VERSION ""

NS_ :

BS_:

BU_: BMS CVC_P EVCC FMCU RMCU POD_GW PCU ADCU_P DUMMY_ECU

BO_ 1555 BMS_DiagResp: 64 BMS
 SG_ BMS_DiagRespData0 : 7|8@0+ (1,0) [0|255] ""  CVC_P
 SG_ BMS_DiagRespData1 : 15|8@0+ (1,0) [0|255] ""  CVC_P
 SG_ BMS_DiagRespData2 : 23|8@0+ (1,0) [0|255] ""  CVC_P
 SG_ BMS_DiagRespData3 : 31|8@0+ (1,0) [0|255] ""  CVC_P
 SG_ BMS_DiagRespData4 : 39|8@0+ (1,0) [0|255] ""  CVC_P
 SG_ BMS_DiagRespData5 : 47|8@0+ (1,0) [0|255] ""  CVC_P
 SG_ BMS_DiagRespData6 : 55|8@0+ (1,0) [0|255] ""  CVC_P
 SG_ BMS_DiagRespData7 : 63|8@0+ (1,0) [0|255] ""  CVC_P
 SG_ BMS_DiagRespData8 : 71|8@0+ (1,0) [0|255] ""  CVC_P
 SG_ BMS_DiagRespData9 : 79|8@0+ (1,0) [0|255] ""  CVC_P
 SG_ BMS_DiagRespData10 : 87|8@0+ (1,0) [0|255] ""  CVC_P
 SG_ BMS_DiagRespData11 : 95|8@0+ (1,0) [0|255] ""  CVC_P
 SG_ BMS_DiagRespData12 : 103|8@0+ (1,0) [0|255] ""  CVC_P
 SG_ BMS_DiagRespData13 : 111|8@0+ (1,0) [0|255] ""  CVC_P
 SG_ BMS_DiagRespData14 : 119|8@0+ (1,0) [0|255] ""  CVC_P
 SG_ BMS_DiagRespData15 : 127|8@0+ (1,0) [0|255] ""  CVC_P
 SG_ BMS_DiagRespData16 : 135|8@0+ (1,0) [0|255] ""  CVC_P
 SG_ BMS_DiagRespData17 : 143|8@0+ (1,0) [0|255] ""  CVC_P
 SG_ BMS_DiagRespData18 : 151|8@0+ (1,0) [0|255] ""  CVC_P
 SG_ BMS_DiagRespData19 : 159|8@0+ (1,0) [0|255] ""  CVC_P
 SG_ BMS_DiagRespData20 : 167|8@0+ (1,0) [0|255] ""  CVC_P
 SG_ BMS_DiagRespData21 : 175|8@0+ (1,0) [0|255] ""  CVC_P
 SG_ BMS_DiagRespData22 : 183|8@0+ (1,0) [0|255] ""  CVC_P
 SG_ BMS_DiagRespData23 : 191|8@0+ (1,0) [0|255] ""  CVC_P
 SG_ BMS_DiagRespData24 : 199|8@0+ (1,0) [0|255] ""  CVC_P
 SG_ BMS_DiagRespData25 : 207|8@0+ (1,0) [0|255] ""  CVC_P
 SG_ BMS_DiagRespData26 : 215|8@0+ (1,0) [0|255] ""  CVC_P
 SG_ BMS_DiagRespData27 : 223|8@0+ (1,0) [0|255] ""  CVC_P
 SG_ BMS_DiagRespData28 : 231|8@0+ (1,0) [0|255] ""  CVC_P
 SG_ BMS_DiagRespData29 : 239|8@0+ (1,0) [0|255] ""  CVC_P
 SG_ BMS_DiagRespData30 : 247|8@0+ (1,0) [0|255] ""  CVC_P
 SG_ BMS_DiagRespData31 : 255|8@0+ (1,0) [0|255] ""  CVC_P
 SG_ BMS_DiagRespData32 : 263|8@0+ (1,0) [0|255] ""  CVC_P
 SG_ BMS_DiagRespData33 : 271|8@0+ (1,0) [0|255] ""  CVC_P
 SG_ BMS_DiagRespData34 : 279|8@0+ (1,0) [0|255] ""  CVC_P
 SG_ BMS_DiagRespData35 : 287|8@0+ (1,0) [0|255] ""  CVC_P
 SG_ BMS_DiagRespData36 : 295|8@0+ (1,0) [0|255] ""  CVC_P
 SG_ BMS_DiagRespData37 : 303|8@0+ (1,0) [0|255] ""  CVC_P
 SG_ BMS_DiagRespData38 : 311|8@0+ (1,0) [0|255] ""  CVC_P
 SG_ BMS_DiagRespData39 : 319|8@0+ (1,0) [0|255] ""  CVC_P
 SG_ BMS_DiagRespData40 : 327|8@0+ (1,0) [0|255] ""  CVC_P
 SG_ BMS_DiagRespData41 : 335|8@0+ (1,0) [0|255] ""  CVC_P
 SG_ BMS_DiagRespData42 : 343|8@0+ (1,0) [0|255] ""  CVC_P
 SG_ BMS_DiagRespData43 : 351|8@0+ (1,0) [0|255] ""  CVC_P
 SG_ BMS_DiagRespData44 : 359|8@0+ (1,0) [0|255] ""  CVC_P
 SG_ BMS_DiagRespData45 : 367|8@0+ (1,0) [0|255] ""  CVC_P
 SG_ BMS_DiagRespData46 : 375|8@0+ (1,0) [0|255] ""  CVC_P
 SG_ BMS_DiagRespData47 : 383|8@0+ (1,0) [0|255] ""  CVC_P
 SG_ BMS_DiagRespData48 : 391|8@0+ (1,0) [0|255] ""  CVC_P
 SG_ BMS_DiagRespData49 : 399|8@0+ (1,0) [0|255] ""  CVC_P
 SG_ BMS_DiagRespData50 : 407|8@0+ (1,0) [0|255] ""  CVC_P
 SG_ BMS_DiagRespData51 : 415|8@0+ (1,0) [0|255] ""  CVC_P
 SG_ BMS_DiagRespData52 : 423|8@0+ (1,0) [0|255] ""  CVC_P
 SG_ BMS_DiagRespData53 : 431|8@0+ (1,0) [0|255] ""  CVC_P
 SG_ BMS_DiagRespData54 : 439|8@0+ (1,0) [0|255] ""  CVC_P
 SG_ BMS_DiagRespData55 : 447|8@0+ (1,0) [0|255] ""  CVC_P
 SG_ BMS_DiagRespData56 : 455|8@0+ (1,0) [0|255] ""  CVC_P
 SG_ BMS_DiagRespData57 : 463|8@0+ (1,0) [0|255] ""  CVC_P
 SG_ BMS_DiagRespData58 : 471|8@0+ (1,0) [0|255] ""  CVC_P
 SG_ BMS_DiagRespData59 : 479|8@0+ (1,0) [0|255] ""  CVC_P
 SG_ BMS_DiagRespData60 : 487|8@0+ (1,0) [0|255] ""  CVC_P
 SG_ BMS_DiagRespData61 : 495|8@0+ (1,0) [0|255] ""  CVC_P
 SG_ BMS_DiagRespData62 : 503|8@0+ (1,0) [0|255] ""  CVC_P
 SG_ BMS_DiagRespData63 : 511|8@0+ (1,0) [0|255] ""  CVC_P

BO_ 1690 RMCU_DiagReq: 64 CVC_P
 SG_ RMCU_DiagReqData0 : 7|8@0+ (1,0) [0|255] ""  RMCU
 SG_ RMCU_DiagReqData1 : 15|8@0+ (1,0) [0|255] ""  RMCU
 SG_ RMCU_DiagReqData2 : 23|8@0+ (1,0) [0|255] ""  RMCU
 SG_ RMCU_DiagReqData3 : 31|8@0+ (1,0) [0|255] ""  RMCU
 SG_ RMCU_DiagReqData4 : 39|8@0+ (1,0) [0|255] ""  RMCU
 SG_ RMCU_DiagReqData5 : 47|8@0+ (1,0) [0|255] ""  RMCU
 SG_ RMCU_DiagReqData6 : 55|8@0+ (1,0) [0|255] ""  RMCU
 SG_ RMCU_DiagReqData7 : 63|8@0+ (1,0) [0|255] ""  RMCU
 SG_ RMCU_DiagReqData8 : 71|8@0+ (1,0) [0|255] ""  RMCU
 SG_ RMCU_DiagReqData9 : 79|8@0+ (1,0) [0|255] ""  RMCU
 SG_ RMCU_DiagReqData10 : 87|8@0+ (1,0) [0|255] ""  RMCU
 SG_ RMCU_DiagReqData11 : 95|8@0+ (1,0) [0|255] ""  RMCU
 SG_ RMCU_DiagReqData12 : 103|8@0+ (1,0) [0|255] ""  RMCU
 SG_ RMCU_DiagReqData13 : 111|8@0+ (1,0) [0|255] ""  RMCU
 SG_ RMCU_DiagReqData14 : 119|8@0+ (1,0) [0|255] ""  RMCU
 SG_ RMCU_DiagReqData15 : 127|8@0+ (1,0) [0|255] ""  RMCU
 SG_ RMCU_DiagReqData16 : 135|8@0+ (1,0) [0|255] ""  RMCU
 SG_ RMCU_DiagReqData17 : 143|8@0+ (1,0) [0|255] ""  RMCU
 SG_ RMCU_DiagReqData18 : 151|8@0+ (1,0) [0|255] ""  RMCU
 SG_ RMCU_DiagReqData19 : 159|8@0+ (1,0) [0|255] ""  RMCU
 SG_ RMCU_DiagReqData20 : 167|8@0+ (1,0) [0|255] ""  RMCU
 SG_ RMCU_DiagReqData21 : 175|8@0+ (1,0) [0|255] ""  RMCU
 SG_ RMCU_DiagReqData22 : 183|8@0+ (1,0) [0|255] ""  RMCU
 SG_ RMCU_DiagReqData23 : 191|8@0+ (1,0) [0|255] ""  RMCU
 SG_ RMCU_DiagReqData24 : 199|8@0+ (1,0) [0|255] ""  RMCU
 SG_ RMCU_DiagReqData25 : 207|8@0+ (1,0) [0|255] ""  RMCU
 SG_ RMCU_DiagReqData26 : 215|8@0+ (1,0) [0|255] ""  RMCU
 SG_ RMCU_DiagReqData27 : 223|8@0+ (1,0) [0|255] ""  RMCU
 SG_ RMCU_DiagReqData28 : 231|8@0+ (1,0) [0|255] ""  RMCU
 SG_ RMCU_DiagReqData29 : 239|8@0+ (1,0) [0|255] ""  RMCU
 SG_ RMCU_DiagReqData30 : 247|8@0+ (1,0) [0|255] ""  RMCU
 SG_ RMCU_DiagReqData31 : 255|8@0+ (1,0) [0|255] ""  RMCU
 SG_ RMCU_DiagReqData32 : 263|8@0+ (1,0) [0|255] ""  RMCU
 SG_ RMCU_DiagReqData33 : 271|8@0+ (1,0) [0|255] ""  RMCU
 SG_ RMCU_DiagReqData34 : 279|8@0+ (1,0) [0|255] ""  RMCU
 SG_ RMCU_DiagReqData35 : 287|8@0+ (1,0) [0|255] ""  RMCU
 SG_ RMCU_DiagReqData36 : 295|8@0+ (1,0) [0|255] ""  RMCU
 SG_ RMCU_DiagReqData37 : 303|8@0+ (1,0) [0|255] ""  RMCU
 SG_ RMCU_DiagReqData38 : 311|8@0+ (1,0) [0|255] ""  RMCU
 SG_ RMCU_DiagReqData39 : 319|8@0+ (1,0) [0|255] ""  RMCU
 SG_ RMCU_DiagReqData40 : 327|8@0+ (1,0) [0|255] ""  RMCU
 SG_ RMCU_DiagReqData41 : 335|8@0+ (1,0) [0|255] ""  RMCU
 SG_ RMCU_DiagReqData42 : 343|8@0+ (1,0) [0|255] ""  RMCU
 SG_ RMCU_DiagReqData43 : 351|8@0+ (1,0) [0|255] ""  RMCU
 SG_ RMCU_DiagReqData44 : 359|8@0+ (1,0) [0|255] ""  RMCU
 SG_ RMCU_DiagReqData45 : 367|8@0+ (1,0) [0|255] ""  RMCU
 SG_ RMCU_DiagReqData46 : 375|8@0+ (1,0) [0|255] ""  RMCU
 SG_ RMCU_DiagReqData47 : 383|8@0+ (1,0) [0|255] ""  RMCU
 SG_ RMCU_DiagReqData48 : 391|8@0+ (1,0) [0|255] ""  RMCU
 SG_ RMCU_DiagReqData49 : 399|8@0+ (1,0) [0|255] ""  RMCU
 SG_ RMCU_DiagReqData50 : 407|8@0+ (1,0) [0|255] ""  RMCU
 SG_ RMCU_DiagReqData51 : 415|8@0+ (1,0) [0|255] ""  RMCU
 SG_ RMCU_DiagReqData52 : 423|8@0+ (1,0) [0|255] ""  RMCU
 SG_ RMCU_DiagReqData53 : 431|8@0+ (1,0) [0|255] ""  RMCU
 SG_ RMCU_DiagReqData54 : 439|8@0+ (1,0) [0|255] ""  RMCU
 SG_ RMCU_DiagReqData55 : 447|8@0+ (1,0) [0|255] ""  RMCU
 SG_ RMCU_DiagReqData56 : 455|8@0+ (1,0) [0|255] ""  RMCU
 SG_ RMCU_DiagReqData57 : 463|8@0+ (1,0) [0|255] ""  RMCU
 SG_ RMCU_DiagReqData58 : 471|8@0+ (1,0) [0|255] ""  RMCU
 SG_ RMCU_DiagReqData59 : 479|8@0+ (1,0) [0|255] ""  RMCU
 SG_ RMCU_DiagReqData60 : 487|8@0+ (1,0) [0|255] ""  RMCU
 SG_ RMCU_DiagReqData61 : 495|8@0+ (1,0) [0|255] ""  RMCU
 SG_ RMCU_DiagReqData62 : 503|8@0+ (1,0) [0|255] ""  RMCU
 SG_ RMCU_DiagReqData63 : 511|8@0+ (1,0) [0|255] ""  RMCU

BO_ 1562 RMCU_DiagResp: 64 RMCU
 SG_ RMCU_DiagRespData0 : 7|8@0+ (1,0) [0|255] ""  CVC_P
 SG_ RMCU_DiagRespData1 : 15|8@0+ (1,0) [0|255] ""  CVC_P
 SG_ RMCU_DiagRespData2 : 23|8@0+ (1,0) [0|255] ""  CVC_P
 SG_ RMCU_DiagRespData3 : 31|8@0+ (1,0) [0|255] ""  CVC_P
 SG_ RMCU_DiagRespData4 : 39|8@0+ (1,0) [0|255] ""  CVC_P
 SG_ RMCU_DiagRespData5 : 47|8@0+ (1,0) [0|255] ""  CVC_P
 SG_ RMCU_DiagRespData6 : 55|8@0+ (1,0) [0|255] ""  CVC_P
 SG_ RMCU_DiagRespData7 : 63|8@0+ (1,0) [0|255] ""  CVC_P
 SG_ RMCU_DiagRespData8 : 71|8@0+ (1,0) [0|255] ""  CVC_P
 SG_ RMCU_DiagRespData9 : 79|8@0+ (1,0) [0|255] ""  CVC_P
 SG_ RMCU_DiagRespData10 : 87|8@0+ (1,0) [0|255] ""  CVC_P
 SG_ RMCU_DiagRespData11 : 95|8@0+ (1,0) [0|255] ""  CVC_P
 SG_ RMCU_DiagRespData12 : 103|8@0+ (1,0) [0|255] ""  CVC_P
 SG_ RMCU_DiagRespData13 : 111|8@0+ (1,0) [0|255] ""  CVC_P
 SG_ RMCU_DiagRespData14 : 119|8@0+ (1,0) [0|255] ""  CVC_P
 SG_ RMCU_DiagRespData15 : 127|8@0+ (1,0) [0|255] ""  CVC_P
 SG_ RMCU_DiagRespData16 : 135|8@0+ (1,0) [0|255] ""  CVC_P
 SG_ RMCU_DiagRespData17 : 143|8@0+ (1,0) [0|255] ""  CVC_P
 SG_ RMCU_DiagRespData18 : 151|8@0+ (1,0) [0|255] ""  CVC_P
 SG_ RMCU_DiagRespData19 : 159|8@0+ (1,0) [0|255] ""  CVC_P
 SG_ RMCU_DiagRespData20 : 167|8@0+ (1,0) [0|255] ""  CVC_P
 SG_ RMCU_DiagRespData21 : 175|8@0+ (1,0) [0|255] ""  CVC_P
 SG_ RMCU_DiagRespData22 : 183|8@0+ (1,0) [0|255] ""  CVC_P
 SG_ RMCU_DiagRespData23 : 191|8@0+ (1,0) [0|255] ""  CVC_P
 SG_ RMCU_DiagRespData24 : 199|8@0+ (1,0) [0|255] ""  CVC_P
 SG_ RMCU_DiagRespData25 : 207|8@0+ (1,0) [0|255] ""  CVC_P
 SG_ RMCU_DiagRespData26 : 215|8@0+ (1,0) [0|255] ""  CVC_P
 SG_ RMCU_DiagRespData27 : 223|8@0+ (1,0) [0|255] ""  CVC_P
 SG_ RMCU_DiagRespData28 : 231|8@0+ (1,0) [0|255] ""  CVC_P
 SG_ RMCU_DiagRespData29 : 239|8@0+ (1,0) [0|255] ""  CVC_P
 SG_ RMCU_DiagRespData30 : 247|8@0+ (1,0) [0|255] ""  CVC_P
 SG_ RMCU_DiagRespData31 : 255|8@0+ (1,0) [0|255] ""  CVC_P
 SG_ RMCU_DiagRespData32 : 263|8@0+ (1,0) [0|255] ""  CVC_P
 SG_ RMCU_DiagRespData33 : 271|8@0+ (1,0) [0|255] ""  CVC_P
 SG_ RMCU_DiagRespData34 : 279|8@0+ (1,0) [0|255] ""  CVC_P
 SG_ RMCU_DiagRespData35 : 287|8@0+ (1,0) [0|255] ""  CVC_P
 SG_ RMCU_DiagRespData36 : 295|8@0+ (1,0) [0|255] ""  CVC_P
 SG_ RMCU_DiagRespData37 : 303|8@0+ (1,0) [0|255] ""  CVC_P
 SG_ RMCU_DiagRespData38 : 311|8@0+ (1,0) [0|255] ""  CVC_P
 SG_ RMCU_DiagRespData39 : 319|8@0+ (1,0) [0|255] ""  CVC_P
 SG_ RMCU_DiagRespData40 : 327|8@0+ (1,0) [0|255] ""  CVC_P
 SG_ RMCU_DiagRespData41 : 335|8@0+ (1,0) [0|255] ""  CVC_P
 SG_ RMCU_DiagRespData42 : 343|8@0+ (1,0) [0|255] ""  CVC_P
 SG_ RMCU_DiagRespData43 : 351|8@0+ (1,0) [0|255] ""  CVC_P
 SG_ RMCU_DiagRespData44 : 359|8@0+ (1,0) [0|255] ""  CVC_P
 SG_ RMCU_DiagRespData45 : 367|8@0+ (1,0) [0|255] ""  CVC_P
 SG_ RMCU_DiagRespData46 : 375|8@0+ (1,0) [0|255] ""  CVC_P
 SG_ RMCU_DiagRespData47 : 383|8@0+ (1,0) [0|255] ""  CVC_P
 SG_ RMCU_DiagRespData48 : 391|8@0+ (1,0) [0|255] ""  CVC_P
 SG_ RMCU_DiagRespData49 : 399|8@0+ (1,0) [0|255] ""  CVC_P
 SG_ RMCU_DiagRespData50 : 407|8@0+ (1,0) [0|255] ""  CVC_P
 SG_ RMCU_DiagRespData51 : 415|8@0+ (1,0) [0|255] ""  CVC_P
 SG_ RMCU_DiagRespData52 : 423|8@0+ (1,0) [0|255] ""  CVC_P
 SG_ RMCU_DiagRespData53 : 431|8@0+ (1,0) [0|255] ""  CVC_P
 SG_ RMCU_DiagRespData54 : 439|8@0+ (1,0) [0|255] ""  CVC_P
 SG_ RMCU_DiagRespData55 : 447|8@0+ (1,0) [0|255] ""  CVC_P
 SG_ RMCU_DiagRespData56 : 455|8@0+ (1,0) [0|255] ""  CVC_P
 SG_ RMCU_DiagRespData57 : 463|8@0+ (1,0) [0|255] ""  CVC_P
 SG_ RMCU_DiagRespData58 : 471|8@0+ (1,0) [0|255] ""  CVC_P
 SG_ RMCU_DiagRespData59 : 479|8@0+ (1,0) [0|255] ""  CVC_P
 SG_ RMCU_DiagRespData60 : 487|8@0+ (1,0) [0|255] ""  CVC_P
 SG_ RMCU_DiagRespData61 : 495|8@0+ (1,0) [0|255] ""  CVC_P
 SG_ RMCU_DiagRespData62 : 503|8@0+ (1,0) [0|255] ""  CVC_P
 SG_ RMCU_DiagRespData63 : 511|8@0+ (1,0) [0|255] ""  CVC_P

BO_ 1691 FMCU_DiagReq: 64 CVC_P
 SG_ FMCU_DiagReqData0 : 7|8@0+ (1,0) [0|255] ""  FMCU
 SG_ FMCU_DiagReqData1 : 15|8@0+ (1,0) [0|255] ""  FMCU
 SG_ FMCU_DiagReqData2 : 23|8@0+ (1,0) [0|255] ""  FMCU
 SG_ FMCU_DiagReqData3 : 31|8@0+ (1,0) [0|255] ""  FMCU
 SG_ FMCU_DiagReqData4 : 39|8@0+ (1,0) [0|255] ""  FMCU
 SG_ FMCU_DiagReqData5 : 47|8@0+ (1,0) [0|255] ""  FMCU
 SG_ FMCU_DiagReqData6 : 55|8@0+ (1,0) [0|255] ""  FMCU
 SG_ FMCU_DiagReqData7 : 63|8@0+ (1,0) [0|255] ""  FMCU
 SG_ FMCU_DiagReqData8 : 71|8@0+ (1,0) [0|255] ""  FMCU
 SG_ FMCU_DiagReqData9 : 79|8@0+ (1,0) [0|255] ""  FMCU
 SG_ FMCU_DiagReqData10 : 87|8@0+ (1,0) [0|255] ""  FMCU
 SG_ FMCU_DiagReqData11 : 95|8@0+ (1,0) [0|255] ""  FMCU
 SG_ FMCU_DiagReqData12 : 103|8@0+ (1,0) [0|255] ""  FMCU
 SG_ FMCU_DiagReqData13 : 111|8@0+ (1,0) [0|255] ""  FMCU
 SG_ FMCU_DiagReqData14 : 119|8@0+ (1,0) [0|255] ""  FMCU
 SG_ FMCU_DiagReqData15 : 127|8@0+ (1,0) [0|255] ""  FMCU
 SG_ FMCU_DiagReqData16 : 135|8@0+ (1,0) [0|255] ""  FMCU
 SG_ FMCU_DiagReqData17 : 143|8@0+ (1,0) [0|255] ""  FMCU
 SG_ FMCU_DiagReqData18 : 151|8@0+ (1,0) [0|255] ""  FMCU
 SG_ FMCU_DiagReqData19 : 159|8@0+ (1,0) [0|255] ""  FMCU
 SG_ FMCU_DiagReqData20 : 167|8@0+ (1,0) [0|255] ""  FMCU
 SG_ FMCU_DiagReqData21 : 175|8@0+ (1,0) [0|255] ""  FMCU
 SG_ FMCU_DiagReqData22 : 183|8@0+ (1,0) [0|255] ""  FMCU
 SG_ FMCU_DiagReqData23 : 191|8@0+ (1,0) [0|255] ""  FMCU
 SG_ FMCU_DiagReqData24 : 199|8@0+ (1,0) [0|255] ""  FMCU
 SG_ FMCU_DiagReqData25 : 207|8@0+ (1,0) [0|255] ""  FMCU
 SG_ FMCU_DiagReqData26 : 215|8@0+ (1,0) [0|255] ""  FMCU
 SG_ FMCU_DiagReqData27 : 223|8@0+ (1,0) [0|255] ""  FMCU
 SG_ FMCU_DiagReqData28 : 231|8@0+ (1,0) [0|255] ""  FMCU
 SG_ FMCU_DiagReqData29 : 239|8@0+ (1,0) [0|255] ""  FMCU
 SG_ FMCU_DiagReqData30 : 247|8@0+ (1,0) [0|255] ""  FMCU
 SG_ FMCU_DiagReqData31 : 255|8@0+ (1,0) [0|255] ""  FMCU
 SG_ FMCU_DiagReqData32 : 263|8@0+ (1,0) [0|255] ""  FMCU
 SG_ FMCU_DiagReqData33 : 271|8@0+ (1,0) [0|255] ""  FMCU
 SG_ FMCU_DiagReqData34 : 279|8@0+ (1,0) [0|255] ""  FMCU
 SG_ FMCU_DiagReqData35 : 287|8@0+ (1,0) [0|255] ""  FMCU
 SG_ FMCU_DiagReqData36 : 295|8@0+ (1,0) [0|255] ""  FMCU
 SG_ FMCU_DiagReqData37 : 303|8@0+ (1,0) [0|255] ""  FMCU
 SG_ FMCU_DiagReqData38 : 311|8@0+ (1,0) [0|255] ""  FMCU
 SG_ FMCU_DiagReqData39 : 319|8@0+ (1,0) [0|255] ""  FMCU
 SG_ FMCU_DiagReqData40 : 327|8@0+ (1,0) [0|255] ""  FMCU
 SG_ FMCU_DiagReqData41 : 335|8@0+ (1,0) [0|255] ""  FMCU
 SG_ FMCU_DiagReqData42 : 343|8@0+ (1,0) [0|255] ""  FMCU
 SG_ FMCU_DiagReqData43 : 351|8@0+ (1,0) [0|255] ""  FMCU
 SG_ FMCU_DiagReqData44 : 359|8@0+ (1,0) [0|255] ""  FMCU
 SG_ FMCU_DiagReqData45 : 367|8@0+ (1,0) [0|255] ""  FMCU
 SG_ FMCU_DiagReqData46 : 375|8@0+ (1,0) [0|255] ""  FMCU
 SG_ FMCU_DiagReqData47 : 383|8@0+ (1,0) [0|255] ""  FMCU
 SG_ FMCU_DiagReqData48 : 391|8@0+ (1,0) [0|255] ""  FMCU
 SG_ FMCU_DiagReqData49 : 399|8@0+ (1,0) [0|255] ""  FMCU
 SG_ FMCU_DiagReqData50 : 407|8@0+ (1,0) [0|255] ""  FMCU
 SG_ FMCU_DiagReqData51 : 415|8@0+ (1,0) [0|255] ""  FMCU
 SG_ FMCU_DiagReqData52 : 423|8@0+ (1,0) [0|255] ""  FMCU
 SG_ FMCU_DiagReqData53 : 431|8@0+ (1,0) [0|255] ""  FMCU
 SG_ FMCU_DiagReqData54 : 439|8@0+ (1,0) [0|255] ""  FMCU
 SG_ FMCU_DiagReqData55 : 447|8@0+ (1,0) [0|255] ""  FMCU
 SG_ FMCU_DiagReqData56 : 455|8@0+ (1,0) [0|255] ""  FMCU
 SG_ FMCU_DiagReqData57 : 463|8@0+ (1,0) [0|255] ""  FMCU
 SG_ FMCU_DiagReqData58 : 471|8@0+ (1,0) [0|255] ""  FMCU
 SG_ FMCU_DiagReqData59 : 479|8@0+ (1,0) [0|255] ""  FMCU
 SG_ FMCU_DiagReqData60 : 487|8@0+ (1,0) [0|255] ""  FMCU
 SG_ FMCU_DiagReqData61 : 495|8@0+ (1,0) [0|255] ""  FMCU
 SG_ FMCU_DiagReqData62 : 503|8@0+ (1,0) [0|255] ""  FMCU
 SG_ FMCU_DiagReqData63 : 511|8@0+ (1,0) [0|255] ""  FMCU

BO_ 1563 FMCU_DiagResp: 64 FMCU
 SG_ FMCU_DiagRespData0 : 7|8@0+ (1,0) [0|255] ""  CVC_P
 SG_ FMCU_DiagRespData1 : 15|8@0+ (1,0) [0|255] ""  CVC_P
 SG_ FMCU_DiagRespData2 : 23|8@0+ (1,0) [0|255] ""  CVC_P
 SG_ FMCU_DiagRespData3 : 31|8@0+ (1,0) [0|255] ""  CVC_P
 SG_ FMCU_DiagRespData4 : 39|8@0+ (1,0) [0|255] ""  CVC_P
 SG_ FMCU_DiagRespData5 : 47|8@0+ (1,0) [0|255] ""  CVC_P
 SG_ FMCU_DiagRespData6 : 55|8@0+ (1,0) [0|255] ""  CVC_P
 SG_ FMCU_DiagRespData7 : 63|8@0+ (1,0) [0|255] ""  CVC_P
 SG_ FMCU_DiagRespData8 : 71|8@0+ (1,0) [0|255] ""  CVC_P
 SG_ FMCU_DiagRespData9 : 79|8@0+ (1,0) [0|255] ""  CVC_P
 SG_ FMCU_DiagRespData10 : 87|8@0+ (1,0) [0|255] ""  CVC_P
 SG_ FMCU_DiagRespData11 : 95|8@0+ (1,0) [0|255] ""  CVC_P
 SG_ FMCU_DiagRespData12 : 103|8@0+ (1,0) [0|255] ""  CVC_P
 SG_ FMCU_DiagRespData13 : 111|8@0+ (1,0) [0|255] ""  CVC_P
 SG_ FMCU_DiagRespData14 : 119|8@0+ (1,0) [0|255] ""  CVC_P
 SG_ FMCU_DiagRespData15 : 127|8@0+ (1,0) [0|255] ""  CVC_P
 SG_ FMCU_DiagRespData16 : 135|8@0+ (1,0) [0|255] ""  CVC_P
 SG_ FMCU_DiagRespData17 : 143|8@0+ (1,0) [0|255] ""  CVC_P
 SG_ FMCU_DiagRespData18 : 151|8@0+ (1,0) [0|255] ""  CVC_P
 SG_ FMCU_DiagRespData19 : 159|8@0+ (1,0) [0|255] ""  CVC_P
 SG_ FMCU_DiagRespData20 : 167|8@0+ (1,0) [0|255] ""  CVC_P
 SG_ FMCU_DiagRespData21 : 175|8@0+ (1,0) [0|255] ""  CVC_P
 SG_ FMCU_DiagRespData22 : 183|8@0+ (1,0) [0|255] ""  CVC_P
 SG_ FMCU_DiagRespData23 : 191|8@0+ (1,0) [0|255] ""  CVC_P
 SG_ FMCU_DiagRespData24 : 199|8@0+ (1,0) [0|255] ""  CVC_P
 SG_ FMCU_DiagRespData25 : 207|8@0+ (1,0) [0|255] ""  CVC_P
 SG_ FMCU_DiagRespData26 : 215|8@0+ (1,0) [0|255] ""  CVC_P
 SG_ FMCU_DiagRespData27 : 223|8@0+ (1,0) [0|255] ""  CVC_P
 SG_ FMCU_DiagRespData28 : 231|8@0+ (1,0) [0|255] ""  CVC_P
 SG_ FMCU_DiagRespData29 : 239|8@0+ (1,0) [0|255] ""  CVC_P
 SG_ FMCU_DiagRespData30 : 247|8@0+ (1,0) [0|255] ""  CVC_P
 SG_ FMCU_DiagRespData31 : 255|8@0+ (1,0) [0|255] ""  CVC_P
 SG_ FMCU_DiagRespData32 : 263|8@0+ (1,0) [0|255] ""  CVC_P
 SG_ FMCU_DiagRespData33 : 271|8@0+ (1,0) [0|255] ""  CVC_P
 SG_ FMCU_DiagRespData34 : 279|8@0+ (1,0) [0|255] ""  CVC_P
 SG_ FMCU_DiagRespData35 : 287|8@0+ (1,0) [0|255] ""  CVC_P
 SG_ FMCU_DiagRespData36 : 295|8@0+ (1,0) [0|255] ""  CVC_P
 SG_ FMCU_DiagRespData37 : 303|8@0+ (1,0) [0|255] ""  CVC_P
 SG_ FMCU_DiagRespData38 : 311|8@0+ (1,0) [0|255] ""  CVC_P
 SG_ FMCU_DiagRespData39 : 319|8@0+ (1,0) [0|255] ""  CVC_P
 SG_ FMCU_DiagRespData40 : 327|8@0+ (1,0) [0|255] ""  CVC_P
 SG_ FMCU_DiagRespData41 : 335|8@0+ (1,0) [0|255] ""  CVC_P
 SG_ FMCU_DiagRespData42 : 343|8@0+ (1,0) [0|255] ""  CVC_P
 SG_ FMCU_DiagRespData43 : 351|8@0+ (1,0) [0|255] ""  CVC_P
 SG_ FMCU_DiagRespData44 : 359|8@0+ (1,0) [0|255] ""  CVC_P
 SG_ FMCU_DiagRespData45 : 367|8@0+ (1,0) [0|255] ""  CVC_P
 SG_ FMCU_DiagRespData46 : 375|8@0+ (1,0) [0|255] ""  CVC_P
 SG_ FMCU_DiagRespData47 : 383|8@0+ (1,0) [0|255] ""  CVC_P
 SG_ FMCU_DiagRespData48 : 391|8@0+ (1,0) [0|255] ""  CVC_P
 SG_ FMCU_DiagRespData49 : 399|8@0+ (1,0) [0|255] ""  CVC_P
 SG_ FMCU_DiagRespData50 : 407|8@0+ (1,0) [0|255] ""  CVC_P
 SG_ FMCU_DiagRespData51 : 415|8@0+ (1,0) [0|255] ""  CVC_P
 SG_ FMCU_DiagRespData52 : 423|8@0+ (1,0) [0|255] ""  CVC_P
 SG_ FMCU_DiagRespData53 : 431|8@0+ (1,0) [0|255] ""  CVC_P
 SG_ FMCU_DiagRespData54 : 439|8@0+ (1,0) [0|255] ""  CVC_P
 SG_ FMCU_DiagRespData55 : 447|8@0+ (1,0) [0|255] ""  CVC_P
 SG_ FMCU_DiagRespData56 : 455|8@0+ (1,0) [0|255] ""  CVC_P
 SG_ FMCU_DiagRespData57 : 463|8@0+ (1,0) [0|255] ""  CVC_P
 SG_ FMCU_DiagRespData58 : 471|8@0+ (1,0) [0|255] ""  CVC_P
 SG_ FMCU_DiagRespData59 : 479|8@0+ (1,0) [0|255] ""  CVC_P
 SG_ FMCU_DiagRespData60 : 487|8@0+ (1,0) [0|255] ""  CVC_P
 SG_ FMCU_DiagRespData61 : 495|8@0+ (1,0) [0|255] ""  CVC_P
 SG_ FMCU_DiagRespData62 : 503|8@0+ (1,0) [0|255] ""  CVC_P
 SG_ FMCU_DiagRespData63 : 511|8@0+ (1,0) [0|255] ""  CVC_P

BO_ 1695 EVCC_DiagReq: 64 CVC_P
 SG_ EVCC_DiagReqData0 : 7|8@0+ (1,0) [0|255] ""  EVCC
 SG_ EVCC_DiagReqData1 : 15|8@0+ (1,0) [0|255] ""  EVCC
 SG_ EVCC_DiagReqData2 : 23|8@0+ (1,0) [0|255] ""  EVCC
 SG_ EVCC_DiagReqData3 : 31|8@0+ (1,0) [0|255] ""  EVCC
 SG_ EVCC_DiagReqData4 : 39|8@0+ (1,0) [0|255] ""  EVCC
 SG_ EVCC_DiagReqData5 : 47|8@0+ (1,0) [0|255] ""  EVCC
 SG_ EVCC_DiagReqData6 : 55|8@0+ (1,0) [0|255] ""  EVCC
 SG_ EVCC_DiagReqData7 : 63|8@0+ (1,0) [0|255] ""  EVCC
 SG_ EVCC_DiagReqData8 : 71|8@0+ (1,0) [0|255] ""  EVCC
 SG_ EVCC_DiagReqData9 : 79|8@0+ (1,0) [0|255] ""  EVCC
 SG_ EVCC_DiagReqData10 : 87|8@0+ (1,0) [0|255] ""  EVCC
 SG_ EVCC_DiagReqData11 : 95|8@0+ (1,0) [0|255] ""  EVCC
 SG_ EVCC_DiagReqData12 : 103|8@0+ (1,0) [0|255] ""  EVCC
 SG_ EVCC_DiagReqData13 : 111|8@0+ (1,0) [0|255] ""  EVCC
 SG_ EVCC_DiagReqData14 : 119|8@0+ (1,0) [0|255] ""  EVCC
 SG_ EVCC_DiagReqData15 : 127|8@0+ (1,0) [0|255] ""  EVCC
 SG_ EVCC_DiagReqData16 : 135|8@0+ (1,0) [0|255] ""  EVCC
 SG_ EVCC_DiagReqData17 : 143|8@0+ (1,0) [0|255] ""  EVCC
 SG_ EVCC_DiagReqData18 : 151|8@0+ (1,0) [0|255] ""  EVCC
 SG_ EVCC_DiagReqData19 : 159|8@0+ (1,0) [0|255] ""  EVCC
 SG_ EVCC_DiagReqData20 : 167|8@0+ (1,0) [0|255] ""  EVCC
 SG_ EVCC_DiagReqData21 : 175|8@0+ (1,0) [0|255] ""  EVCC
 SG_ EVCC_DiagReqData22 : 183|8@0+ (1,0) [0|255] ""  EVCC
 SG_ EVCC_DiagReqData23 : 191|8@0+ (1,0) [0|255] ""  EVCC
 SG_ EVCC_DiagReqData24 : 199|8@0+ (1,0) [0|255] ""  EVCC
 SG_ EVCC_DiagReqData25 : 207|8@0+ (1,0) [0|255] ""  EVCC
 SG_ EVCC_DiagReqData26 : 215|8@0+ (1,0) [0|255] ""  EVCC
 SG_ EVCC_DiagReqData27 : 223|8@0+ (1,0) [0|255] ""  EVCC
 SG_ EVCC_DiagReqData28 : 231|8@0+ (1,0) [0|255] ""  EVCC
 SG_ EVCC_DiagReqData29 : 239|8@0+ (1,0) [0|255] ""  EVCC
 SG_ EVCC_DiagReqData30 : 247|8@0+ (1,0) [0|255] ""  EVCC
 SG_ EVCC_DiagReqData31 : 255|8@0+ (1,0) [0|255] ""  EVCC
 SG_ EVCC_DiagReqData32 : 263|8@0+ (1,0) [0|255] ""  EVCC
 SG_ EVCC_DiagReqData33 : 271|8@0+ (1,0) [0|255] ""  EVCC
 SG_ EVCC_DiagReqData34 : 279|8@0+ (1,0) [0|255] ""  EVCC
 SG_ EVCC_DiagReqData35 : 287|8@0+ (1,0) [0|255] ""  EVCC
 SG_ EVCC_DiagReqData36 : 295|8@0+ (1,0) [0|255] ""  EVCC
 SG_ EVCC_DiagReqData37 : 303|8@0+ (1,0) [0|255] ""  EVCC
 SG_ EVCC_DiagReqData38 : 311|8@0+ (1,0) [0|255] ""  EVCC
 SG_ EVCC_DiagReqData39 : 319|8@0+ (1,0) [0|255] ""  EVCC
 SG_ EVCC_DiagReqData40 : 327|8@0+ (1,0) [0|255] ""  EVCC
 SG_ EVCC_DiagReqData41 : 335|8@0+ (1,0) [0|255] ""  EVCC
 SG_ EVCC_DiagReqData42 : 343|8@0+ (1,0) [0|255] ""  EVCC
 SG_ EVCC_DiagReqData43 : 351|8@0+ (1,0) [0|255] ""  EVCC
 SG_ EVCC_DiagReqData44 : 359|8@0+ (1,0) [0|255] ""  EVCC
 SG_ EVCC_DiagReqData45 : 367|8@0+ (1,0) [0|255] ""  EVCC
 SG_ EVCC_DiagReqData46 : 375|8@0+ (1,0) [0|255] ""  EVCC
 SG_ EVCC_DiagReqData47 : 383|8@0+ (1,0) [0|255] ""  EVCC
 SG_ EVCC_DiagReqData48 : 391|8@0+ (1,0) [0|255] ""  EVCC
 SG_ EVCC_DiagReqData49 : 399|8@0+ (1,0) [0|255] ""  EVCC
 SG_ EVCC_DiagReqData50 : 407|8@0+ (1,0) [0|255] ""  EVCC
 SG_ EVCC_DiagReqData51 : 415|8@0+ (1,0) [0|255] ""  EVCC
 SG_ EVCC_DiagReqData52 : 423|8@0+ (1,0) [0|255] ""  EVCC
 SG_ EVCC_DiagReqData53 : 431|8@0+ (1,0) [0|255] ""  EVCC
 SG_ EVCC_DiagReqData54 : 439|8@0+ (1,0) [0|255] ""  EVCC
 SG_ EVCC_DiagReqData55 : 447|8@0+ (1,0) [0|255] ""  EVCC
 SG_ EVCC_DiagReqData56 : 455|8@0+ (1,0) [0|255] ""  EVCC
 SG_ EVCC_DiagReqData57 : 463|8@0+ (1,0) [0|255] ""  EVCC
 SG_ EVCC_DiagReqData58 : 471|8@0+ (1,0) [0|255] ""  EVCC
 SG_ EVCC_DiagReqData59 : 479|8@0+ (1,0) [0|255] ""  EVCC
 SG_ EVCC_DiagReqData60 : 487|8@0+ (1,0) [0|255] ""  EVCC
 SG_ EVCC_DiagReqData61 : 495|8@0+ (1,0) [0|255] ""  EVCC
 SG_ EVCC_DiagReqData62 : 503|8@0+ (1,0) [0|255] ""  EVCC
 SG_ EVCC_DiagReqData63 : 511|8@0+ (1,0) [0|255] ""  EVCC

BO_ 1567 EVCC_DiagResp: 64 EVCC
 SG_ EVCC_DiagRespData0 : 7|8@0+ (1,0) [0|255] ""  CVC_P
 SG_ EVCC_DiagRespData1 : 15|8@0+ (1,0) [0|255] ""  CVC_P
 SG_ EVCC_DiagRespData2 : 23|8@0+ (1,0) [0|255] ""  CVC_P
 SG_ EVCC_DiagRespData3 : 31|8@0+ (1,0) [0|255] ""  CVC_P
 SG_ EVCC_DiagRespData4 : 39|8@0+ (1,0) [0|255] ""  CVC_P
 SG_ EVCC_DiagRespData5 : 47|8@0+ (1,0) [0|255] ""  CVC_P
 SG_ EVCC_DiagRespData6 : 55|8@0+ (1,0) [0|255] ""  CVC_P
 SG_ EVCC_DiagRespData7 : 63|8@0+ (1,0) [0|255] ""  CVC_P
 SG_ EVCC_DiagRespData8 : 71|8@0+ (1,0) [0|255] ""  CVC_P
 SG_ EVCC_DiagRespData9 : 79|8@0+ (1,0) [0|255] ""  CVC_P
 SG_ EVCC_DiagRespData10 : 87|8@0+ (1,0) [0|255] ""  CVC_P
 SG_ EVCC_DiagRespData11 : 95|8@0+ (1,0) [0|255] ""  CVC_P
 SG_ EVCC_DiagRespData12 : 103|8@0+ (1,0) [0|255] ""  CVC_P
 SG_ EVCC_DiagRespData13 : 111|8@0+ (1,0) [0|255] ""  CVC_P
 SG_ EVCC_DiagRespData14 : 119|8@0+ (1,0) [0|255] ""  CVC_P
 SG_ EVCC_DiagRespData15 : 127|8@0+ (1,0) [0|255] ""  CVC_P
 SG_ EVCC_DiagRespData16 : 135|8@0+ (1,0) [0|255] ""  CVC_P
 SG_ EVCC_DiagRespData17 : 143|8@0+ (1,0) [0|255] ""  CVC_P
 SG_ EVCC_DiagRespData18 : 151|8@0+ (1,0) [0|255] ""  CVC_P
 SG_ EVCC_DiagRespData19 : 159|8@0+ (1,0) [0|255] ""  CVC_P
 SG_ EVCC_DiagRespData20 : 167|8@0+ (1,0) [0|255] ""  CVC_P
 SG_ EVCC_DiagRespData21 : 175|8@0+ (1,0) [0|255] ""  CVC_P
 SG_ EVCC_DiagRespData22 : 183|8@0+ (1,0) [0|255] ""  CVC_P
 SG_ EVCC_DiagRespData23 : 191|8@0+ (1,0) [0|255] ""  CVC_P
 SG_ EVCC_DiagRespData24 : 199|8@0+ (1,0) [0|255] ""  CVC_P
 SG_ EVCC_DiagRespData25 : 207|8@0+ (1,0) [0|255] ""  CVC_P
 SG_ EVCC_DiagRespData26 : 215|8@0+ (1,0) [0|255] ""  CVC_P
 SG_ EVCC_DiagRespData27 : 223|8@0+ (1,0) [0|255] ""  CVC_P
 SG_ EVCC_DiagRespData28 : 231|8@0+ (1,0) [0|255] ""  CVC_P
 SG_ EVCC_DiagRespData29 : 239|8@0+ (1,0) [0|255] ""  CVC_P
 SG_ EVCC_DiagRespData30 : 247|8@0+ (1,0) [0|255] ""  CVC_P
 SG_ EVCC_DiagRespData31 : 255|8@0+ (1,0) [0|255] ""  CVC_P
 SG_ EVCC_DiagRespData32 : 263|8@0+ (1,0) [0|255] ""  CVC_P
 SG_ EVCC_DiagRespData33 : 271|8@0+ (1,0) [0|255] ""  CVC_P
 SG_ EVCC_DiagRespData34 : 279|8@0+ (1,0) [0|255] ""  CVC_P
 SG_ EVCC_DiagRespData35 : 287|8@0+ (1,0) [0|255] ""  CVC_P
 SG_ EVCC_DiagRespData36 : 295|8@0+ (1,0) [0|255] ""  CVC_P
 SG_ EVCC_DiagRespData37 : 303|8@0+ (1,0) [0|255] ""  CVC_P
 SG_ EVCC_DiagRespData38 : 311|8@0+ (1,0) [0|255] ""  CVC_P
 SG_ EVCC_DiagRespData39 : 319|8@0+ (1,0) [0|255] ""  CVC_P
 SG_ EVCC_DiagRespData40 : 327|8@0+ (1,0) [0|255] ""  CVC_P
 SG_ EVCC_DiagRespData41 : 335|8@0+ (1,0) [0|255] ""  CVC_P
 SG_ EVCC_DiagRespData42 : 343|8@0+ (1,0) [0|255] ""  CVC_P
 SG_ EVCC_DiagRespData43 : 351|8@0+ (1,0) [0|255] ""  CVC_P
 SG_ EVCC_DiagRespData44 : 359|8@0+ (1,0) [0|255] ""  CVC_P
 SG_ EVCC_DiagRespData45 : 367|8@0+ (1,0) [0|255] ""  CVC_P
 SG_ EVCC_DiagRespData46 : 375|8@0+ (1,0) [0|255] ""  CVC_P
 SG_ EVCC_DiagRespData47 : 383|8@0+ (1,0) [0|255] ""  CVC_P
 SG_ EVCC_DiagRespData48 : 391|8@0+ (1,0) [0|255] ""  CVC_P
 SG_ EVCC_DiagRespData49 : 399|8@0+ (1,0) [0|255] ""  CVC_P
 SG_ EVCC_DiagRespData50 : 407|8@0+ (1,0) [0|255] ""  CVC_P
 SG_ EVCC_DiagRespData51 : 415|8@0+ (1,0) [0|255] ""  CVC_P
 SG_ EVCC_DiagRespData52 : 423|8@0+ (1,0) [0|255] ""  CVC_P
 SG_ EVCC_DiagRespData53 : 431|8@0+ (1,0) [0|255] ""  CVC_P
 SG_ EVCC_DiagRespData54 : 439|8@0+ (1,0) [0|255] ""  CVC_P
 SG_ EVCC_DiagRespData55 : 447|8@0+ (1,0) [0|255] ""  CVC_P
 SG_ EVCC_DiagRespData56 : 455|8@0+ (1,0) [0|255] ""  CVC_P
 SG_ EVCC_DiagRespData57 : 463|8@0+ (1,0) [0|255] ""  CVC_P
 SG_ EVCC_DiagRespData58 : 471|8@0+ (1,0) [0|255] ""  CVC_P
 SG_ EVCC_DiagRespData59 : 479|8@0+ (1,0) [0|255] ""  CVC_P
 SG_ EVCC_DiagRespData60 : 487|8@0+ (1,0) [0|255] ""  CVC_P
 SG_ EVCC_DiagRespData61 : 495|8@0+ (1,0) [0|255] ""  CVC_P
 SG_ EVCC_DiagRespData62 : 503|8@0+ (1,0) [0|255] ""  CVC_P
 SG_ EVCC_DiagRespData63 : 511|8@0+ (1,0) [0|255] ""  CVC_P

BO_ 1725 POD_DCDC_DiagReq: 64 CVC_P
 SG_ POD_DCDC_DiagReqData0 : 7|8@0+ (1,0) [0|255] ""  POD_GW
 SG_ POD_DCDC_DiagReqData1 : 15|8@0+ (1,0) [0|255] ""  POD_GW
 SG_ POD_DCDC_DiagReqData2 : 23|8@0+ (1,0) [0|255] ""  POD_GW
 SG_ POD_DCDC_DiagReqData3 : 31|8@0+ (1,0) [0|255] ""  POD_GW
 SG_ POD_DCDC_DiagReqData4 : 39|8@0+ (1,0) [0|255] ""  POD_GW
 SG_ POD_DCDC_DiagReqData5 : 47|8@0+ (1,0) [0|255] ""  POD_GW
 SG_ POD_DCDC_DiagReqData6 : 55|8@0+ (1,0) [0|255] ""  POD_GW
 SG_ POD_DCDC_DiagReqData7 : 63|8@0+ (1,0) [0|255] ""  POD_GW
 SG_ POD_DCDC_DiagReqData8 : 71|8@0+ (1,0) [0|255] ""  POD_GW
 SG_ POD_DCDC_DiagReqData9 : 79|8@0+ (1,0) [0|255] ""  POD_GW
 SG_ POD_DCDC_DiagReqData10 : 87|8@0+ (1,0) [0|255] ""  POD_GW
 SG_ POD_DCDC_DiagReqData11 : 95|8@0+ (1,0) [0|255] ""  POD_GW
 SG_ POD_DCDC_DiagReqData12 : 103|8@0+ (1,0) [0|255] ""  POD_GW
 SG_ POD_DCDC_DiagReqData13 : 111|8@0+ (1,0) [0|255] ""  POD_GW
 SG_ POD_DCDC_DiagReqData14 : 119|8@0+ (1,0) [0|255] ""  POD_GW
 SG_ POD_DCDC_DiagReqData15 : 127|8@0+ (1,0) [0|255] ""  POD_GW
 SG_ POD_DCDC_DiagReqData16 : 135|8@0+ (1,0) [0|255] ""  POD_GW
 SG_ POD_DCDC_DiagReqData17 : 143|8@0+ (1,0) [0|255] ""  POD_GW
 SG_ POD_DCDC_DiagReqData18 : 151|8@0+ (1,0) [0|255] ""  POD_GW
 SG_ POD_DCDC_DiagReqData19 : 159|8@0+ (1,0) [0|255] ""  POD_GW
 SG_ POD_DCDC_DiagReqData20 : 167|8@0+ (1,0) [0|255] ""  POD_GW
 SG_ POD_DCDC_DiagReqData21 : 175|8@0+ (1,0) [0|255] ""  POD_GW
 SG_ POD_DCDC_DiagReqData22 : 183|8@0+ (1,0) [0|255] ""  POD_GW
 SG_ POD_DCDC_DiagReqData23 : 191|8@0+ (1,0) [0|255] ""  POD_GW
 SG_ POD_DCDC_DiagReqData24 : 199|8@0+ (1,0) [0|255] ""  POD_GW
 SG_ POD_DCDC_DiagReqData25 : 207|8@0+ (1,0) [0|255] ""  POD_GW
 SG_ POD_DCDC_DiagReqData26 : 215|8@0+ (1,0) [0|255] ""  POD_GW
 SG_ POD_DCDC_DiagReqData27 : 223|8@0+ (1,0) [0|255] ""  POD_GW
 SG_ POD_DCDC_DiagReqData28 : 231|8@0+ (1,0) [0|255] ""  POD_GW
 SG_ POD_DCDC_DiagReqData29 : 239|8@0+ (1,0) [0|255] ""  POD_GW
 SG_ POD_DCDC_DiagReqData30 : 247|8@0+ (1,0) [0|255] ""  POD_GW
 SG_ POD_DCDC_DiagReqData31 : 255|8@0+ (1,0) [0|255] ""  POD_GW
 SG_ POD_DCDC_DiagReqData32 : 263|8@0+ (1,0) [0|255] ""  POD_GW
 SG_ POD_DCDC_DiagReqData33 : 271|8@0+ (1,0) [0|255] ""  POD_GW
 SG_ POD_DCDC_DiagReqData34 : 279|8@0+ (1,0) [0|255] ""  POD_GW
 SG_ POD_DCDC_DiagReqData35 : 287|8@0+ (1,0) [0|255] ""  POD_GW
 SG_ POD_DCDC_DiagReqData36 : 295|8@0+ (1,0) [0|255] ""  POD_GW
 SG_ POD_DCDC_DiagReqData37 : 303|8@0+ (1,0) [0|255] ""  POD_GW
 SG_ POD_DCDC_DiagReqData38 : 311|8@0+ (1,0) [0|255] ""  POD_GW
 SG_ POD_DCDC_DiagReqData39 : 319|8@0+ (1,0) [0|255] ""  POD_GW
 SG_ POD_DCDC_DiagReqData40 : 327|8@0+ (1,0) [0|255] ""  POD_GW
 SG_ POD_DCDC_DiagReqData41 : 335|8@0+ (1,0) [0|255] ""  POD_GW
 SG_ POD_DCDC_DiagReqData42 : 343|8@0+ (1,0) [0|255] ""  POD_GW
 SG_ POD_DCDC_DiagReqData43 : 351|8@0+ (1,0) [0|255] ""  POD_GW
 SG_ POD_DCDC_DiagReqData44 : 359|8@0+ (1,0) [0|255] ""  POD_GW
 SG_ POD_DCDC_DiagReqData45 : 367|8@0+ (1,0) [0|255] ""  POD_GW
 SG_ POD_DCDC_DiagReqData46 : 375|8@0+ (1,0) [0|255] ""  POD_GW
 SG_ POD_DCDC_DiagReqData47 : 383|8@0+ (1,0) [0|255] ""  POD_GW
 SG_ POD_DCDC_DiagReqData48 : 391|8@0+ (1,0) [0|255] ""  POD_GW
 SG_ POD_DCDC_DiagReqData49 : 399|8@0+ (1,0) [0|255] ""  POD_GW
 SG_ POD_DCDC_DiagReqData50 : 407|8@0+ (1,0) [0|255] ""  POD_GW
 SG_ POD_DCDC_DiagReqData51 : 415|8@0+ (1,0) [0|255] ""  POD_GW
 SG_ POD_DCDC_DiagReqData52 : 423|8@0+ (1,0) [0|255] ""  POD_GW
 SG_ POD_DCDC_DiagReqData53 : 431|8@0+ (1,0) [0|255] ""  POD_GW
 SG_ POD_DCDC_DiagReqData54 : 439|8@0+ (1,0) [0|255] ""  POD_GW
 SG_ POD_DCDC_DiagReqData55 : 447|8@0+ (1,0) [0|255] ""  POD_GW
 SG_ POD_DCDC_DiagReqData56 : 455|8@0+ (1,0) [0|255] ""  POD_GW
 SG_ POD_DCDC_DiagReqData57 : 463|8@0+ (1,0) [0|255] ""  POD_GW
 SG_ POD_DCDC_DiagReqData58 : 471|8@0+ (1,0) [0|255] ""  POD_GW
 SG_ POD_DCDC_DiagReqData59 : 479|8@0+ (1,0) [0|255] ""  POD_GW
 SG_ POD_DCDC_DiagReqData60 : 487|8@0+ (1,0) [0|255] ""  POD_GW
 SG_ POD_DCDC_DiagReqData61 : 495|8@0+ (1,0) [0|255] ""  POD_GW
 SG_ POD_DCDC_DiagReqData62 : 503|8@0+ (1,0) [0|255] ""  POD_GW
 SG_ POD_DCDC_DiagReqData63 : 511|8@0+ (1,0) [0|255] ""  POD_GW

BO_ 1597 POD_DCDC_DiagResp: 64 POD_GW
 SG_ POD_DCDC_DiagRespData0 : 7|8@0+ (1,0) [0|255] ""  CVC_P
 SG_ POD_DCDC_DiagRespData1 : 15|8@0+ (1,0) [0|255] ""  CVC_P
 SG_ POD_DCDC_DiagRespData2 : 23|8@0+ (1,0) [0|255] ""  CVC_P
 SG_ POD_DCDC_DiagRespData3 : 31|8@0+ (1,0) [0|255] ""  CVC_P
 SG_ POD_DCDC_DiagRespData4 : 39|8@0+ (1,0) [0|255] ""  CVC_P
 SG_ POD_DCDC_DiagRespData5 : 47|8@0+ (1,0) [0|255] ""  CVC_P
 SG_ POD_DCDC_DiagRespData6 : 55|8@0+ (1,0) [0|255] ""  CVC_P
 SG_ POD_DCDC_DiagRespData7 : 63|8@0+ (1,0) [0|255] ""  CVC_P
 SG_ POD_DCDC_DiagRespData8 : 71|8@0+ (1,0) [0|255] ""  CVC_P
 SG_ POD_DCDC_DiagRespData9 : 79|8@0+ (1,0) [0|255] ""  CVC_P
 SG_ POD_DCDC_DiagRespData10 : 87|8@0+ (1,0) [0|255] ""  CVC_P
 SG_ POD_DCDC_DiagRespData11 : 95|8@0+ (1,0) [0|255] ""  CVC_P
 SG_ POD_DCDC_DiagRespData12 : 103|8@0+ (1,0) [0|255] ""  CVC_P
 SG_ POD_DCDC_DiagRespData13 : 111|8@0+ (1,0) [0|255] ""  CVC_P
 SG_ POD_DCDC_DiagRespData14 : 119|8@0+ (1,0) [0|255] ""  CVC_P
 SG_ POD_DCDC_DiagRespData15 : 127|8@0+ (1,0) [0|255] ""  CVC_P
 SG_ POD_DCDC_DiagRespData16 : 135|8@0+ (1,0) [0|255] ""  CVC_P
 SG_ POD_DCDC_DiagRespData17 : 143|8@0+ (1,0) [0|255] ""  CVC_P
 SG_ POD_DCDC_DiagRespData18 : 151|8@0+ (1,0) [0|255] ""  CVC_P
 SG_ POD_DCDC_DiagRespData19 : 159|8@0+ (1,0) [0|255] ""  CVC_P
 SG_ POD_DCDC_DiagRespData20 : 167|8@0+ (1,0) [0|255] ""  CVC_P
 SG_ POD_DCDC_DiagRespData21 : 175|8@0+ (1,0) [0|255] ""  CVC_P
 SG_ POD_DCDC_DiagRespData22 : 183|8@0+ (1,0) [0|255] ""  CVC_P
 SG_ POD_DCDC_DiagRespData23 : 191|8@0+ (1,0) [0|255] ""  CVC_P
 SG_ POD_DCDC_DiagRespData24 : 199|8@0+ (1,0) [0|255] ""  CVC_P
 SG_ POD_DCDC_DiagRespData25 : 207|8@0+ (1,0) [0|255] ""  CVC_P
 SG_ POD_DCDC_DiagRespData26 : 215|8@0+ (1,0) [0|255] ""  CVC_P
 SG_ POD_DCDC_DiagRespData27 : 223|8@0+ (1,0) [0|255] ""  CVC_P
 SG_ POD_DCDC_DiagRespData28 : 231|8@0+ (1,0) [0|255] ""  CVC_P
 SG_ POD_DCDC_DiagRespData29 : 239|8@0+ (1,0) [0|255] ""  CVC_P
 SG_ POD_DCDC_DiagRespData30 : 247|8@0+ (1,0) [0|255] ""  CVC_P
 SG_ POD_DCDC_DiagRespData31 : 255|8@0+ (1,0) [0|255] ""  CVC_P
 SG_ POD_DCDC_DiagRespData32 : 263|8@0+ (1,0) [0|255] ""  CVC_P
 SG_ POD_DCDC_DiagRespData33 : 271|8@0+ (1,0) [0|255] ""  CVC_P
 SG_ POD_DCDC_DiagRespData34 : 279|8@0+ (1,0) [0|255] ""  CVC_P
 SG_ POD_DCDC_DiagRespData35 : 287|8@0+ (1,0) [0|255] ""  CVC_P
 SG_ POD_DCDC_DiagRespData36 : 295|8@0+ (1,0) [0|255] ""  CVC_P
 SG_ POD_DCDC_DiagRespData37 : 303|8@0+ (1,0) [0|255] ""  CVC_P
 SG_ POD_DCDC_DiagRespData38 : 311|8@0+ (1,0) [0|255] ""  CVC_P
 SG_ POD_DCDC_DiagRespData39 : 319|8@0+ (1,0) [0|255] ""  CVC_P
 SG_ POD_DCDC_DiagRespData40 : 327|8@0+ (1,0) [0|255] ""  CVC_P
 SG_ POD_DCDC_DiagRespData41 : 335|8@0+ (1,0) [0|255] ""  CVC_P
 SG_ POD_DCDC_DiagRespData42 : 343|8@0+ (1,0) [0|255] ""  CVC_P
 SG_ POD_DCDC_DiagRespData43 : 351|8@0+ (1,0) [0|255] ""  CVC_P
 SG_ POD_DCDC_DiagRespData44 : 359|8@0+ (1,0) [0|255] ""  CVC_P
 SG_ POD_DCDC_DiagRespData45 : 367|8@0+ (1,0) [0|255] ""  CVC_P
 SG_ POD_DCDC_DiagRespData46 : 375|8@0+ (1,0) [0|255] ""  CVC_P
 SG_ POD_DCDC_DiagRespData47 : 383|8@0+ (1,0) [0|255] ""  CVC_P
 SG_ POD_DCDC_DiagRespData48 : 391|8@0+ (1,0) [0|255] ""  CVC_P
 SG_ POD_DCDC_DiagRespData49 : 399|8@0+ (1,0) [0|255] ""  CVC_P
 SG_ POD_DCDC_DiagRespData50 : 407|8@0+ (1,0) [0|255] ""  CVC_P
 SG_ POD_DCDC_DiagRespData51 : 415|8@0+ (1,0) [0|255] ""  CVC_P
 SG_ POD_DCDC_DiagRespData52 : 423|8@0+ (1,0) [0|255] ""  CVC_P
 SG_ POD_DCDC_DiagRespData53 : 431|8@0+ (1,0) [0|255] ""  CVC_P
 SG_ POD_DCDC_DiagRespData54 : 439|8@0+ (1,0) [0|255] ""  CVC_P
 SG_ POD_DCDC_DiagRespData55 : 447|8@0+ (1,0) [0|255] ""  CVC_P
 SG_ POD_DCDC_DiagRespData56 : 455|8@0+ (1,0) [0|255] ""  CVC_P
 SG_ POD_DCDC_DiagRespData57 : 463|8@0+ (1,0) [0|255] ""  CVC_P
 SG_ POD_DCDC_DiagRespData58 : 471|8@0+ (1,0) [0|255] ""  CVC_P
 SG_ POD_DCDC_DiagRespData59 : 479|8@0+ (1,0) [0|255] ""  CVC_P
 SG_ POD_DCDC_DiagRespData60 : 487|8@0+ (1,0) [0|255] ""  CVC_P
 SG_ POD_DCDC_DiagRespData61 : 495|8@0+ (1,0) [0|255] ""  CVC_P
 SG_ POD_DCDC_DiagRespData62 : 503|8@0+ (1,0) [0|255] ""  CVC_P
 SG_ POD_DCDC_DiagRespData63 : 511|8@0+ (1,0) [0|255] ""  CVC_P

BO_ 1726 POD_OBC_DiagReq: 64 CVC_P
 SG_ POD_OBC_DiagReqData0 : 7|8@0+ (1,0) [0|255] ""  POD_GW
 SG_ POD_OBC_DiagReqData1 : 15|8@0+ (1,0) [0|255] ""  POD_GW
 SG_ POD_OBC_DiagReqData2 : 23|8@0+ (1,0) [0|255] ""  POD_GW
 SG_ POD_OBC_DiagReqData3 : 31|8@0+ (1,0) [0|255] ""  POD_GW
 SG_ POD_OBC_DiagReqData4 : 39|8@0+ (1,0) [0|255] ""  POD_GW
 SG_ POD_OBC_DiagReqData5 : 47|8@0+ (1,0) [0|255] ""  POD_GW
 SG_ POD_OBC_DiagReqData6 : 55|8@0+ (1,0) [0|255] ""  POD_GW
 SG_ POD_OBC_DiagReqData7 : 63|8@0+ (1,0) [0|255] ""  POD_GW
 SG_ POD_OBC_DiagReqData8 : 71|8@0+ (1,0) [0|255] ""  POD_GW
 SG_ POD_OBC_DiagReqData9 : 79|8@0+ (1,0) [0|255] ""  POD_GW
 SG_ POD_OBC_DiagReqData10 : 87|8@0+ (1,0) [0|255] ""  POD_GW
 SG_ POD_OBC_DiagReqData11 : 95|8@0+ (1,0) [0|255] ""  POD_GW
 SG_ POD_OBC_DiagReqData12 : 103|8@0+ (1,0) [0|255] ""  POD_GW
 SG_ POD_OBC_DiagReqData13 : 111|8@0+ (1,0) [0|255] ""  POD_GW
 SG_ POD_OBC_DiagReqData14 : 119|8@0+ (1,0) [0|255] ""  POD_GW
 SG_ POD_OBC_DiagReqData15 : 127|8@0+ (1,0) [0|255] ""  POD_GW
 SG_ POD_OBC_DiagReqData16 : 135|8@0+ (1,0) [0|255] ""  POD_GW
 SG_ POD_OBC_DiagReqData17 : 143|8@0+ (1,0) [0|255] ""  POD_GW
 SG_ POD_OBC_DiagReqData18 : 151|8@0+ (1,0) [0|255] ""  POD_GW
 SG_ POD_OBC_DiagReqData19 : 159|8@0+ (1,0) [0|255] ""  POD_GW
 SG_ POD_OBC_DiagReqData20 : 167|8@0+ (1,0) [0|255] ""  POD_GW
 SG_ POD_OBC_DiagReqData21 : 175|8@0+ (1,0) [0|255] ""  POD_GW
 SG_ POD_OBC_DiagReqData22 : 183|8@0+ (1,0) [0|255] ""  POD_GW
 SG_ POD_OBC_DiagReqData23 : 191|8@0+ (1,0) [0|255] ""  POD_GW
 SG_ POD_OBC_DiagReqData24 : 199|8@0+ (1,0) [0|255] ""  POD_GW
 SG_ POD_OBC_DiagReqData25 : 207|8@0+ (1,0) [0|255] ""  POD_GW
 SG_ POD_OBC_DiagReqData26 : 215|8@0+ (1,0) [0|255] ""  POD_GW
 SG_ POD_OBC_DiagReqData27 : 223|8@0+ (1,0) [0|255] ""  POD_GW
 SG_ POD_OBC_DiagReqData28 : 231|8@0+ (1,0) [0|255] ""  POD_GW
 SG_ POD_OBC_DiagReqData29 : 239|8@0+ (1,0) [0|255] ""  POD_GW
 SG_ POD_OBC_DiagReqData30 : 247|8@0+ (1,0) [0|255] ""  POD_GW
 SG_ POD_OBC_DiagReqData31 : 255|8@0+ (1,0) [0|255] ""  POD_GW
 SG_ POD_OBC_DiagReqData32 : 263|8@0+ (1,0) [0|255] ""  POD_GW
 SG_ POD_OBC_DiagReqData33 : 271|8@0+ (1,0) [0|255] ""  POD_GW
 SG_ POD_OBC_DiagReqData34 : 279|8@0+ (1,0) [0|255] ""  POD_GW
 SG_ POD_OBC_DiagReqData35 : 287|8@0+ (1,0) [0|255] ""  POD_GW
 SG_ POD_OBC_DiagReqData36 : 295|8@0+ (1,0) [0|255] ""  POD_GW
 SG_ POD_OBC_DiagReqData37 : 303|8@0+ (1,0) [0|255] ""  POD_GW
 SG_ POD_OBC_DiagReqData38 : 311|8@0+ (1,0) [0|255] ""  POD_GW
 SG_ POD_OBC_DiagReqData39 : 319|8@0+ (1,0) [0|255] ""  POD_GW
 SG_ POD_OBC_DiagReqData40 : 327|8@0+ (1,0) [0|255] ""  POD_GW
 SG_ POD_OBC_DiagReqData41 : 335|8@0+ (1,0) [0|255] ""  POD_GW
 SG_ POD_OBC_DiagReqData42 : 343|8@0+ (1,0) [0|255] ""  POD_GW
 SG_ POD_OBC_DiagReqData43 : 351|8@0+ (1,0) [0|255] ""  POD_GW
 SG_ POD_OBC_DiagReqData44 : 359|8@0+ (1,0) [0|255] ""  POD_GW
 SG_ POD_OBC_DiagReqData45 : 367|8@0+ (1,0) [0|255] ""  POD_GW
 SG_ POD_OBC_DiagReqData46 : 375|8@0+ (1,0) [0|255] ""  POD_GW
 SG_ POD_OBC_DiagReqData47 : 383|8@0+ (1,0) [0|255] ""  POD_GW
 SG_ POD_OBC_DiagReqData48 : 391|8@0+ (1,0) [0|255] ""  POD_GW
 SG_ POD_OBC_DiagReqData49 : 399|8@0+ (1,0) [0|255] ""  POD_GW
 SG_ POD_OBC_DiagReqData50 : 407|8@0+ (1,0) [0|255] ""  POD_GW
 SG_ POD_OBC_DiagReqData51 : 415|8@0+ (1,0) [0|255] ""  POD_GW
 SG_ POD_OBC_DiagReqData52 : 423|8@0+ (1,0) [0|255] ""  POD_GW
 SG_ POD_OBC_DiagReqData53 : 431|8@0+ (1,0) [0|255] ""  POD_GW
 SG_ POD_OBC_DiagReqData54 : 439|8@0+ (1,0) [0|255] ""  POD_GW
 SG_ POD_OBC_DiagReqData55 : 447|8@0+ (1,0) [0|255] ""  POD_GW
 SG_ POD_OBC_DiagReqData56 : 455|8@0+ (1,0) [0|255] ""  POD_GW
 SG_ POD_OBC_DiagReqData57 : 463|8@0+ (1,0) [0|255] ""  POD_GW
 SG_ POD_OBC_DiagReqData58 : 471|8@0+ (1,0) [0|255] ""  POD_GW
 SG_ POD_OBC_DiagReqData59 : 479|8@0+ (1,0) [0|255] ""  POD_GW
 SG_ POD_OBC_DiagReqData60 : 487|8@0+ (1,0) [0|255] ""  POD_GW
 SG_ POD_OBC_DiagReqData61 : 495|8@0+ (1,0) [0|255] ""  POD_GW
 SG_ POD_OBC_DiagReqData62 : 503|8@0+ (1,0) [0|255] ""  POD_GW
 SG_ POD_OBC_DiagReqData63 : 511|8@0+ (1,0) [0|255] ""  POD_GW

BO_ 1598 POD_OBC_DiagResp: 64 POD_GW
 SG_ POD_OBC_DiagRespData0 : 7|8@0+ (1,0) [0|255] ""  CVC_P
 SG_ POD_OBC_DiagRespData1 : 15|8@0+ (1,0) [0|255] ""  CVC_P
 SG_ POD_OBC_DiagRespData2 : 23|8@0+ (1,0) [0|255] ""  CVC_P
 SG_ POD_OBC_DiagRespData3 : 31|8@0+ (1,0) [0|255] ""  CVC_P
 SG_ POD_OBC_DiagRespData4 : 39|8@0+ (1,0) [0|255] ""  CVC_P
 SG_ POD_OBC_DiagRespData5 : 47|8@0+ (1,0) [0|255] ""  CVC_P
 SG_ POD_OBC_DiagRespData6 : 55|8@0+ (1,0) [0|255] ""  CVC_P
 SG_ POD_OBC_DiagRespData7 : 63|8@0+ (1,0) [0|255] ""  CVC_P
 SG_ POD_OBC_DiagRespData8 : 71|8@0+ (1,0) [0|255] ""  CVC_P
 SG_ POD_OBC_DiagRespData9 : 79|8@0+ (1,0) [0|255] ""  CVC_P
 SG_ POD_OBC_DiagRespData10 : 87|8@0+ (1,0) [0|255] ""  CVC_P
 SG_ POD_OBC_DiagRespData11 : 95|8@0+ (1,0) [0|255] ""  CVC_P
 SG_ POD_OBC_DiagRespData12 : 103|8@0+ (1,0) [0|255] ""  CVC_P
 SG_ POD_OBC_DiagRespData13 : 111|8@0+ (1,0) [0|255] ""  CVC_P
 SG_ POD_OBC_DiagRespData14 : 119|8@0+ (1,0) [0|255] ""  CVC_P
 SG_ POD_OBC_DiagRespData15 : 127|8@0+ (1,0) [0|255] ""  CVC_P
 SG_ POD_OBC_DiagRespData16 : 135|8@0+ (1,0) [0|255] ""  CVC_P
 SG_ POD_OBC_DiagRespData17 : 143|8@0+ (1,0) [0|255] ""  CVC_P
 SG_ POD_OBC_DiagRespData18 : 151|8@0+ (1,0) [0|255] ""  CVC_P
 SG_ POD_OBC_DiagRespData19 : 159|8@0+ (1,0) [0|255] ""  CVC_P
 SG_ POD_OBC_DiagRespData20 : 167|8@0+ (1,0) [0|255] ""  CVC_P
 SG_ POD_OBC_DiagRespData21 : 175|8@0+ (1,0) [0|255] ""  CVC_P
 SG_ POD_OBC_DiagRespData22 : 183|8@0+ (1,0) [0|255] ""  CVC_P
 SG_ POD_OBC_DiagRespData23 : 191|8@0+ (1,0) [0|255] ""  CVC_P
 SG_ POD_OBC_DiagRespData24 : 199|8@0+ (1,0) [0|255] ""  CVC_P
 SG_ POD_OBC_DiagRespData25 : 207|8@0+ (1,0) [0|255] ""  CVC_P
 SG_ POD_OBC_DiagRespData26 : 215|8@0+ (1,0) [0|255] ""  CVC_P
 SG_ POD_OBC_DiagRespData27 : 223|8@0+ (1,0) [0|255] ""  CVC_P
 SG_ POD_OBC_DiagRespData28 : 231|8@0+ (1,0) [0|255] ""  CVC_P
 SG_ POD_OBC_DiagRespData29 : 239|8@0+ (1,0) [0|255] ""  CVC_P
 SG_ POD_OBC_DiagRespData30 : 247|8@0+ (1,0) [0|255] ""  CVC_P
 SG_ POD_OBC_DiagRespData31 : 255|8@0+ (1,0) [0|255] ""  CVC_P
 SG_ POD_OBC_DiagRespData32 : 263|8@0+ (1,0) [0|255] ""  CVC_P
 SG_ POD_OBC_DiagRespData33 : 271|8@0+ (1,0) [0|255] ""  CVC_P
 SG_ POD_OBC_DiagRespData34 : 279|8@0+ (1,0) [0|255] ""  CVC_P
 SG_ POD_OBC_DiagRespData35 : 287|8@0+ (1,0) [0|255] ""  CVC_P
 SG_ POD_OBC_DiagRespData36 : 295|8@0+ (1,0) [0|255] ""  CVC_P
 SG_ POD_OBC_DiagRespData37 : 303|8@0+ (1,0) [0|255] ""  CVC_P
 SG_ POD_OBC_DiagRespData38 : 311|8@0+ (1,0) [0|255] ""  CVC_P
 SG_ POD_OBC_DiagRespData39 : 319|8@0+ (1,0) [0|255] ""  CVC_P
 SG_ POD_OBC_DiagRespData40 : 327|8@0+ (1,0) [0|255] ""  CVC_P
 SG_ POD_OBC_DiagRespData41 : 335|8@0+ (1,0) [0|255] ""  CVC_P
 SG_ POD_OBC_DiagRespData42 : 343|8@0+ (1,0) [0|255] ""  CVC_P
 SG_ POD_OBC_DiagRespData43 : 351|8@0+ (1,0) [0|255] ""  CVC_P
 SG_ POD_OBC_DiagRespData44 : 359|8@0+ (1,0) [0|255] ""  CVC_P
 SG_ POD_OBC_DiagRespData45 : 367|8@0+ (1,0) [0|255] ""  CVC_P
 SG_ POD_OBC_DiagRespData46 : 375|8@0+ (1,0) [0|255] ""  CVC_P
 SG_ POD_OBC_DiagRespData47 : 383|8@0+ (1,0) [0|255] ""  CVC_P
 SG_ POD_OBC_DiagRespData48 : 391|8@0+ (1,0) [0|255] ""  CVC_P
 SG_ POD_OBC_DiagRespData49 : 399|8@0+ (1,0) [0|255] ""  CVC_P
 SG_ POD_OBC_DiagRespData50 : 407|8@0+ (1,0) [0|255] ""  CVC_P
 SG_ POD_OBC_DiagRespData51 : 415|8@0+ (1,0) [0|255] ""  CVC_P
 SG_ POD_OBC_DiagRespData52 : 423|8@0+ (1,0) [0|255] ""  CVC_P
 SG_ POD_OBC_DiagRespData53 : 431|8@0+ (1,0) [0|255] ""  CVC_P
 SG_ POD_OBC_DiagRespData54 : 439|8@0+ (1,0) [0|255] ""  CVC_P
 SG_ POD_OBC_DiagRespData55 : 447|8@0+ (1,0) [0|255] ""  CVC_P
 SG_ POD_OBC_DiagRespData56 : 455|8@0+ (1,0) [0|255] ""  CVC_P
 SG_ POD_OBC_DiagRespData57 : 463|8@0+ (1,0) [0|255] ""  CVC_P
 SG_ POD_OBC_DiagRespData58 : 471|8@0+ (1,0) [0|255] ""  CVC_P
 SG_ POD_OBC_DiagRespData59 : 479|8@0+ (1,0) [0|255] ""  CVC_P
 SG_ POD_OBC_DiagRespData60 : 487|8@0+ (1,0) [0|255] ""  CVC_P
 SG_ POD_OBC_DiagRespData61 : 495|8@0+ (1,0) [0|255] ""  CVC_P
 SG_ POD_OBC_DiagRespData62 : 503|8@0+ (1,0) [0|255] ""  CVC_P
 SG_ POD_OBC_DiagRespData63 : 511|8@0+ (1,0) [0|255] ""  CVC_P

BO_ 1720 PCU_DiagReq: 64 CVC_P
 SG_ PCU_DiagReqData0 : 7|8@0+ (1,0) [0|255] ""  PCU
 SG_ PCU_DiagReqData1 : 15|8@0+ (1,0) [0|255] ""  PCU
 SG_ PCU_DiagReqData2 : 23|8@0+ (1,0) [0|255] ""  PCU
 SG_ PCU_DiagReqData3 : 31|8@0+ (1,0) [0|255] ""  PCU
 SG_ PCU_DiagReqData4 : 39|8@0+ (1,0) [0|255] ""  PCU
 SG_ PCU_DiagReqData5 : 47|8@0+ (1,0) [0|255] ""  PCU
 SG_ PCU_DiagReqData6 : 55|8@0+ (1,0) [0|255] ""  PCU
 SG_ PCU_DiagReqData7 : 63|8@0+ (1,0) [0|255] ""  PCU
 SG_ PCU_DiagReqData8 : 71|8@0+ (1,0) [0|255] ""  PCU
 SG_ PCU_DiagReqData9 : 79|8@0+ (1,0) [0|255] ""  PCU
 SG_ PCU_DiagReqData10 : 87|8@0+ (1,0) [0|255] ""  PCU
 SG_ PCU_DiagReqData11 : 95|8@0+ (1,0) [0|255] ""  PCU
 SG_ PCU_DiagReqData12 : 103|8@0+ (1,0) [0|255] ""  PCU
 SG_ PCU_DiagReqData13 : 111|8@0+ (1,0) [0|255] ""  PCU
 SG_ PCU_DiagReqData14 : 119|8@0+ (1,0) [0|255] ""  PCU
 SG_ PCU_DiagReqData15 : 127|8@0+ (1,0) [0|255] ""  PCU
 SG_ PCU_DiagReqData16 : 135|8@0+ (1,0) [0|255] ""  PCU
 SG_ PCU_DiagReqData17 : 143|8@0+ (1,0) [0|255] ""  PCU
 SG_ PCU_DiagReqData18 : 151|8@0+ (1,0) [0|255] ""  PCU
 SG_ PCU_DiagReqData19 : 159|8@0+ (1,0) [0|255] ""  PCU
 SG_ PCU_DiagReqData20 : 167|8@0+ (1,0) [0|255] ""  PCU
 SG_ PCU_DiagReqData21 : 175|8@0+ (1,0) [0|255] ""  PCU
 SG_ PCU_DiagReqData22 : 183|8@0+ (1,0) [0|255] ""  PCU
 SG_ PCU_DiagReqData23 : 191|8@0+ (1,0) [0|255] ""  PCU
 SG_ PCU_DiagReqData24 : 199|8@0+ (1,0) [0|255] ""  PCU
 SG_ PCU_DiagReqData25 : 207|8@0+ (1,0) [0|255] ""  PCU
 SG_ PCU_DiagReqData26 : 215|8@0+ (1,0) [0|255] ""  PCU
 SG_ PCU_DiagReqData27 : 223|8@0+ (1,0) [0|255] ""  PCU
 SG_ PCU_DiagReqData28 : 231|8@0+ (1,0) [0|255] ""  PCU
 SG_ PCU_DiagReqData29 : 239|8@0+ (1,0) [0|255] ""  PCU
 SG_ PCU_DiagReqData30 : 247|8@0+ (1,0) [0|255] ""  PCU
 SG_ PCU_DiagReqData31 : 255|8@0+ (1,0) [0|255] ""  PCU
 SG_ PCU_DiagReqData32 : 263|8@0+ (1,0) [0|255] ""  PCU
 SG_ PCU_DiagReqData33 : 271|8@0+ (1,0) [0|255] ""  PCU
 SG_ PCU_DiagReqData34 : 279|8@0+ (1,0) [0|255] ""  PCU
 SG_ PCU_DiagReqData35 : 287|8@0+ (1,0) [0|255] ""  PCU
 SG_ PCU_DiagReqData36 : 295|8@0+ (1,0) [0|255] ""  PCU
 SG_ PCU_DiagReqData37 : 303|8@0+ (1,0) [0|255] ""  PCU
 SG_ PCU_DiagReqData38 : 311|8@0+ (1,0) [0|255] ""  PCU
 SG_ PCU_DiagReqData39 : 319|8@0+ (1,0) [0|255] ""  PCU
 SG_ PCU_DiagReqData40 : 327|8@0+ (1,0) [0|255] ""  PCU
 SG_ PCU_DiagReqData41 : 335|8@0+ (1,0) [0|255] ""  PCU
 SG_ PCU_DiagReqData42 : 343|8@0+ (1,0) [0|255] ""  PCU
 SG_ PCU_DiagReqData43 : 351|8@0+ (1,0) [0|255] ""  PCU
 SG_ PCU_DiagReqData44 : 359|8@0+ (1,0) [0|255] ""  PCU
 SG_ PCU_DiagReqData45 : 367|8@0+ (1,0) [0|255] ""  PCU
 SG_ PCU_DiagReqData46 : 375|8@0+ (1,0) [0|255] ""  PCU
 SG_ PCU_DiagReqData47 : 383|8@0+ (1,0) [0|255] ""  PCU
 SG_ PCU_DiagReqData48 : 391|8@0+ (1,0) [0|255] ""  PCU
 SG_ PCU_DiagReqData49 : 399|8@0+ (1,0) [0|255] ""  PCU
 SG_ PCU_DiagReqData50 : 407|8@0+ (1,0) [0|255] ""  PCU
 SG_ PCU_DiagReqData51 : 415|8@0+ (1,0) [0|255] ""  PCU
 SG_ PCU_DiagReqData52 : 423|8@0+ (1,0) [0|255] ""  PCU
 SG_ PCU_DiagReqData53 : 431|8@0+ (1,0) [0|255] ""  PCU
 SG_ PCU_DiagReqData54 : 439|8@0+ (1,0) [0|255] ""  PCU
 SG_ PCU_DiagReqData55 : 447|8@0+ (1,0) [0|255] ""  PCU
 SG_ PCU_DiagReqData56 : 455|8@0+ (1,0) [0|255] ""  PCU
 SG_ PCU_DiagReqData57 : 463|8@0+ (1,0) [0|255] ""  PCU
 SG_ PCU_DiagReqData58 : 471|8@0+ (1,0) [0|255] ""  PCU
 SG_ PCU_DiagReqData59 : 479|8@0+ (1,0) [0|255] ""  PCU
 SG_ PCU_DiagReqData60 : 487|8@0+ (1,0) [0|255] ""  PCU
 SG_ PCU_DiagReqData61 : 495|8@0+ (1,0) [0|255] ""  PCU
 SG_ PCU_DiagReqData62 : 503|8@0+ (1,0) [0|255] ""  PCU
 SG_ PCU_DiagReqData63 : 511|8@0+ (1,0) [0|255] ""  PCU

BO_ 1592 PCU_DiagResp: 64 PCU
 SG_ PCU_DiagRespData0 : 7|8@0+ (1,0) [0|255] ""  CVC_P
 SG_ PCU_DiagRespData1 : 15|8@0+ (1,0) [0|255] ""  CVC_P
 SG_ PCU_DiagRespData2 : 23|8@0+ (1,0) [0|255] ""  CVC_P
 SG_ PCU_DiagRespData3 : 31|8@0+ (1,0) [0|255] ""  CVC_P
 SG_ PCU_DiagRespData4 : 39|8@0+ (1,0) [0|255] ""  CVC_P
 SG_ PCU_DiagRespData5 : 47|8@0+ (1,0) [0|255] ""  CVC_P
 SG_ PCU_DiagRespData6 : 55|8@0+ (1,0) [0|255] ""  CVC_P
 SG_ PCU_DiagRespData7 : 63|8@0+ (1,0) [0|255] ""  CVC_P
 SG_ PCU_DiagRespData8 : 71|8@0+ (1,0) [0|255] ""  CVC_P
 SG_ PCU_DiagRespData9 : 79|8@0+ (1,0) [0|255] ""  CVC_P
 SG_ PCU_DiagRespData10 : 87|8@0+ (1,0) [0|255] ""  CVC_P
 SG_ PCU_DiagRespData11 : 95|8@0+ (1,0) [0|255] ""  CVC_P
 SG_ PCU_DiagRespData12 : 103|8@0+ (1,0) [0|255] ""  CVC_P
 SG_ PCU_DiagRespData13 : 111|8@0+ (1,0) [0|255] ""  CVC_P
 SG_ PCU_DiagRespData14 : 119|8@0+ (1,0) [0|255] ""  CVC_P
 SG_ PCU_DiagRespData15 : 127|8@0+ (1,0) [0|255] ""  CVC_P
 SG_ PCU_DiagRespData16 : 135|8@0+ (1,0) [0|255] ""  CVC_P
 SG_ PCU_DiagRespData17 : 143|8@0+ (1,0) [0|255] ""  CVC_P
 SG_ PCU_DiagRespData18 : 151|8@0+ (1,0) [0|255] ""  CVC_P
 SG_ PCU_DiagRespData19 : 159|8@0+ (1,0) [0|255] ""  CVC_P
 SG_ PCU_DiagRespData20 : 167|8@0+ (1,0) [0|255] ""  CVC_P
 SG_ PCU_DiagRespData21 : 175|8@0+ (1,0) [0|255] ""  CVC_P
 SG_ PCU_DiagRespData22 : 183|8@0+ (1,0) [0|255] ""  CVC_P
 SG_ PCU_DiagRespData23 : 191|8@0+ (1,0) [0|255] ""  CVC_P
 SG_ PCU_DiagRespData24 : 199|8@0+ (1,0) [0|255] ""  CVC_P
 SG_ PCU_DiagRespData25 : 207|8@0+ (1,0) [0|255] ""  CVC_P
 SG_ PCU_DiagRespData26 : 215|8@0+ (1,0) [0|255] ""  CVC_P
 SG_ PCU_DiagRespData27 : 223|8@0+ (1,0) [0|255] ""  CVC_P
 SG_ PCU_DiagRespData28 : 231|8@0+ (1,0) [0|255] ""  CVC_P
 SG_ PCU_DiagRespData29 : 239|8@0+ (1,0) [0|255] ""  CVC_P
 SG_ PCU_DiagRespData30 : 247|8@0+ (1,0) [0|255] ""  CVC_P
 SG_ PCU_DiagRespData31 : 255|8@0+ (1,0) [0|255] ""  CVC_P
 SG_ PCU_DiagRespData32 : 263|8@0+ (1,0) [0|255] ""  CVC_P
 SG_ PCU_DiagRespData33 : 271|8@0+ (1,0) [0|255] ""  CVC_P
 SG_ PCU_DiagRespData34 : 279|8@0+ (1,0) [0|255] ""  CVC_P
 SG_ PCU_DiagRespData35 : 287|8@0+ (1,0) [0|255] ""  CVC_P
 SG_ PCU_DiagRespData36 : 295|8@0+ (1,0) [0|255] ""  CVC_P
 SG_ PCU_DiagRespData37 : 303|8@0+ (1,0) [0|255] ""  CVC_P
 SG_ PCU_DiagRespData38 : 311|8@0+ (1,0) [0|255] ""  CVC_P
 SG_ PCU_DiagRespData39 : 319|8@0+ (1,0) [0|255] ""  CVC_P
 SG_ PCU_DiagRespData40 : 327|8@0+ (1,0) [0|255] ""  CVC_P
 SG_ PCU_DiagRespData41 : 335|8@0+ (1,0) [0|255] ""  CVC_P
 SG_ PCU_DiagRespData42 : 343|8@0+ (1,0) [0|255] ""  CVC_P
 SG_ PCU_DiagRespData43 : 351|8@0+ (1,0) [0|255] ""  CVC_P
 SG_ PCU_DiagRespData44 : 359|8@0+ (1,0) [0|255] ""  CVC_P
 SG_ PCU_DiagRespData45 : 367|8@0+ (1,0) [0|255] ""  CVC_P
 SG_ PCU_DiagRespData46 : 375|8@0+ (1,0) [0|255] ""  CVC_P
 SG_ PCU_DiagRespData47 : 383|8@0+ (1,0) [0|255] ""  CVC_P
 SG_ PCU_DiagRespData48 : 391|8@0+ (1,0) [0|255] ""  CVC_P
 SG_ PCU_DiagRespData49 : 399|8@0+ (1,0) [0|255] ""  CVC_P
 SG_ PCU_DiagRespData50 : 407|8@0+ (1,0) [0|255] ""  CVC_P
 SG_ PCU_DiagRespData51 : 415|8@0+ (1,0) [0|255] ""  CVC_P
 SG_ PCU_DiagRespData52 : 423|8@0+ (1,0) [0|255] ""  CVC_P
 SG_ PCU_DiagRespData53 : 431|8@0+ (1,0) [0|255] ""  CVC_P
 SG_ PCU_DiagRespData54 : 439|8@0+ (1,0) [0|255] ""  CVC_P
 SG_ PCU_DiagRespData55 : 447|8@0+ (1,0) [0|255] ""  CVC_P
 SG_ PCU_DiagRespData56 : 455|8@0+ (1,0) [0|255] ""  CVC_P
 SG_ PCU_DiagRespData57 : 463|8@0+ (1,0) [0|255] ""  CVC_P
 SG_ PCU_DiagRespData58 : 471|8@0+ (1,0) [0|255] ""  CVC_P
 SG_ PCU_DiagRespData59 : 479|8@0+ (1,0) [0|255] ""  CVC_P
 SG_ PCU_DiagRespData60 : 487|8@0+ (1,0) [0|255] ""  CVC_P
 SG_ PCU_DiagRespData61 : 495|8@0+ (1,0) [0|255] ""  CVC_P
 SG_ PCU_DiagRespData62 : 503|8@0+ (1,0) [0|255] ""  CVC_P
 SG_ PCU_DiagRespData63 : 511|8@0+ (1,0) [0|255] ""  CVC_P

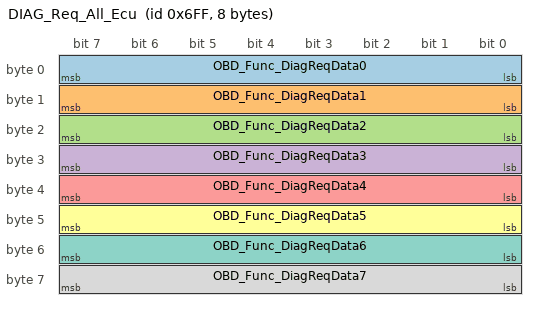
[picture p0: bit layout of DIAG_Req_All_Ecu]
BO_ 1791 DIAG_Req_All_Ecu: 8 CVC_P
 SG_ OBD_Func_DiagReqData0 : 7|8@0+ (1,0) [0|255] ""  BMS,EVCC,FMCU,RMCU,POD_GW,PCU,ADCU_P
 SG_ OBD_Func_DiagReqData1 : 15|8@0+ (1,0) [0|255] ""  BMS,EVCC,FMCU,RMCU,POD_GW,PCU,ADCU_P
 SG_ OBD_Func_DiagReqData2 : 23|8@0+ (1,0) [0|255] ""  BMS,EVCC,FMCU,RMCU,POD_GW,PCU,ADCU_P
 SG_ OBD_Func_DiagReqData3 : 31|8@0+ (1,0) [0|255] ""  BMS,EVCC,FMCU,RMCU,POD_GW,PCU,ADCU_P
 SG_ OBD_Func_DiagReqData4 : 39|8@0+ (1,0) [0|255] ""  BMS,EVCC,FMCU,RMCU,POD_GW,PCU,ADCU_P
 SG_ OBD_Func_DiagReqData5 : 47|8@0+ (1,0) [0|255] ""  BMS,EVCC,FMCU,RMCU,POD_GW,PCU,ADCU_P
 SG_ OBD_Func_DiagReqData6 : 55|8@0+ (1,0) [0|255] ""  BMS,EVCC,FMCU,RMCU,POD_GW,PCU,ADCU_P
 SG_ OBD_Func_DiagReqData7 : 63|8@0+ (1,0) [0|255] ""  BMS,EVCC,FMCU,RMCU,POD_GW,PCU,ADCU_P

CM_ SG_ 1555 BMS_DiagRespData0 "Diagnostic signal Data response";
CM_ SG_ 1555 BMS_DiagRespData1 "Diagnostic signal Data response";
CM_ SG_ 1555 BMS_DiagRespData2 "Diagnostic signal Data response";
CM_ SG_ 1555 BMS_DiagRespData3 "Diagnostic signal Data response";
CM_ SG_ 1555 BMS_DiagRespData4 "Diagnostic signal Data response";
CM_ SG_ 1555 BMS_DiagRespData5 "Diagnostic signal Data response";
CM_ SG_ 1555 BMS_DiagRespData6 "Diagnostic signal Data response";
CM_ SG_ 1555 BMS_DiagRespData7 "Remote Diagnostic signal Data response";
CM_ SG_ 1555 BMS_DiagRespData8 "Diagnostic signal Data response";
CM_ SG_ 1555 BMS_DiagRespData9 "Diagnostic signal Data response";
CM_ SG_ 1555 BMS_DiagRespData10 "Diagnostic signal Data response";
CM_ SG_ 1555 BMS_DiagRespData11 "Diagnostic signal Data response";
CM_ SG_ 1555 BMS_DiagRespData12 "Diagnostic signal Data response";
CM_ SG_ 1555 BMS_DiagRespData13 "Diagnostic signal Data response";
CM_ SG_ 1555 BMS_DiagRespData14 "Diagnostic signal Data response";
CM_ SG_ 1555 BMS_DiagRespData15 "Diagnostic signal Data response";
CM_ SG_ 1555 BMS_DiagRespData16 "Diagnostic signal Data response";
CM_ SG_ 1555 BMS_DiagRespData17 "Diagnostic signal Data response";
CM_ SG_ 1555 BMS_DiagRespData18 "Diagnostic signal Data response";
CM_ SG_ 1555 BMS_DiagRespData19 "Diagnostic signal Data response";
CM_ SG_ 1555 BMS_DiagRespData20 "Diagnostic signal Data response";
CM_ SG_ 1555 BMS_DiagRespData21 "Diagnostic signal Data response";
CM_ SG_ 1555 BMS_DiagRespData22 "Diagnostic signal Data response";
CM_ SG_ 1555 BMS_DiagRespData23 "Diagnostic signal Data response";
CM_ SG_ 1555 BMS_DiagRespData24 "Diagnostic signal Data response";
CM_ SG_ 1555 BMS_DiagRespData25 "Diagnostic signal Data response";
CM_ SG_ 1555 BMS_DiagRespData26 "Diagnostic signal Data response";
CM_ SG_ 1555 BMS_DiagRespData27 "Diagnostic signal Data response";
CM_ SG_ 1555 BMS_DiagRespData28 "Diagnostic signal Data response";
CM_ SG_ 1555 BMS_DiagRespData29 "Diagnostic signal Data response";
CM_ SG_ 1555 BMS_DiagRespData30 "Diagnostic signal Data response";
CM_ SG_ 1555 BMS_DiagRespData31 "Diagnostic signal Data response";
CM_ SG_ 1555 BMS_DiagRespData32 "Diagnostic signal Data response";
CM_ SG_ 1555 BMS_DiagRespData33 "Diagnostic signal Data response";
CM_ SG_ 1555 BMS_DiagRespData34 "Diagnostic signal Data response";
CM_ SG_ 1555 BMS_DiagRespData35 "Diagnostic signal Data response";
CM_ SG_ 1555 BMS_DiagRespData36 "Diagnostic signal Data response";
CM_ SG_ 1555 BMS_DiagRespData37 "Diagnostic signal Data response";
CM_ SG_ 1555 BMS_DiagRespData38 "Diagnostic signal Data response";
CM_ SG_ 1555 BMS_DiagRespData39 "Diagnostic signal Data response";
CM_ SG_ 1555 BMS_DiagRespData40 "Diagnostic signal Data response";
CM_ SG_ 1555 BMS_DiagRespData41 "Diagnostic signal Data response";
CM_ SG_ 1555 BMS_DiagRespData42 "Diagnostic signal Data response";
CM_ SG_ 1555 BMS_DiagRespData43 "Diagnostic signal Data response";
CM_ SG_ 1555 BMS_DiagRespData44 "Diagnostic signal Data response";
CM_ SG_ 1555 BMS_DiagRespData45 "Diagnostic signal Data response";
CM_ SG_ 1555 BMS_DiagRespData46 "Diagnostic signal Data response";
CM_ SG_ 1555 BMS_DiagRespData47 "Diagnostic signal Data response";
CM_ SG_ 1555 BMS_DiagRespData48 "Diagnostic signal Data response";
CM_ SG_ 1555 BMS_DiagRespData49 "Diagnostic signal Data response";
CM_ SG_ 1555 BMS_DiagRespData50 "Diagnostic signal Data response";
CM_ SG_ 1555 BMS_DiagRespData51 "Diagnostic signal Data response";
CM_ SG_ 1555 BMS_DiagRespData52 "Diagnostic signal Data response";
CM_ SG_ 1555 BMS_DiagRespData53 "Diagnostic signal Data response";
CM_ SG_ 1555 BMS_DiagRespData54 "Diagnostic signal Data response";
CM_ SG_ 1555 BMS_DiagRespData55 "Diagnostic signal Data response";
CM_ SG_ 1555 BMS_DiagRespData56 "Diagnostic signal Data response";
CM_ SG_ 1555 BMS_DiagRespData57 "Diagnostic signal Data response";
CM_ SG_ 1555 BMS_DiagRespData58 "Diagnostic signal Data response";
CM_ SG_ 1555 BMS_DiagRespData59 "Diagnostic signal Data response";
CM_ SG_ 1555 BMS_DiagRespData60 "Diagnostic signal Data response";
CM_ SG_ 1555 BMS_DiagRespData61 "Diagnostic signal Data response";
CM_ SG_ 1555 BMS_DiagRespData62 "Diagnostic signal Data response";
CM_ SG_ 1555 BMS_DiagRespData63 "Diagnostic signal Data response";
CM_ SG_ 1690 RMCU_DiagReqData0 "Data0";
CM_ SG_ 1690 RMCU_DiagReqData1 "Data1";
CM_ SG_ 1690 RMCU_DiagReqData2 "Data2";
CM_ SG_ 1690 RMCU_DiagReqData3 "Data3";
CM_ SG_ 1690 RMCU_DiagReqData4 "Data4";
CM_ SG_ 1690 RMCU_DiagReqData5 "Data5";
CM_ SG_ 1690 RMCU_DiagReqData6 "Data6";
CM_ SG_ 1690 RMCU_DiagReqData7 "Data7";
CM_ SG_ 1690 RMCU_DiagReqData8 "Data8";
CM_ SG_ 1690 RMCU_DiagReqData9 "Data9";
CM_ SG_ 1690 RMCU_DiagReqData10 "Data10";
CM_ SG_ 1690 RMCU_DiagReqData11 "Data11";
CM_ SG_ 1690 RMCU_DiagReqData12 "Data12";
CM_ SG_ 1690 RMCU_DiagReqData13 "Data13";
CM_ SG_ 1690 RMCU_DiagReqData14 "Data14";
CM_ SG_ 1690 RMCU_DiagReqData15 "Data15";
CM_ SG_ 1690 RMCU_DiagReqData16 "Data16";
CM_ SG_ 1690 RMCU_DiagReqData17 "Data17";
CM_ SG_ 1690 RMCU_DiagReqData18 "Data18";
CM_ SG_ 1690 RMCU_DiagReqData19 "Data19";
CM_ SG_ 1690 RMCU_DiagReqData20 "Data20";
CM_ SG_ 1690 RMCU_DiagReqData21 "Data21";
CM_ SG_ 1690 RMCU_DiagReqData22 "Data22";
CM_ SG_ 1690 RMCU_DiagReqData23 "Data23";
CM_ SG_ 1690 RMCU_DiagReqData24 "Data24";
CM_ SG_ 1690 RMCU_DiagReqData25 "Data25";
CM_ SG_ 1690 RMCU_DiagReqData26 "Data26";
CM_ SG_ 1690 RMCU_DiagReqData27 "Data27";
CM_ SG_ 1690 RMCU_DiagReqData28 "Data28";
CM_ SG_ 1690 RMCU_DiagReqData29 "Data29";
CM_ SG_ 1690 RMCU_DiagReqData30 "Data30";
CM_ SG_ 1690 RMCU_DiagReqData31 "Data31";
CM_ SG_ 1690 RMCU_DiagReqData32 "Data32";
CM_ SG_ 1690 RMCU_DiagReqData33 "Data33";
CM_ SG_ 1690 RMCU_DiagReqData34 "Data34";
CM_ SG_ 1690 RMCU_DiagReqData35 "Data35";
CM_ SG_ 1690 RMCU_DiagReqData36 "Data36";
CM_ SG_ 1690 RMCU_DiagReqData37 "Data37";
CM_ SG_ 1690 RMCU_DiagReqData38 "Data38";
CM_ SG_ 1690 RMCU_DiagReqData39 "Data39";
CM_ SG_ 1690 RMCU_DiagReqData40 "Data40";
CM_ SG_ 1690 RMCU_DiagReqData41 "Data41";
CM_ SG_ 1690 RMCU_DiagReqData42 "Data42";
CM_ SG_ 1690 RMCU_DiagReqData43 "Data43";
CM_ SG_ 1690 RMCU_DiagReqData44 "Data44";
CM_ SG_ 1690 RMCU_DiagReqData45 "Data45";
CM_ SG_ 1690 RMCU_DiagReqData46 "Data46";
CM_ SG_ 1690 RMCU_DiagReqData47 "Data47";
CM_ SG_ 1690 RMCU_DiagReqData48 "Data48";
CM_ SG_ 1690 RMCU_DiagReqData49 "Data49";
CM_ SG_ 1690 RMCU_DiagReqData50 "Data50";
CM_ SG_ 1690 RMCU_DiagReqData51 "Data51";
CM_ SG_ 1690 RMCU_DiagReqData52 "Data52";
CM_ SG_ 1690 RMCU_DiagReqData53 "Data53";
CM_ SG_ 1690 RMCU_DiagReqData54 "Data54";
CM_ SG_ 1690 RMCU_DiagReqData55 "Data55";
CM_ SG_ 1690 RMCU_DiagReqData56 "Data56";
CM_ SG_ 1690 RMCU_DiagReqData57 "Data57";
CM_ SG_ 1690 RMCU_DiagReqData58 "Data58";
CM_ SG_ 1690 RMCU_DiagReqData59 "Data59";
CM_ SG_ 1690 RMCU_DiagReqData60 "Data60";
CM_ SG_ 1690 RMCU_DiagReqData61 "Data61";
CM_ SG_ 1690 RMCU_DiagReqData62 "Data62";
CM_ SG_ 1690 RMCU_DiagReqData63 "Data63";
CM_ SG_ 1562 RMCU_DiagRespData0 "Data0";
CM_ SG_ 1562 RMCU_DiagRespData1 "Data1";
CM_ SG_ 1562 RMCU_DiagRespData2 "Data2";
CM_ SG_ 1562 RMCU_DiagRespData3 "Data3";
CM_ SG_ 1562 RMCU_DiagRespData4 "Data4";
CM_ SG_ 1562 RMCU_DiagRespData5 "Data5";
CM_ SG_ 1562 RMCU_DiagRespData6 "Data6";
CM_ SG_ 1562 RMCU_DiagRespData7 "Data7";
CM_ SG_ 1562 RMCU_DiagRespData8 "Data8";
CM_ SG_ 1562 RMCU_DiagRespData9 "Data9";
CM_ SG_ 1562 RMCU_DiagRespData10 "Data10";
CM_ SG_ 1562 RMCU_DiagRespData11 "Data11";
CM_ SG_ 1562 RMCU_DiagRespData12 "Data12";
CM_ SG_ 1562 RMCU_DiagRespData13 "Data13";
CM_ SG_ 1562 RMCU_DiagRespData14 "Data14";
CM_ SG_ 1562 RMCU_DiagRespData15 "Data15";
CM_ SG_ 1562 RMCU_DiagRespData16 "Data16";
CM_ SG_ 1562 RMCU_DiagRespData17 "Data17";
CM_ SG_ 1562 RMCU_DiagRespData18 "Data18";
CM_ SG_ 1562 RMCU_DiagRespData19 "Data19";
CM_ SG_ 1562 RMCU_DiagRespData20 "Data20";
CM_ SG_ 1562 RMCU_DiagRespData21 "Data21";
CM_ SG_ 1562 RMCU_DiagRespData22 "Data22";
CM_ SG_ 1562 RMCU_DiagRespData23 "Data23";
CM_ SG_ 1562 RMCU_DiagRespData24 "Data24";
CM_ SG_ 1562 RMCU_DiagRespData25 "Data25";
CM_ SG_ 1562 RMCU_DiagRespData26 "Data26";
CM_ SG_ 1562 RMCU_DiagRespData27 "Data27";
CM_ SG_ 1562 RMCU_DiagRespData28 "Data28";
CM_ SG_ 1562 RMCU_DiagRespData29 "Data29";
CM_ SG_ 1562 RMCU_DiagRespData30 "Data30";
CM_ SG_ 1562 RMCU_DiagRespData31 "Data31";
CM_ SG_ 1562 RMCU_DiagRespData32 "Data32";
CM_ SG_ 1562 RMCU_DiagRespData33 "Data33";
CM_ SG_ 1562 RMCU_DiagRespData34 "Data34";
CM_ SG_ 1562 RMCU_DiagRespData35 "Data35";
CM_ SG_ 1562 RMCU_DiagRespData36 "Data36";
CM_ SG_ 1562 RMCU_DiagRespData37 "Data37";
CM_ SG_ 1562 RMCU_DiagRespData38 "Data38";
CM_ SG_ 1562 RMCU_DiagRespData39 "Data39";
CM_ SG_ 1562 RMCU_DiagRespData40 "Data40";
CM_ SG_ 1562 RMCU_DiagRespData41 "Data41";
CM_ SG_ 1562 RMCU_DiagRespData42 "Data42";
CM_ SG_ 1562 RMCU_DiagRespData43 "Data43";
CM_ SG_ 1562 RMCU_DiagRespData44 "Data44";
CM_ SG_ 1562 RMCU_DiagRespData45 "Data45";
CM_ SG_ 1562 RMCU_DiagRespData46 "Data46";
CM_ SG_ 1562 RMCU_DiagRespData47 "Data47";
CM_ SG_ 1562 RMCU_DiagRespData48 "Data48";
CM_ SG_ 1562 RMCU_DiagRespData49 "Data49";
CM_ SG_ 1562 RMCU_DiagRespData50 "Data50";
CM_ SG_ 1562 RMCU_DiagRespData51 "Data51";
CM_ SG_ 1562 RMCU_DiagRespData52 "Data52";
CM_ SG_ 1562 RMCU_DiagRespData53 "Data53";
CM_ SG_ 1562 RMCU_DiagRespData54 "Data54";
CM_ SG_ 1562 RMCU_DiagRespData55 "Data55";
CM_ SG_ 1562 RMCU_DiagRespData56 "Data56";
CM_ SG_ 1562 RMCU_DiagRespData57 "Data57";
CM_ SG_ 1562 RMCU_DiagRespData58 "Data58";
CM_ SG_ 1562 RMCU_DiagRespData59 "Data59";
CM_ SG_ 1562 RMCU_DiagRespData60 "Data60";
CM_ SG_ 1562 RMCU_DiagRespData61 "Data61";
CM_ SG_ 1562 RMCU_DiagRespData62 "Data62";
CM_ SG_ 1562 RMCU_DiagRespData63 "Data63";
CM_ SG_ 1691 FMCU_DiagReqData0 "Data0";
CM_ SG_ 1691 FMCU_DiagReqData1 "Data1";
CM_ SG_ 1691 FMCU_DiagReqData2 "Data2";
CM_ SG_ 1691 FMCU_DiagReqData3 "Data3";
CM_ SG_ 1691 FMCU_DiagReqData4 "Data4";
CM_ SG_ 1691 FMCU_DiagReqData5 "Data5";
CM_ SG_ 1691 FMCU_DiagReqData6 "Data6";
CM_ SG_ 1691 FMCU_DiagReqData7 "Data7";
CM_ SG_ 1691 FMCU_DiagReqData8 "Data8";
CM_ SG_ 1691 FMCU_DiagReqData9 "Data9";
CM_ SG_ 1691 FMCU_DiagReqData10 "Data10";
CM_ SG_ 1691 FMCU_DiagReqData11 "Data11";
CM_ SG_ 1691 FMCU_DiagReqData12 "Data12";
CM_ SG_ 1691 FMCU_DiagReqData13 "Data13";
CM_ SG_ 1691 FMCU_DiagReqData14 "Data14";
CM_ SG_ 1691 FMCU_DiagReqData15 "Data15";
CM_ SG_ 1691 FMCU_DiagReqData16 "Data16";
CM_ SG_ 1691 FMCU_DiagReqData17 "Data17";
CM_ SG_ 1691 FMCU_DiagReqData18 "Data18";
CM_ SG_ 1691 FMCU_DiagReqData19 "Data19";
CM_ SG_ 1691 FMCU_DiagReqData20 "Data20";
CM_ SG_ 1691 FMCU_DiagReqData21 "Data21";
CM_ SG_ 1691 FMCU_DiagReqData22 "Data22";
CM_ SG_ 1691 FMCU_DiagReqData23 "Data23";
CM_ SG_ 1691 FMCU_DiagReqData24 "Data24";
CM_ SG_ 1691 FMCU_DiagReqData25 "Data25";
CM_ SG_ 1691 FMCU_DiagReqData26 "Data26";
CM_ SG_ 1691 FMCU_DiagReqData27 "Data27";
CM_ SG_ 1691 FMCU_DiagReqData28 "Data28";
CM_ SG_ 1691 FMCU_DiagReqData29 "Data29";
CM_ SG_ 1691 FMCU_DiagReqData30 "Data30";
CM_ SG_ 1691 FMCU_DiagReqData31 "Data31";
CM_ SG_ 1691 FMCU_DiagReqData32 "Data32";
CM_ SG_ 1691 FMCU_DiagReqData33 "Data33";
CM_ SG_ 1691 FMCU_DiagReqData34 "Data34";
CM_ SG_ 1691 FMCU_DiagReqData35 "Data35";
CM_ SG_ 1691 FMCU_DiagReqData36 "Data36";
CM_ SG_ 1691 FMCU_DiagReqData37 "Data37";
CM_ SG_ 1691 FMCU_DiagReqData38 "Data38";
CM_ SG_ 1691 FMCU_DiagReqData39 "Data39";
CM_ SG_ 1691 FMCU_DiagReqData40 "Data40";
CM_ SG_ 1691 FMCU_DiagReqData41 "Data41";
CM_ SG_ 1691 FMCU_DiagReqData42 "Data42";
CM_ SG_ 1691 FMCU_DiagReqData43 "Data43";
CM_ SG_ 1691 FMCU_DiagReqData44 "Data44";
CM_ SG_ 1691 FMCU_DiagReqData45 "Data45";
CM_ SG_ 1691 FMCU_DiagReqData46 "Data46";
CM_ SG_ 1691 FMCU_DiagReqData47 "Data47";
CM_ SG_ 1691 FMCU_DiagReqData48 "Data48";
CM_ SG_ 1691 FMCU_DiagReqData49 "Data49";
CM_ SG_ 1691 FMCU_DiagReqData50 "Data50";
CM_ SG_ 1691 FMCU_DiagReqData51 "Data51";
CM_ SG_ 1691 FMCU_DiagReqData52 "Data52";
CM_ SG_ 1691 FMCU_DiagReqData53 "Data53";
CM_ SG_ 1691 FMCU_DiagReqData54 "Data54";
CM_ SG_ 1691 FMCU_DiagReqData55 "Data55";
CM_ SG_ 1691 FMCU_DiagReqData56 "Data56";
CM_ SG_ 1691 FMCU_DiagReqData57 "Data57";
CM_ SG_ 1691 FMCU_DiagReqData58 "Data58";
CM_ SG_ 1691 FMCU_DiagReqData59 "Data59";
CM_ SG_ 1691 FMCU_DiagReqData60 "Data60";
CM_ SG_ 1691 FMCU_DiagReqData61 "Data61";
CM_ SG_ 1691 FMCU_DiagReqData62 "Data62";
CM_ SG_ 1691 FMCU_DiagReqData63 "Data63";
CM_ SG_ 1563 FMCU_DiagRespData0 "Data0";
CM_ SG_ 1563 FMCU_DiagRespData1 "Data1";
CM_ SG_ 1563 FMCU_DiagRespData2 "Data2";
CM_ SG_ 1563 FMCU_DiagRespData3 "Data3";
CM_ SG_ 1563 FMCU_DiagRespData4 "Data4";
CM_ SG_ 1563 FMCU_DiagRespData5 "Data5";
CM_ SG_ 1563 FMCU_DiagRespData6 "Data6";
CM_ SG_ 1563 FMCU_DiagRespData7 "Data7";
CM_ SG_ 1563 FMCU_DiagRespData8 "Data8";
CM_ SG_ 1563 FMCU_DiagRespData9 "Data9";
CM_ SG_ 1563 FMCU_DiagRespData10 "Data10";
CM_ SG_ 1563 FMCU_DiagRespData11 "Data11";
CM_ SG_ 1563 FMCU_DiagRespData12 "Data12";
CM_ SG_ 1563 FMCU_DiagRespData13 "Data13";
CM_ SG_ 1563 FMCU_DiagRespData14 "Data14";
CM_ SG_ 1563 FMCU_DiagRespData15 "Data15";
CM_ SG_ 1563 FMCU_DiagRespData16 "Data16";
CM_ SG_ 1563 FMCU_DiagRespData17 "Data17";
CM_ SG_ 1563 FMCU_DiagRespData18 "Data18";
CM_ SG_ 1563 FMCU_DiagRespData19 "Data19";
CM_ SG_ 1563 FMCU_DiagRespData20 "Data20";
CM_ SG_ 1563 FMCU_DiagRespData21 "Data21";
CM_ SG_ 1563 FMCU_DiagRespData22 "Data22";
CM_ SG_ 1563 FMCU_DiagRespData23 "Data23";
CM_ SG_ 1563 FMCU_DiagRespData24 "Data24";
CM_ SG_ 1563 FMCU_DiagRespData25 "Data25";
CM_ SG_ 1563 FMCU_DiagRespData26 "Data26";
CM_ SG_ 1563 FMCU_DiagRespData27 "Data27";
CM_ SG_ 1563 FMCU_DiagRespData28 "Data28";
CM_ SG_ 1563 FMCU_DiagRespData29 "Data29";
CM_ SG_ 1563 FMCU_DiagRespData30 "Data30";
CM_ SG_ 1563 FMCU_DiagRespData31 "Data31";
CM_ SG_ 1563 FMCU_DiagRespData32 "Data32";
CM_ SG_ 1563 FMCU_DiagRespData33 "Data33";
CM_ SG_ 1563 FMCU_DiagRespData34 "Data34";
CM_ SG_ 1563 FMCU_DiagRespData35 "Data35";
CM_ SG_ 1563 FMCU_DiagRespData36 "Data36";
CM_ SG_ 1563 FMCU_DiagRespData37 "Data37";
CM_ SG_ 1563 FMCU_DiagRespData38 "Data38";
CM_ SG_ 1563 FMCU_DiagRespData39 "Data39";
CM_ SG_ 1563 FMCU_DiagRespData40 "Data40";
CM_ SG_ 1563 FMCU_DiagRespData41 "Data41";
CM_ SG_ 1563 FMCU_DiagRespData42 "Data42";
CM_ SG_ 1563 FMCU_DiagRespData43 "Data43";
CM_ SG_ 1563 FMCU_DiagRespData44 "Data44";
CM_ SG_ 1563 FMCU_DiagRespData45 "Data45";
CM_ SG_ 1563 FMCU_DiagRespData46 "Data46";
CM_ SG_ 1563 FMCU_DiagRespData47 "Data47";
CM_ SG_ 1563 FMCU_DiagRespData48 "Data48";
CM_ SG_ 1563 FMCU_DiagRespData49 "Data49";
CM_ SG_ 1563 FMCU_DiagRespData50 "Data50";
CM_ SG_ 1563 FMCU_DiagRespData51 "Data51";
CM_ SG_ 1563 FMCU_DiagRespData52 "Data52";
CM_ SG_ 1563 FMCU_DiagRespData53 "Data53";
CM_ SG_ 1563 FMCU_DiagRespData54 "Data54";
CM_ SG_ 1563 FMCU_DiagRespData55 "Data55";
CM_ SG_ 1563 FMCU_DiagRespData56 "Data56";
CM_ SG_ 1563 FMCU_DiagRespData57 "Data57";
CM_ SG_ 1563 FMCU_DiagRespData58 "Data58";
CM_ SG_ 1563 FMCU_DiagRespData59 "Data59";
CM_ SG_ 1563 FMCU_DiagRespData60 "Data60";
CM_ SG_ 1563 FMCU_DiagRespData61 "Data61";
CM_ SG_ 1563 FMCU_DiagRespData62 "Data62";
CM_ SG_ 1563 FMCU_DiagRespData63 "Data63";
CM_ SG_ 1695 EVCC_DiagReqData0 "Data0";
CM_ SG_ 1695 EVCC_DiagReqData1 "Data1";
CM_ SG_ 1695 EVCC_DiagReqData2 "Data2";
CM_ SG_ 1695 EVCC_DiagReqData3 "Data3";
CM_ SG_ 1695 EVCC_DiagReqData4 "Data4";
CM_ SG_ 1695 EVCC_DiagReqData5 "Data5";
CM_ SG_ 1695 EVCC_DiagReqData6 "Data6";
CM_ SG_ 1695 EVCC_DiagReqData7 "Data7";
CM_ SG_ 1695 EVCC_DiagReqData8 "Data8";
CM_ SG_ 1695 EVCC_DiagReqData9 "Data9";
CM_ SG_ 1695 EVCC_DiagReqData10 "Data10";
CM_ SG_ 1695 EVCC_DiagReqData11 "Data11";
CM_ SG_ 1695 EVCC_DiagReqData12 "Data12";
CM_ SG_ 1695 EVCC_DiagReqData13 "Data13";
CM_ SG_ 1695 EVCC_DiagReqData14 "Data14";
CM_ SG_ 1695 EVCC_DiagReqData15 "Data15";
CM_ SG_ 1695 EVCC_DiagReqData16 "Data16";
CM_ SG_ 1695 EVCC_DiagReqData17 "Data17";
CM_ SG_ 1695 EVCC_DiagReqData18 "Data18";
CM_ SG_ 1695 EVCC_DiagReqData19 "Data19";
CM_ SG_ 1695 EVCC_DiagReqData20 "Data20";
CM_ SG_ 1695 EVCC_DiagReqData21 "Data21";
CM_ SG_ 1695 EVCC_DiagReqData22 "Data22";
CM_ SG_ 1695 EVCC_DiagReqData23 "Data23";
CM_ SG_ 1695 EVCC_DiagReqData24 "Data24";
CM_ SG_ 1695 EVCC_DiagReqData25 "Data25";
CM_ SG_ 1695 EVCC_DiagReqData26 "Data26";
CM_ SG_ 1695 EVCC_DiagReqData27 "Data27";
CM_ SG_ 1695 EVCC_DiagReqData28 "Data28";
CM_ SG_ 1695 EVCC_DiagReqData29 "Data29";
CM_ SG_ 1695 EVCC_DiagReqData30 "Data30";
CM_ SG_ 1695 EVCC_DiagReqData31 "Data31";
CM_ SG_ 1695 EVCC_DiagReqData32 "Data32";
CM_ SG_ 1695 EVCC_DiagReqData33 "Data33";
CM_ SG_ 1695 EVCC_DiagReqData34 "Data34";
CM_ SG_ 1695 EVCC_DiagReqData35 "Data35";
CM_ SG_ 1695 EVCC_DiagReqData36 "Data36";
CM_ SG_ 1695 EVCC_DiagReqData37 "Data37";
CM_ SG_ 1695 EVCC_DiagReqData38 "Data38";
CM_ SG_ 1695 EVCC_DiagReqData39 "Data39";
CM_ SG_ 1695 EVCC_DiagReqData40 "Data40";
CM_ SG_ 1695 EVCC_DiagReqData41 "Data41";
CM_ SG_ 1695 EVCC_DiagReqData42 "Data42";
CM_ SG_ 1695 EVCC_DiagReqData43 "Data43";
CM_ SG_ 1695 EVCC_DiagReqData44 "Data44";
CM_ SG_ 1695 EVCC_DiagReqData45 "Data45";
CM_ SG_ 1695 EVCC_DiagReqData46 "Data46";
CM_ SG_ 1695 EVCC_DiagReqData47 "Data47";
CM_ SG_ 1695 EVCC_DiagReqData48 "Data48";
CM_ SG_ 1695 EVCC_DiagReqData49 "Data49";
CM_ SG_ 1695 EVCC_DiagReqData50 "Data50";
CM_ SG_ 1695 EVCC_DiagReqData51 "Data51";
CM_ SG_ 1695 EVCC_DiagReqData52 "Data52";
CM_ SG_ 1695 EVCC_DiagReqData53 "Data53";
CM_ SG_ 1695 EVCC_DiagReqData54 "Data54";
CM_ SG_ 1695 EVCC_DiagReqData55 "Data55";
CM_ SG_ 1695 EVCC_DiagReqData56 "Data56";
CM_ SG_ 1695 EVCC_DiagReqData57 "Data57";
CM_ SG_ 1695 EVCC_DiagReqData58 "Data58";
CM_ SG_ 1695 EVCC_DiagReqData59 "Data59";
CM_ SG_ 1695 EVCC_DiagReqData60 "Data60";
CM_ SG_ 1695 EVCC_DiagReqData61 "Data61";
CM_ SG_ 1695 EVCC_DiagReqData62 "Data62";
CM_ SG_ 1695 EVCC_DiagReqData63 "Data63";
CM_ SG_ 1567 EVCC_DiagRespData0 "Data0";
CM_ SG_ 1567 EVCC_DiagRespData1 "Data1";
CM_ SG_ 1567 EVCC_DiagRespData2 "Data2";
CM_ SG_ 1567 EVCC_DiagRespData3 "Data3";
CM_ SG_ 1567 EVCC_DiagRespData4 "Data4";
CM_ SG_ 1567 EVCC_DiagRespData5 "Data5";
CM_ SG_ 1567 EVCC_DiagRespData6 "Data6";
CM_ SG_ 1567 EVCC_DiagRespData7 "Data7";
CM_ SG_ 1567 EVCC_DiagRespData8 "Data8";
CM_ SG_ 1567 EVCC_DiagRespData9 "Data9";
CM_ SG_ 1567 EVCC_DiagRespData10 "Data10";
CM_ SG_ 1567 EVCC_DiagRespData11 "Data11";
CM_ SG_ 1567 EVCC_DiagRespData12 "Data12";
CM_ SG_ 1567 EVCC_DiagRespData13 "Data13";
CM_ SG_ 1567 EVCC_DiagRespData14 "Data14";
CM_ SG_ 1567 EVCC_DiagRespData15 "Data15";
CM_ SG_ 1567 EVCC_DiagRespData16 "Data16";
CM_ SG_ 1567 EVCC_DiagRespData17 "Data17";
CM_ SG_ 1567 EVCC_DiagRespData18 "Data18";
CM_ SG_ 1567 EVCC_DiagRespData19 "Data19";
CM_ SG_ 1567 EVCC_DiagRespData20 "Data20";
CM_ SG_ 1567 EVCC_DiagRespData21 "Data21";
CM_ SG_ 1567 EVCC_DiagRespData22 "Data22";
CM_ SG_ 1567 EVCC_DiagRespData23 "Data23";
CM_ SG_ 1567 EVCC_DiagRespData24 "Data24";
CM_ SG_ 1567 EVCC_DiagRespData25 "Data25";
CM_ SG_ 1567 EVCC_DiagRespData26 "Data26";
CM_ SG_ 1567 EVCC_DiagRespData27 "Data27";
CM_ SG_ 1567 EVCC_DiagRespData28 "Data28";
CM_ SG_ 1567 EVCC_DiagRespData29 "Data29";
CM_ SG_ 1567 EVCC_DiagRespData30 "Data30";
CM_ SG_ 1567 EVCC_DiagRespData31 "Data31";
CM_ SG_ 1567 EVCC_DiagRespData32 "Data32";
CM_ SG_ 1567 EVCC_DiagRespData33 "Data33";
CM_ SG_ 1567 EVCC_DiagRespData34 "Data34";
CM_ SG_ 1567 EVCC_DiagRespData35 "Data35";
CM_ SG_ 1567 EVCC_DiagRespData36 "Data36";
CM_ SG_ 1567 EVCC_DiagRespData37 "Data37";
CM_ SG_ 1567 EVCC_DiagRespData38 "Data38";
CM_ SG_ 1567 EVCC_DiagRespData39 "Data39";
CM_ SG_ 1567 EVCC_DiagRespData40 "Data40";
CM_ SG_ 1567 EVCC_DiagRespData41 "Data41";
CM_ SG_ 1567 EVCC_DiagRespData42 "Data42";
CM_ SG_ 1567 EVCC_DiagRespData43 "Data43";
CM_ SG_ 1567 EVCC_DiagRespData44 "Data44";
CM_ SG_ 1567 EVCC_DiagRespData45 "Data45";
CM_ SG_ 1567 EVCC_DiagRespData46 "Data46";
CM_ SG_ 1567 EVCC_DiagRespData47 "Data47";
CM_ SG_ 1567 EVCC_DiagRespData48 "Data48";
CM_ SG_ 1567 EVCC_DiagRespData49 "Data49";
CM_ SG_ 1567 EVCC_DiagRespData50 "Data50";
CM_ SG_ 1567 EVCC_DiagRespData51 "Data51";
CM_ SG_ 1567 EVCC_DiagRespData52 "Data52";
CM_ SG_ 1567 EVCC_DiagRespData53 "Data53";
CM_ SG_ 1567 EVCC_DiagRespData54 "Data54";
CM_ SG_ 1567 EVCC_DiagRespData55 "Data55";
CM_ SG_ 1567 EVCC_DiagRespData56 "Data56";
CM_ SG_ 1567 EVCC_DiagRespData57 "Data57";
CM_ SG_ 1567 EVCC_DiagRespData58 "Data58";
CM_ SG_ 1567 EVCC_DiagRespData59 "Data59";
CM_ SG_ 1567 EVCC_DiagRespData60 "Data60";
CM_ SG_ 1567 EVCC_DiagRespData61 "Data61";
CM_ SG_ 1567 EVCC_DiagRespData62 "Data62";
CM_ SG_ 1567 EVCC_DiagRespData63 "Data63";
CM_ SG_ 1725 POD_DCDC_DiagReqData0 "Data0";
CM_ SG_ 1725 POD_DCDC_DiagReqData1 "Data1";
CM_ SG_ 1725 POD_DCDC_DiagReqData2 "Data2";
CM_ SG_ 1725 POD_DCDC_DiagReqData3 "Data3";
CM_ SG_ 1725 POD_DCDC_DiagReqData4 "Data4";
CM_ SG_ 1725 POD_DCDC_DiagReqData5 "Data5";
CM_ SG_ 1725 POD_DCDC_DiagReqData6 "Data6";
CM_ SG_ 1725 POD_DCDC_DiagReqData7 "Data7";
CM_ SG_ 1725 POD_DCDC_DiagReqData8 "Data8";
CM_ SG_ 1725 POD_DCDC_DiagReqData9 "Data9";
CM_ SG_ 1725 POD_DCDC_DiagReqData10 "Data10";
CM_ SG_ 1725 POD_DCDC_DiagReqData11 "Data11";
CM_ SG_ 1725 POD_DCDC_DiagReqData12 "Data12";
CM_ SG_ 1725 POD_DCDC_DiagReqData13 "Data13";
CM_ SG_ 1725 POD_DCDC_DiagReqData14 "Data14";
CM_ SG_ 1725 POD_DCDC_DiagReqData15 "Data15";
CM_ SG_ 1725 POD_DCDC_DiagReqData16 "Data16";
CM_ SG_ 1725 POD_DCDC_DiagReqData17 "Data17";
CM_ SG_ 1725 POD_DCDC_DiagReqData18 "Data18";
CM_ SG_ 1725 POD_DCDC_DiagReqData19 "Data19";
CM_ SG_ 1725 POD_DCDC_DiagReqData20 "Data20";
CM_ SG_ 1725 POD_DCDC_DiagReqData21 "Data21";
CM_ SG_ 1725 POD_DCDC_DiagReqData22 "Data22";
CM_ SG_ 1725 POD_DCDC_DiagReqData23 "Data23";
CM_ SG_ 1725 POD_DCDC_DiagReqData24 "Data24";
CM_ SG_ 1725 POD_DCDC_DiagReqData25 "Data25";
CM_ SG_ 1725 POD_DCDC_DiagReqData26 "Data26";
CM_ SG_ 1725 POD_DCDC_DiagReqData27 "Data27";
CM_ SG_ 1725 POD_DCDC_DiagReqData28 "Data28";
CM_ SG_ 1725 POD_DCDC_DiagReqData29 "Data29";
CM_ SG_ 1725 POD_DCDC_DiagReqData30 "Data30";
CM_ SG_ 1725 POD_DCDC_DiagReqData31 "Data31";
CM_ SG_ 1725 POD_DCDC_DiagReqData32 "Data32";
CM_ SG_ 1725 POD_DCDC_DiagReqData33 "Data33";
CM_ SG_ 1725 POD_DCDC_DiagReqData34 "Data34";
CM_ SG_ 1725 POD_DCDC_DiagReqData35 "Data35";
CM_ SG_ 1725 POD_DCDC_DiagReqData36 "Data36";
CM_ SG_ 1725 POD_DCDC_DiagReqData37 "Data37";
CM_ SG_ 1725 POD_DCDC_DiagReqData38 "Data38";
CM_ SG_ 1725 POD_DCDC_DiagReqData39 "Data39";
CM_ SG_ 1725 POD_DCDC_DiagReqData40 "Data40";
CM_ SG_ 1725 POD_DCDC_DiagReqData41 "Data41";
CM_ SG_ 1725 POD_DCDC_DiagReqData42 "Data42";
CM_ SG_ 1725 POD_DCDC_DiagReqData43 "Data43";
CM_ SG_ 1725 POD_DCDC_DiagReqData44 "Data44";
CM_ SG_ 1725 POD_DCDC_DiagReqData45 "Data45";
CM_ SG_ 1725 POD_DCDC_DiagReqData46 "Data46";
CM_ SG_ 1725 POD_DCDC_DiagReqData47 "Data47";
CM_ SG_ 1725 POD_DCDC_DiagReqData48 "Data48";
CM_ SG_ 1725 POD_DCDC_DiagReqData49 "Data49";
CM_ SG_ 1725 POD_DCDC_DiagReqData50 "Data50";
CM_ SG_ 1725 POD_DCDC_DiagReqData51 "Data51";
CM_ SG_ 1725 POD_DCDC_DiagReqData52 "Data52";
CM_ SG_ 1725 POD_DCDC_DiagReqData53 "Data53";
CM_ SG_ 1725 POD_DCDC_DiagReqData54 "Data54";
CM_ SG_ 1725 POD_DCDC_DiagReqData55 "Data55";
CM_ SG_ 1725 POD_DCDC_DiagReqData56 "Data56";
CM_ SG_ 1725 POD_DCDC_DiagReqData57 "Data57";
CM_ SG_ 1725 POD_DCDC_DiagReqData58 "Data58";
CM_ SG_ 1725 POD_DCDC_DiagReqData59 "Data59";
CM_ SG_ 1725 POD_DCDC_DiagReqData60 "Data60";
CM_ SG_ 1725 POD_DCDC_DiagReqData61 "Data61";
CM_ SG_ 1725 POD_DCDC_DiagReqData62 "Data62";
CM_ SG_ 1725 POD_DCDC_DiagReqData63 "Data63";
CM_ SG_ 1597 POD_DCDC_DiagRespData0 "Data0";
CM_ SG_ 1597 POD_DCDC_DiagRespData1 "Data1";
CM_ SG_ 1597 POD_DCDC_DiagRespData2 "Data2";
CM_ SG_ 1597 POD_DCDC_DiagRespData3 "Data3";
CM_ SG_ 1597 POD_DCDC_DiagRespData4 "Data4";
CM_ SG_ 1597 POD_DCDC_DiagRespData5 "Data5";
CM_ SG_ 1597 POD_DCDC_DiagRespData6 "Data6";
CM_ SG_ 1597 POD_DCDC_DiagRespData7 "Data7";
CM_ SG_ 1597 POD_DCDC_DiagRespData8 "Data8";
CM_ SG_ 1597 POD_DCDC_DiagRespData9 "Data9";
CM_ SG_ 1597 POD_DCDC_DiagRespData10 "Data10";
CM_ SG_ 1597 POD_DCDC_DiagRespData11 "Data11";
CM_ SG_ 1597 POD_DCDC_DiagRespData12 "Data12";
CM_ SG_ 1597 POD_DCDC_DiagRespData13 "Data13";
CM_ SG_ 1597 POD_DCDC_DiagRespData14 "Data14";
CM_ SG_ 1597 POD_DCDC_DiagRespData15 "Data15";
CM_ SG_ 1597 POD_DCDC_DiagRespData16 "Data16";
CM_ SG_ 1597 POD_DCDC_DiagRespData17 "Data17";
CM_ SG_ 1597 POD_DCDC_DiagRespData18 "Data18";
CM_ SG_ 1597 POD_DCDC_DiagRespData19 "Data19";
CM_ SG_ 1597 POD_DCDC_DiagRespData20 "Data20";
CM_ SG_ 1597 POD_DCDC_DiagRespData21 "Data21";
CM_ SG_ 1597 POD_DCDC_DiagRespData22 "Data22";
CM_ SG_ 1597 POD_DCDC_DiagRespData23 "Data23";
CM_ SG_ 1597 POD_DCDC_DiagRespData24 "Data24";
CM_ SG_ 1597 POD_DCDC_DiagRespData25 "Data25";
CM_ SG_ 1597 POD_DCDC_DiagRespData26 "Data26";
CM_ SG_ 1597 POD_DCDC_DiagRespData27 "Data27";
CM_ SG_ 1597 POD_DCDC_DiagRespData28 "Data28";
CM_ SG_ 1597 POD_DCDC_DiagRespData29 "Data29";
CM_ SG_ 1597 POD_DCDC_DiagRespData30 "Data30";
CM_ SG_ 1597 POD_DCDC_DiagRespData31 "Data31";
CM_ SG_ 1597 POD_DCDC_DiagRespData32 "Data32";
CM_ SG_ 1597 POD_DCDC_DiagRespData33 "Data33";
CM_ SG_ 1597 POD_DCDC_DiagRespData34 "Data34";
CM_ SG_ 1597 POD_DCDC_DiagRespData35 "Data35";
CM_ SG_ 1597 POD_DCDC_DiagRespData36 "Data36";
CM_ SG_ 1597 POD_DCDC_DiagRespData37 "Data37";
CM_ SG_ 1597 POD_DCDC_DiagRespData38 "Data38";
CM_ SG_ 1597 POD_DCDC_DiagRespData39 "Data39";
CM_ SG_ 1597 POD_DCDC_DiagRespData40 "Data40";
CM_ SG_ 1597 POD_DCDC_DiagRespData41 "Data41";
CM_ SG_ 1597 POD_DCDC_DiagRespData42 "Data42";
CM_ SG_ 1597 POD_DCDC_DiagRespData43 "Data43";
CM_ SG_ 1597 POD_DCDC_DiagRespData44 "Data44";
CM_ SG_ 1597 POD_DCDC_DiagRespData45 "Data45";
CM_ SG_ 1597 POD_DCDC_DiagRespData46 "Data46";
CM_ SG_ 1597 POD_DCDC_DiagRespData47 "Data47";
CM_ SG_ 1597 POD_DCDC_DiagRespData48 "Data48";
CM_ SG_ 1597 POD_DCDC_DiagRespData49 "Data49";
CM_ SG_ 1597 POD_DCDC_DiagRespData50 "Data50";
CM_ SG_ 1597 POD_DCDC_DiagRespData51 "Data51";
CM_ SG_ 1597 POD_DCDC_DiagRespData52 "Data52";
CM_ SG_ 1597 POD_DCDC_DiagRespData53 "Data53";
CM_ SG_ 1597 POD_DCDC_DiagRespData54 "Data54";
CM_ SG_ 1597 POD_DCDC_DiagRespData55 "Data55";
CM_ SG_ 1597 POD_DCDC_DiagRespData56 "Data56";
CM_ SG_ 1597 POD_DCDC_DiagRespData57 "Data57";
CM_ SG_ 1597 POD_DCDC_DiagRespData58 "Data58";
CM_ SG_ 1597 POD_DCDC_DiagRespData59 "Data59";
CM_ SG_ 1597 POD_DCDC_DiagRespData60 "Data60";
CM_ SG_ 1597 POD_DCDC_DiagRespData61 "Data61";
CM_ SG_ 1597 POD_DCDC_DiagRespData62 "Data62";
CM_ SG_ 1597 POD_DCDC_DiagRespData63 "Data63";
CM_ SG_ 1726 POD_OBC_DiagReqData0 "Data0";
CM_ SG_ 1726 POD_OBC_DiagReqData1 "Data1";
CM_ SG_ 1726 POD_OBC_DiagReqData2 "Data2";
CM_ SG_ 1726 POD_OBC_DiagReqData3 "Data3";
CM_ SG_ 1726 POD_OBC_DiagReqData4 "Data4";
CM_ SG_ 1726 POD_OBC_DiagReqData5 "Data5";
CM_ SG_ 1726 POD_OBC_DiagReqData6 "Data6";
CM_ SG_ 1726 POD_OBC_DiagReqData7 "Data7";
CM_ SG_ 1726 POD_OBC_DiagReqData8 "Data8";
CM_ SG_ 1726 POD_OBC_DiagReqData9 "Data9";
CM_ SG_ 1726 POD_OBC_DiagReqData10 "Data10";
CM_ SG_ 1726 POD_OBC_DiagReqData11 "Data11";
CM_ SG_ 1726 POD_OBC_DiagReqData12 "Data12";
CM_ SG_ 1726 POD_OBC_DiagReqData13 "Data13";
CM_ SG_ 1726 POD_OBC_DiagReqData14 "Data14";
CM_ SG_ 1726 POD_OBC_DiagReqData15 "Data15";
CM_ SG_ 1726 POD_OBC_DiagReqData16 "Data16";
CM_ SG_ 1726 POD_OBC_DiagReqData17 "Data17";
CM_ SG_ 1726 POD_OBC_DiagReqData18 "Data18";
CM_ SG_ 1726 POD_OBC_DiagReqData19 "Data19";
CM_ SG_ 1726 POD_OBC_DiagReqData20 "Data20";
CM_ SG_ 1726 POD_OBC_DiagReqData21 "Data21";
CM_ SG_ 1726 POD_OBC_DiagReqData22 "Data22";
CM_ SG_ 1726 POD_OBC_DiagReqData23 "Data23";
CM_ SG_ 1726 POD_OBC_DiagReqData24 "Data24";
CM_ SG_ 1726 POD_OBC_DiagReqData25 "Data25";
CM_ SG_ 1726 POD_OBC_DiagReqData26 "Data26";
CM_ SG_ 1726 POD_OBC_DiagReqData27 "Data27";
CM_ SG_ 1726 POD_OBC_DiagReqData28 "Data28";
CM_ SG_ 1726 POD_OBC_DiagReqData29 "Data29";
CM_ SG_ 1726 POD_OBC_DiagReqData30 "Data30";
CM_ SG_ 1726 POD_OBC_DiagReqData31 "Data31";
CM_ SG_ 1726 POD_OBC_DiagReqData32 "Data32";
CM_ SG_ 1726 POD_OBC_DiagReqData33 "Data33";
CM_ SG_ 1726 POD_OBC_DiagReqData34 "Data34";
CM_ SG_ 1726 POD_OBC_DiagReqData35 "Data35";
CM_ SG_ 1726 POD_OBC_DiagReqData36 "Data36";
CM_ SG_ 1726 POD_OBC_DiagReqData37 "Data37";
CM_ SG_ 1726 POD_OBC_DiagReqData38 "Data38";
CM_ SG_ 1726 POD_OBC_DiagReqData39 "Data39";
CM_ SG_ 1726 POD_OBC_DiagReqData40 "Data40";
CM_ SG_ 1726 POD_OBC_DiagReqData41 "Data41";
CM_ SG_ 1726 POD_OBC_DiagReqData42 "Data42";
CM_ SG_ 1726 POD_OBC_DiagReqData43 "Data43";
CM_ SG_ 1726 POD_OBC_DiagReqData44 "Data44";
CM_ SG_ 1726 POD_OBC_DiagReqData45 "Data45";
CM_ SG_ 1726 POD_OBC_DiagReqData46 "Data46";
CM_ SG_ 1726 POD_OBC_DiagReqData47 "Data47";
CM_ SG_ 1726 POD_OBC_DiagReqData48 "Data48";
CM_ SG_ 1726 POD_OBC_DiagReqData49 "Data49";
CM_ SG_ 1726 POD_OBC_DiagReqData50 "Data50";
CM_ SG_ 1726 POD_OBC_DiagReqData51 "Data51";
CM_ SG_ 1726 POD_OBC_DiagReqData52 "Data52";
CM_ SG_ 1726 POD_OBC_DiagReqData53 "Data53";
CM_ SG_ 1726 POD_OBC_DiagReqData54 "Data54";
CM_ SG_ 1726 POD_OBC_DiagReqData55 "Data55";
CM_ SG_ 1726 POD_OBC_DiagReqData56 "Data56";
CM_ SG_ 1726 POD_OBC_DiagReqData57 "Data57";
CM_ SG_ 1726 POD_OBC_DiagReqData58 "Data58";
CM_ SG_ 1726 POD_OBC_DiagReqData59 "Data59";
CM_ SG_ 1726 POD_OBC_DiagReqData60 "Data60";
CM_ SG_ 1726 POD_OBC_DiagReqData61 "Data61";
CM_ SG_ 1726 POD_OBC_DiagReqData62 "Data62";
CM_ SG_ 1726 POD_OBC_DiagReqData63 "Data63";
CM_ SG_ 1598 POD_OBC_DiagRespData0 "Response message for UDS";
CM_ SG_ 1598 POD_OBC_DiagRespData1 "Response message for UDS";
CM_ SG_ 1598 POD_OBC_DiagRespData2 "Response message for UDS";
CM_ SG_ 1598 POD_OBC_DiagRespData3 "Response message for UDS";
CM_ SG_ 1598 POD_OBC_DiagRespData4 "Response message for UDS";
CM_ SG_ 1598 POD_OBC_DiagRespData5 "Response message for UDS";
CM_ SG_ 1598 POD_OBC_DiagRespData6 "Response message for UDS";
CM_ SG_ 1598 POD_OBC_DiagRespData7 "Response message for UDS";
CM_ SG_ 1720 PCU_DiagReqData0 "Data0";
CM_ SG_ 1720 PCU_DiagReqData1 "Data1";
CM_ SG_ 1720 PCU_DiagReqData2 "Data2";
CM_ SG_ 1720 PCU_DiagReqData3 "Data3";
CM_ SG_ 1720 PCU_DiagReqData4 "Data4";
CM_ SG_ 1720 PCU_DiagReqData5 "Data5";
CM_ SG_ 1720 PCU_DiagReqData6 "Data6";
CM_ SG_ 1720 PCU_DiagReqData7 "Data7";
CM_ SG_ 1720 PCU_DiagReqData8 "Data8";
CM_ SG_ 1720 PCU_DiagReqData9 "Data9";
CM_ SG_ 1720 PCU_DiagReqData10 "Data10";
CM_ SG_ 1720 PCU_DiagReqData11 "Data11";
CM_ SG_ 1720 PCU_DiagReqData12 "Data12";
CM_ SG_ 1720 PCU_DiagReqData13 "Data13";
CM_ SG_ 1720 PCU_DiagReqData14 "Data14";
CM_ SG_ 1720 PCU_DiagReqData15 "Data15";
CM_ SG_ 1720 PCU_DiagReqData16 "Data16";
CM_ SG_ 1720 PCU_DiagReqData17 "Data17";
CM_ SG_ 1720 PCU_DiagReqData18 "Data18";
CM_ SG_ 1720 PCU_DiagReqData19 "Data19";
CM_ SG_ 1720 PCU_DiagReqData20 "Data20";
CM_ SG_ 1720 PCU_DiagReqData21 "Data21";
CM_ SG_ 1720 PCU_DiagReqData22 "Data22";
CM_ SG_ 1720 PCU_DiagReqData23 "Data23";
CM_ SG_ 1720 PCU_DiagReqData24 "Data24";
CM_ SG_ 1720 PCU_DiagReqData25 "Data25";
CM_ SG_ 1720 PCU_DiagReqData26 "Data26";
CM_ SG_ 1720 PCU_DiagReqData27 "Data27";
CM_ SG_ 1720 PCU_DiagReqData28 "Data28";
CM_ SG_ 1720 PCU_DiagReqData29 "Data29";
CM_ SG_ 1720 PCU_DiagReqData30 "Data30";
CM_ SG_ 1720 PCU_DiagReqData31 "Data31";
CM_ SG_ 1720 PCU_DiagReqData32 "Data32";
CM_ SG_ 1720 PCU_DiagReqData33 "Data33";
CM_ SG_ 1720 PCU_DiagReqData34 "Data34";
CM_ SG_ 1720 PCU_DiagReqData35 "Data35";
CM_ SG_ 1720 PCU_DiagReqData36 "Data36";
CM_ SG_ 1720 PCU_DiagReqData37 "Data37";
CM_ SG_ 1720 PCU_DiagReqData38 "Data38";
CM_ SG_ 1720 PCU_DiagReqData39 "Data39";
CM_ SG_ 1720 PCU_DiagReqData40 "Data40";
CM_ SG_ 1720 PCU_DiagReqData41 "Data41";
CM_ SG_ 1720 PCU_DiagReqData42 "Data42";
CM_ SG_ 1720 PCU_DiagReqData43 "Data43";
CM_ SG_ 1720 PCU_DiagReqData44 "Data44";
CM_ SG_ 1720 PCU_DiagReqData45 "Data45";
CM_ SG_ 1720 PCU_DiagReqData46 "Data46";
CM_ SG_ 1720 PCU_DiagReqData47 "Data47";
CM_ SG_ 1720 PCU_DiagReqData48 "Data48";
CM_ SG_ 1720 PCU_DiagReqData49 "Data49";
CM_ SG_ 1720 PCU_DiagReqData50 "Data50";
CM_ SG_ 1720 PCU_DiagReqData51 "Data51";
CM_ SG_ 1720 PCU_DiagReqData52 "Data52";
CM_ SG_ 1720 PCU_DiagReqData53 "Data53";
CM_ SG_ 1720 PCU_DiagReqData54 "Data54";
CM_ SG_ 1720 PCU_DiagReqData55 "Data55";
CM_ SG_ 1720 PCU_DiagReqData56 "Data56";
CM_ SG_ 1720 PCU_DiagReqData57 "Data57";
CM_ SG_ 1720 PCU_DiagReqData58 "Data58";
CM_ SG_ 1720 PCU_DiagReqData59 "Data59";
CM_ SG_ 1720 PCU_DiagReqData60 "Data60";
CM_ SG_ 1720 PCU_DiagReqData61 "Data61";
CM_ SG_ 1720 PCU_DiagReqData62 "Data62";
CM_ SG_ 1720 PCU_DiagReqData63 "Data63";
CM_ SG_ 1592 PCU_DiagRespData0 "Data0";
CM_ SG_ 1592 PCU_DiagRespData1 "Data1";
CM_ SG_ 1592 PCU_DiagRespData2 "Data2";
CM_ SG_ 1592 PCU_DiagRespData3 "Data3";
CM_ SG_ 1592 PCU_DiagRespData4 "Data4";
CM_ SG_ 1592 PCU_DiagRespData5 "Data5";
CM_ SG_ 1592 PCU_DiagRespData6 "Data6";
CM_ SG_ 1592 PCU_DiagRespData7 "Data7";
CM_ SG_ 1592 PCU_DiagRespData8 "Data8";
CM_ SG_ 1592 PCU_DiagRespData9 "Data9";
CM_ SG_ 1592 PCU_DiagRespData10 "Data10";
CM_ SG_ 1592 PCU_DiagRespData11 "Data11";
CM_ SG_ 1592 PCU_DiagRespData12 "Data12";
CM_ SG_ 1592 PCU_DiagRespData13 "Data13";
CM_ SG_ 1592 PCU_DiagRespData14 "Data14";
CM_ SG_ 1592 PCU_DiagRespData15 "Data15";
CM_ SG_ 1592 PCU_DiagRespData16 "Data16";
CM_ SG_ 1592 PCU_DiagRespData17 "Data17";
CM_ SG_ 1592 PCU_DiagRespData18 "Data18";
CM_ SG_ 1592 PCU_DiagRespData19 "Data19";
CM_ SG_ 1592 PCU_DiagRespData20 "Data20";
CM_ SG_ 1592 PCU_DiagRespData21 "Data21";
CM_ SG_ 1592 PCU_DiagRespData22 "Data22";
CM_ SG_ 1592 PCU_DiagRespData23 "Data23";
CM_ SG_ 1592 PCU_DiagRespData24 "Data24";
CM_ SG_ 1592 PCU_DiagRespData25 "Data25";
CM_ SG_ 1592 PCU_DiagRespData26 "Data26";
CM_ SG_ 1592 PCU_DiagRespData27 "Data27";
CM_ SG_ 1592 PCU_DiagRespData28 "Data28";
CM_ SG_ 1592 PCU_DiagRespData29 "Data29";
CM_ SG_ 1592 PCU_DiagRespData30 "Data30";
CM_ SG_ 1592 PCU_DiagRespData31 "Data31";
CM_ SG_ 1592 PCU_DiagRespData32 "Data32";
CM_ SG_ 1592 PCU_DiagRespData33 "Data33";
CM_ SG_ 1592 PCU_DiagRespData34 "Data34";
CM_ SG_ 1592 PCU_DiagRespData35 "Data35";
CM_ SG_ 1592 PCU_DiagRespData36 "Data36";
CM_ SG_ 1592 PCU_DiagRespData37 "Data37";
CM_ SG_ 1592 PCU_DiagRespData38 "Data38";
CM_ SG_ 1592 PCU_DiagRespData39 "Data39";
CM_ SG_ 1592 PCU_DiagRespData40 "Data40";
CM_ SG_ 1592 PCU_DiagRespData41 "Data41";
CM_ SG_ 1592 PCU_DiagRespData42 "Data42";
CM_ SG_ 1592 PCU_DiagRespData43 "Data43";
CM_ SG_ 1592 PCU_DiagRespData44 "Data44";
CM_ SG_ 1592 PCU_DiagRespData45 "Data45";
CM_ SG_ 1592 PCU_DiagRespData46 "Data46";
CM_ SG_ 1592 PCU_DiagRespData47 "Data47";
CM_ SG_ 1592 PCU_DiagRespData48 "Data48";
CM_ SG_ 1592 PCU_DiagRespData49 "Data49";
CM_ SG_ 1592 PCU_DiagRespData50 "Data50";
CM_ SG_ 1592 PCU_DiagRespData51 "Data51";
CM_ SG_ 1592 PCU_DiagRespData52 "Data52";
CM_ SG_ 1592 PCU_DiagRespData53 "Data53";
CM_ SG_ 1592 PCU_DiagRespData54 "Data54";
CM_ SG_ 1592 PCU_DiagRespData55 "Data55";
CM_ SG_ 1592 PCU_DiagRespData56 "Data56";
CM_ SG_ 1592 PCU_DiagRespData57 "Data57";
CM_ SG_ 1592 PCU_DiagRespData58 "Data58";
CM_ SG_ 1592 PCU_DiagRespData59 "Data59";
CM_ SG_ 1592 PCU_DiagRespData60 "Data60";
CM_ SG_ 1592 PCU_DiagRespData61 "Data61";
CM_ SG_ 1592 PCU_DiagRespData62 "Data62";
CM_ SG_ 1592 PCU_DiagRespData63 "Data63";
CM_ SG_ 1791 OBD_Func_DiagReqData0 "Data0";
CM_ SG_ 1791 OBD_Func_DiagReqData1 "Data1";
CM_ SG_ 1791 OBD_Func_DiagReqData2 "Data2";
CM_ SG_ 1791 OBD_Func_DiagReqData3 "Data3";
CM_ SG_ 1791 OBD_Func_DiagReqData4 "Data4";
CM_ SG_ 1791 OBD_Func_DiagReqData5 "Data5";
CM_ SG_ 1791 OBD_Func_DiagReqData6 "Data6";
CM_ SG_ 1791 OBD_Func_DiagReqData7 "Data7";
BA_DEF_ BO_  "DiagRequest" ENUM  "No","Yes";
BA_DEF_ BO_  "DiagResponse" ENUM  "No","Yes";
BA_DEF_ BO_  "DiagState" ENUM  "No","Yes";
BA_DEF_ BO_  "GenMsgCycleTime" INT 0 65535;
BA_DEF_ BO_  "GenMsgCycleTimeFast" INT 0 65535;
BA_DEF_ BO_  "GenMsgDelayTime" INT 0 65535;
BA_DEF_ BO_  "GenMsgILSupport" ENUM  "No","Yes";
BA_DEF_ BO_  "GenMsgNrOfRepetition" INT 0 65535;
BA_DEF_ BO_  "GenMsgSendType" ENUM  "Cyclic","NoMsgSendType","NotUsed","NotUsed","NotUsed","NotUsed","NotUsed","IfActive","NoMsgSendType","NotUsed";
BA_DEF_ BO_  "NmAsrMessage" ENUM  "No","Yes";
BA_DEF_ BO_  "NmMessage" ENUM  "No","Yes";
BA_DEF_ SG_  "GenSigSendType" ENUM  "Cyclic","NoSigSendType","OnWriteWithRepetition","OnChange","OnChangeWithRepetition","IfActive","IfActiveWithRepetition","OnWrite","NotUsed","NotUsed","NotUsed","NotUsed","NotUsed";
BA_DEF_ SG_  "GenSigStartValue" INT 0 2147483647;
BA_DEF_ SG_  "GenSigTimeoutTime_ALL" INT 0 65535;
BA_DEF_ SG_  "InvalidValue" STRING ;
BA_DEF_ SG_  "GenSigInactiveValue" INT 0 2147483647;
BA_DEF_ BO_  "VFrameFormat" ENUM  "StandardCAN","ExtendedCAN","reserved","J1939PG","reserved","reserved","reserved","reserved","reserved","reserved","reserved","reserved","reserved","reserved","StandardCAN_FD","ExtendedCAN_FD";
BA_DEF_ BO_  "CANFD_BRS" ENUM  "0","1";
BA_DEF_ SG_  "SystemSignalLongSymbol" STRING ;
BA_DEF_DEF_  "DiagRequest" "No";
BA_DEF_DEF_  "DiagResponse" "No";
BA_DEF_DEF_  "DiagState" "No";
BA_DEF_DEF_  "GenMsgCycleTime" 0;
BA_DEF_DEF_  "GenMsgCycleTimeFast" 0;
BA_DEF_DEF_  "GenMsgDelayTime" 0;
BA_DEF_DEF_  "GenMsgILSupport" "Yes";
BA_DEF_DEF_  "GenMsgNrOfRepetition" 0;
BA_DEF_DEF_  "GenMsgSendType" "Cyclic";
BA_DEF_DEF_  "NmAsrMessage" "No";
BA_DEF_DEF_  "NmMessage" "No";
BA_DEF_DEF_  "GenSigSendType" "Cyclic";
BA_DEF_DEF_  "GenSigStartValue" 0;
BA_DEF_DEF_  "GenSigTimeoutTime_ALL" 0;
BA_DEF_DEF_  "InvalidValue" "";
BA_DEF_DEF_  "GenSigInactiveValue" 0;
BA_DEF_DEF_  "VFrameFormat" "StandardCAN_FD";
BA_DEF_DEF_  "CANFD_BRS" "1";
BA_DEF_DEF_  "SystemSignalLongSymbol" "";
BA_ "GenMsgILSupport" BO_ 1555 0;
BA_ "DiagState" BO_ 1555 1;
BA_ "GenMsgSendType" BO_ 1555 1;
BA_ "DiagResponse" BO_ 1555 1;
BA_ "GenMsgILSupport" BO_ 1690 0;
BA_ "DiagState" BO_ 1690 1;
BA_ "GenMsgSendType" BO_ 1690 1;
BA_ "DiagRequest" BO_ 1690 1;
BA_ "GenMsgILSupport" BO_ 1562 0;
BA_ "DiagState" BO_ 1562 1;
BA_ "GenMsgSendType" BO_ 1562 1;
BA_ "DiagResponse" BO_ 1562 1;
BA_ "GenMsgILSupport" BO_ 1691 0;
BA_ "DiagState" BO_ 1691 1;
BA_ "GenMsgSendType" BO_ 1691 1;
BA_ "DiagRequest" BO_ 1691 1;
BA_ "GenMsgILSupport" BO_ 1563 0;
BA_ "DiagState" BO_ 1563 1;
BA_ "GenMsgSendType" BO_ 1563 1;
BA_ "DiagResponse" BO_ 1563 1;
BA_ "GenMsgILSupport" BO_ 1695 0;
BA_ "DiagState" BO_ 1695 1;
BA_ "GenMsgSendType" BO_ 1695 1;
BA_ "DiagRequest" BO_ 1695 1;
BA_ "GenMsgILSupport" BO_ 1567 0;
BA_ "DiagState" BO_ 1567 1;
BA_ "GenMsgSendType" BO_ 1567 1;
BA_ "DiagResponse" BO_ 1567 1;
BA_ "GenMsgILSupport" BO_ 1725 0;
BA_ "DiagState" BO_ 1725 1;
BA_ "GenMsgSendType" BO_ 1725 1;
BA_ "DiagRequest" BO_ 1725 1;
BA_ "GenMsgILSupport" BO_ 1597 0;
BA_ "DiagState" BO_ 1597 1;
BA_ "GenMsgSendType" BO_ 1597 1;
BA_ "DiagResponse" BO_ 1597 1;
BA_ "GenMsgILSupport" BO_ 1726 0;
BA_ "DiagState" BO_ 1726 1;
BA_ "GenMsgSendType" BO_ 1726 1;
BA_ "DiagRequest" BO_ 1726 1;
BA_ "GenMsgILSupport" BO_ 1598 0;
BA_ "DiagState" BO_ 1598 1;
BA_ "GenMsgSendType" BO_ 1598 1;
BA_ "DiagResponse" BO_ 1598 1;
BA_ "GenMsgILSupport" BO_ 1720 0;
BA_ "DiagState" BO_ 1720 1;
BA_ "GenMsgSendType" BO_ 1720 1;
BA_ "DiagRequest" BO_ 1720 1;
BA_ "GenMsgILSupport" BO_ 1592 0;
BA_ "DiagState" BO_ 1592 1;
BA_ "GenMsgSendType" BO_ 1592 1;
BA_ "DiagResponse" BO_ 1592 1;
BA_ "GenMsgILSupport" BO_ 1791 0;
BA_ "DiagState" BO_ 1791 1;
BA_ "GenMsgSendType" BO_ 1791 1;
BA_ "GenSigSendType" SG_ 1555 BMS_DiagRespData0 1;
BA_ "GenSigSendType" SG_ 1555 BMS_DiagRespData1 1;
BA_ "GenSigSendType" SG_ 1555 BMS_DiagRespData2 1;
BA_ "GenSigSendType" SG_ 1555 BMS_DiagRespData3 1;
BA_ "GenSigSendType" SG_ 1555 BMS_DiagRespData4 1;
BA_ "GenSigSendType" SG_ 1555 BMS_DiagRespData5 1;
BA_ "GenSigSendType" SG_ 1555 BMS_DiagRespData6 1;
BA_ "GenSigSendType" SG_ 1555 BMS_DiagRespData7 1;
BA_ "GenSigSendType" SG_ 1555 BMS_DiagRespData8 1;
BA_ "GenSigSendType" SG_ 1555 BMS_DiagRespData9 1;
BA_ "GenSigSendType" SG_ 1555 BMS_DiagRespData10 1;
BA_ "GenSigSendType" SG_ 1555 BMS_DiagRespData11 1;
BA_ "GenSigSendType" SG_ 1555 BMS_DiagRespData12 1;
BA_ "GenSigSendType" SG_ 1555 BMS_DiagRespData13 1;
BA_ "GenSigSendType" SG_ 1555 BMS_DiagRespData14 1;
BA_ "GenSigSendType" SG_ 1555 BMS_DiagRespData15 1;
BA_ "GenSigSendType" SG_ 1555 BMS_DiagRespData16 1;
BA_ "GenSigSendType" SG_ 1555 BMS_DiagRespData17 1;
BA_ "GenSigSendType" SG_ 1555 BMS_DiagRespData18 1;
BA_ "GenSigSendType" SG_ 1555 BMS_DiagRespData19 1;
BA_ "GenSigSendType" SG_ 1555 BMS_DiagRespData20 1;
BA_ "GenSigSendType" SG_ 1555 BMS_DiagRespData21 1;
BA_ "GenSigSendType" SG_ 1555 BMS_DiagRespData22 1;
BA_ "GenSigSendType" SG_ 1555 BMS_DiagRespData23 1;
BA_ "GenSigSendType" SG_ 1555 BMS_DiagRespData24 1;
BA_ "GenSigSendType" SG_ 1555 BMS_DiagRespData25 1;
BA_ "GenSigSendType" SG_ 1555 BMS_DiagRespData26 1;
BA_ "GenSigSendType" SG_ 1555 BMS_DiagRespData27 1;
BA_ "GenSigSendType" SG_ 1555 BMS_DiagRespData28 1;
BA_ "GenSigSendType" SG_ 1555 BMS_DiagRespData29 1;
BA_ "GenSigSendType" SG_ 1555 BMS_DiagRespData30 1;
BA_ "GenSigSendType" SG_ 1555 BMS_DiagRespData31 1;
BA_ "GenSigSendType" SG_ 1555 BMS_DiagRespData32 1;
BA_ "GenSigSendType" SG_ 1555 BMS_DiagRespData33 1;
BA_ "GenSigSendType" SG_ 1555 BMS_DiagRespData34 1;
BA_ "GenSigSendType" SG_ 1555 BMS_DiagRespData35 1;
BA_ "GenSigSendType" SG_ 1555 BMS_DiagRespData36 1;
BA_ "GenSigSendType" SG_ 1555 BMS_DiagRespData37 1;
BA_ "GenSigSendType" SG_ 1555 BMS_DiagRespData38 1;
BA_ "GenSigSendType" SG_ 1555 BMS_DiagRespData39 1;
BA_ "GenSigSendType" SG_ 1555 BMS_DiagRespData40 1;
BA_ "GenSigSendType" SG_ 1555 BMS_DiagRespData41 1;
BA_ "GenSigSendType" SG_ 1555 BMS_DiagRespData42 1;
BA_ "GenSigSendType" SG_ 1555 BMS_DiagRespData43 1;
BA_ "GenSigSendType" SG_ 1555 BMS_DiagRespData44 1;
BA_ "GenSigSendType" SG_ 1555 BMS_DiagRespData45 1;
BA_ "GenSigSendType" SG_ 1555 BMS_DiagRespData46 1;
BA_ "GenSigSendType" SG_ 1555 BMS_DiagRespData47 1;
BA_ "GenSigSendType" SG_ 1555 BMS_DiagRespData48 1;
BA_ "GenSigSendType" SG_ 1555 BMS_DiagRespData49 1;
BA_ "GenSigSendType" SG_ 1555 BMS_DiagRespData50 1;
BA_ "GenSigSendType" SG_ 1555 BMS_DiagRespData51 1;
BA_ "GenSigSendType" SG_ 1555 BMS_DiagRespData52 1;
BA_ "GenSigSendType" SG_ 1555 BMS_DiagRespData53 1;
BA_ "GenSigSendType" SG_ 1555 BMS_DiagRespData54 1;
BA_ "GenSigSendType" SG_ 1555 BMS_DiagRespData55 1;
BA_ "GenSigSendType" SG_ 1555 BMS_DiagRespData56 1;
BA_ "GenSigSendType" SG_ 1555 BMS_DiagRespData57 1;
BA_ "GenSigSendType" SG_ 1555 BMS_DiagRespData58 1;
BA_ "GenSigSendType" SG_ 1555 BMS_DiagRespData59 1;
BA_ "GenSigSendType" SG_ 1555 BMS_DiagRespData60 1;
BA_ "GenSigSendType" SG_ 1555 BMS_DiagRespData61 1;
BA_ "GenSigSendType" SG_ 1555 BMS_DiagRespData62 1;
BA_ "GenSigSendType" SG_ 1555 BMS_DiagRespData63 1;
BA_ "GenSigSendType" SG_ 1690 RMCU_DiagReqData0 1;
BA_ "GenSigSendType" SG_ 1690 RMCU_DiagReqData1 1;
BA_ "GenSigSendType" SG_ 1690 RMCU_DiagReqData2 1;
BA_ "GenSigSendType" SG_ 1690 RMCU_DiagReqData3 1;
BA_ "GenSigSendType" SG_ 1690 RMCU_DiagReqData4 1;
BA_ "GenSigSendType" SG_ 1690 RMCU_DiagReqData5 1;
BA_ "GenSigSendType" SG_ 1690 RMCU_DiagReqData6 1;
BA_ "GenSigSendType" SG_ 1690 RMCU_DiagReqData7 1;
BA_ "GenSigSendType" SG_ 1690 RMCU_DiagReqData8 1;
BA_ "GenSigSendType" SG_ 1690 RMCU_DiagReqData9 1;
BA_ "GenSigSendType" SG_ 1690 RMCU_DiagReqData10 1;
BA_ "GenSigSendType" SG_ 1690 RMCU_DiagReqData11 1;
BA_ "GenSigSendType" SG_ 1690 RMCU_DiagReqData12 1;
BA_ "GenSigSendType" SG_ 1690 RMCU_DiagReqData13 1;
BA_ "GenSigSendType" SG_ 1690 RMCU_DiagReqData14 1;
BA_ "GenSigSendType" SG_ 1690 RMCU_DiagReqData15 1;
BA_ "GenSigSendType" SG_ 1690 RMCU_DiagReqData16 1;
BA_ "GenSigSendType" SG_ 1690 RMCU_DiagReqData17 1;
BA_ "GenSigSendType" SG_ 1690 RMCU_DiagReqData18 1;
BA_ "GenSigSendType" SG_ 1690 RMCU_DiagReqData19 1;
BA_ "GenSigSendType" SG_ 1690 RMCU_DiagReqData20 1;
BA_ "GenSigSendType" SG_ 1690 RMCU_DiagReqData21 1;
BA_ "GenSigSendType" SG_ 1690 RMCU_DiagReqData22 1;
BA_ "GenSigSendType" SG_ 1690 RMCU_DiagReqData23 1;
BA_ "GenSigSendType" SG_ 1690 RMCU_DiagReqData24 1;
BA_ "GenSigSendType" SG_ 1690 RMCU_DiagReqData25 1;
BA_ "GenSigSendType" SG_ 1690 RMCU_DiagReqData26 1;
BA_ "GenSigSendType" SG_ 1690 RMCU_DiagReqData27 1;
BA_ "GenSigSendType" SG_ 1690 RMCU_DiagReqData28 1;
BA_ "GenSigSendType" SG_ 1690 RMCU_DiagReqData29 1;
BA_ "GenSigSendType" SG_ 1690 RMCU_DiagReqData30 1;
BA_ "GenSigSendType" SG_ 1690 RMCU_DiagReqData31 1;
BA_ "GenSigSendType" SG_ 1690 RMCU_DiagReqData32 1;
BA_ "GenSigSendType" SG_ 1690 RMCU_DiagReqData33 1;
BA_ "GenSigSendType" SG_ 1690 RMCU_DiagReqData34 1;
BA_ "GenSigSendType" SG_ 1690 RMCU_DiagReqData35 1;
BA_ "GenSigSendType" SG_ 1690 RMCU_DiagReqData36 1;
BA_ "GenSigSendType" SG_ 1690 RMCU_DiagReqData37 1;
BA_ "GenSigSendType" SG_ 1690 RMCU_DiagReqData38 1;
BA_ "GenSigSendType" SG_ 1690 RMCU_DiagReqData39 1;
BA_ "GenSigSendType" SG_ 1690 RMCU_DiagReqData40 1;
BA_ "GenSigSendType" SG_ 1690 RMCU_DiagReqData41 1;
BA_ "GenSigSendType" SG_ 1690 RMCU_DiagReqData42 1;
BA_ "GenSigSendType" SG_ 1690 RMCU_DiagReqData43 1;
BA_ "GenSigSendType" SG_ 1690 RMCU_DiagReqData44 1;
BA_ "GenSigSendType" SG_ 1690 RMCU_DiagReqData45 1;
BA_ "GenSigSendType" SG_ 1690 RMCU_DiagReqData46 1;
BA_ "GenSigSendType" SG_ 1690 RMCU_DiagReqData47 1;
BA_ "GenSigSendType" SG_ 1690 RMCU_DiagReqData48 1;
BA_ "GenSigSendType" SG_ 1690 RMCU_DiagReqData49 1;
BA_ "GenSigSendType" SG_ 1690 RMCU_DiagReqData50 1;
BA_ "GenSigSendType" SG_ 1690 RMCU_DiagReqData51 1;
BA_ "GenSigSendType" SG_ 1690 RMCU_DiagReqData52 1;
BA_ "GenSigSendType" SG_ 1690 RMCU_DiagReqData53 1;
BA_ "GenSigSendType" SG_ 1690 RMCU_DiagReqData54 1;
BA_ "GenSigSendType" SG_ 1690 RMCU_DiagReqData55 1;
BA_ "GenSigSendType" SG_ 1690 RMCU_DiagReqData56 1;
BA_ "GenSigSendType" SG_ 1690 RMCU_DiagReqData57 1;
BA_ "GenSigSendType" SG_ 1690 RMCU_DiagReqData58 1;
BA_ "GenSigSendType" SG_ 1690 RMCU_DiagReqData59 1;
BA_ "GenSigSendType" SG_ 1690 RMCU_DiagReqData60 1;
BA_ "GenSigSendType" SG_ 1690 RMCU_DiagReqData61 1;
BA_ "GenSigSendType" SG_ 1690 RMCU_DiagReqData62 1;
BA_ "GenSigSendType" SG_ 1690 RMCU_DiagReqData63 1;
BA_ "GenSigSendType" SG_ 1562 RMCU_DiagRespData0 1;
BA_ "GenSigSendType" SG_ 1562 RMCU_DiagRespData1 1;
BA_ "GenSigSendType" SG_ 1562 RMCU_DiagRespData2 1;
BA_ "GenSigSendType" SG_ 1562 RMCU_DiagRespData3 1;
BA_ "GenSigSendType" SG_ 1562 RMCU_DiagRespData4 1;
BA_ "GenSigSendType" SG_ 1562 RMCU_DiagRespData5 1;
BA_ "GenSigSendType" SG_ 1562 RMCU_DiagRespData6 1;
BA_ "GenSigSendType" SG_ 1562 RMCU_DiagRespData7 1;
BA_ "GenSigSendType" SG_ 1562 RMCU_DiagRespData8 1;
BA_ "GenSigSendType" SG_ 1562 RMCU_DiagRespData9 1;
BA_ "GenSigSendType" SG_ 1562 RMCU_DiagRespData10 1;
BA_ "GenSigSendType" SG_ 1562 RMCU_DiagRespData11 1;
BA_ "GenSigSendType" SG_ 1562 RMCU_DiagRespData12 1;
BA_ "GenSigSendType" SG_ 1562 RMCU_DiagRespData13 1;
BA_ "GenSigSendType" SG_ 1562 RMCU_DiagRespData14 1;
BA_ "GenSigSendType" SG_ 1562 RMCU_DiagRespData15 1;
BA_ "GenSigSendType" SG_ 1562 RMCU_DiagRespData16 1;
BA_ "GenSigSendType" SG_ 1562 RMCU_DiagRespData17 1;
BA_ "GenSigSendType" SG_ 1562 RMCU_DiagRespData18 1;
BA_ "GenSigSendType" SG_ 1562 RMCU_DiagRespData19 1;
BA_ "GenSigSendType" SG_ 1562 RMCU_DiagRespData20 1;
BA_ "GenSigSendType" SG_ 1562 RMCU_DiagRespData21 1;
BA_ "GenSigSendType" SG_ 1562 RMCU_DiagRespData22 1;
BA_ "GenSigSendType" SG_ 1562 RMCU_DiagRespData23 1;
BA_ "GenSigSendType" SG_ 1562 RMCU_DiagRespData24 1;
BA_ "GenSigSendType" SG_ 1562 RMCU_DiagRespData25 1;
BA_ "GenSigSendType" SG_ 1562 RMCU_DiagRespData26 1;
BA_ "GenSigSendType" SG_ 1562 RMCU_DiagRespData27 1;
BA_ "GenSigSendType" SG_ 1562 RMCU_DiagRespData28 1;
BA_ "GenSigSendType" SG_ 1562 RMCU_DiagRespData29 1;
BA_ "GenSigSendType" SG_ 1562 RMCU_DiagRespData30 1;
BA_ "GenSigSendType" SG_ 1562 RMCU_DiagRespData31 1;
BA_ "GenSigSendType" SG_ 1562 RMCU_DiagRespData32 1;
BA_ "GenSigSendType" SG_ 1562 RMCU_DiagRespData33 1;
BA_ "GenSigSendType" SG_ 1562 RMCU_DiagRespData34 1;
BA_ "GenSigSendType" SG_ 1562 RMCU_DiagRespData35 1;
BA_ "GenSigSendType" SG_ 1562 RMCU_DiagRespData36 1;
BA_ "GenSigSendType" SG_ 1562 RMCU_DiagRespData37 1;
BA_ "GenSigSendType" SG_ 1562 RMCU_DiagRespData38 1;
BA_ "GenSigSendType" SG_ 1562 RMCU_DiagRespData39 1;
BA_ "GenSigSendType" SG_ 1562 RMCU_DiagRespData40 1;
BA_ "GenSigSendType" SG_ 1562 RMCU_DiagRespData41 1;
BA_ "GenSigSendType" SG_ 1562 RMCU_DiagRespData42 1;
BA_ "GenSigSendType" SG_ 1562 RMCU_DiagRespData43 1;
BA_ "GenSigSendType" SG_ 1562 RMCU_DiagRespData44 1;
BA_ "GenSigSendType" SG_ 1562 RMCU_DiagRespData45 1;
BA_ "GenSigSendType" SG_ 1562 RMCU_DiagRespData46 1;
BA_ "GenSigSendType" SG_ 1562 RMCU_DiagRespData47 1;
BA_ "GenSigSendType" SG_ 1562 RMCU_DiagRespData48 1;
BA_ "GenSigSendType" SG_ 1562 RMCU_DiagRespData49 1;
BA_ "GenSigSendType" SG_ 1562 RMCU_DiagRespData50 1;
BA_ "GenSigSendType" SG_ 1562 RMCU_DiagRespData51 1;
BA_ "GenSigSendType" SG_ 1562 RMCU_DiagRespData52 1;
BA_ "GenSigSendType" SG_ 1562 RMCU_DiagRespData53 1;
BA_ "GenSigSendType" SG_ 1562 RMCU_DiagRespData54 1;
BA_ "GenSigSendType" SG_ 1562 RMCU_DiagRespData55 1;
BA_ "GenSigSendType" SG_ 1562 RMCU_DiagRespData56 1;
BA_ "GenSigSendType" SG_ 1562 RMCU_DiagRespData57 1;
BA_ "GenSigSendType" SG_ 1562 RMCU_DiagRespData58 1;
BA_ "GenSigSendType" SG_ 1562 RMCU_DiagRespData59 1;
BA_ "GenSigSendType" SG_ 1562 RMCU_DiagRespData60 1;
BA_ "GenSigSendType" SG_ 1562 RMCU_DiagRespData61 1;
BA_ "GenSigSendType" SG_ 1562 RMCU_DiagRespData62 1;
BA_ "GenSigSendType" SG_ 1562 RMCU_DiagRespData63 1;
BA_ "GenSigSendType" SG_ 1691 FMCU_DiagReqData0 1;
BA_ "GenSigSendType" SG_ 1691 FMCU_DiagReqData1 1;
BA_ "GenSigSendType" SG_ 1691 FMCU_DiagReqData2 1;
BA_ "GenSigSendType" SG_ 1691 FMCU_DiagReqData3 1;
BA_ "GenSigSendType" SG_ 1691 FMCU_DiagReqData4 1;
BA_ "GenSigSendType" SG_ 1691 FMCU_DiagReqData5 1;
BA_ "GenSigSendType" SG_ 1691 FMCU_DiagReqData6 1;
BA_ "GenSigSendType" SG_ 1691 FMCU_DiagReqData7 1;
BA_ "GenSigSendType" SG_ 1691 FMCU_DiagReqData8 1;
BA_ "GenSigSendType" SG_ 1691 FMCU_DiagReqData9 1;
BA_ "GenSigSendType" SG_ 1691 FMCU_DiagReqData10 1;
BA_ "GenSigSendType" SG_ 1691 FMCU_DiagReqData11 1;
BA_ "GenSigSendType" SG_ 1691 FMCU_DiagReqData12 1;
BA_ "GenSigSendType" SG_ 1691 FMCU_DiagReqData13 1;
BA_ "GenSigSendType" SG_ 1691 FMCU_DiagReqData14 1;
BA_ "GenSigSendType" SG_ 1691 FMCU_DiagReqData15 1;
BA_ "GenSigSendType" SG_ 1691 FMCU_DiagReqData16 1;
BA_ "GenSigSendType" SG_ 1691 FMCU_DiagReqData17 1;
BA_ "GenSigSendType" SG_ 1691 FMCU_DiagReqData18 1;
BA_ "GenSigSendType" SG_ 1691 FMCU_DiagReqData19 1;
BA_ "GenSigSendType" SG_ 1691 FMCU_DiagReqData20 1;
BA_ "GenSigSendType" SG_ 1691 FMCU_DiagReqData21 1;
BA_ "GenSigSendType" SG_ 1691 FMCU_DiagReqData22 1;
BA_ "GenSigSendType" SG_ 1691 FMCU_DiagReqData23 1;
BA_ "GenSigSendType" SG_ 1691 FMCU_DiagReqData24 1;
BA_ "GenSigSendType" SG_ 1691 FMCU_DiagReqData25 1;
BA_ "GenSigSendType" SG_ 1691 FMCU_DiagReqData26 1;
BA_ "GenSigSendType" SG_ 1691 FMCU_DiagReqData27 1;
BA_ "GenSigSendType" SG_ 1691 FMCU_DiagReqData28 1;
BA_ "GenSigSendType" SG_ 1691 FMCU_DiagReqData29 1;
BA_ "GenSigSendType" SG_ 1691 FMCU_DiagReqData30 1;
BA_ "GenSigSendType" SG_ 1691 FMCU_DiagReqData31 1;
BA_ "GenSigSendType" SG_ 1691 FMCU_DiagReqData32 1;
BA_ "GenSigSendType" SG_ 1691 FMCU_DiagReqData33 1;
BA_ "GenSigSendType" SG_ 1691 FMCU_DiagReqData34 1;
BA_ "GenSigSendType" SG_ 1691 FMCU_DiagReqData35 1;
BA_ "GenSigSendType" SG_ 1691 FMCU_DiagReqData36 1;
BA_ "GenSigSendType" SG_ 1691 FMCU_DiagReqData37 1;
BA_ "GenSigSendType" SG_ 1691 FMCU_DiagReqData38 1;
BA_ "GenSigSendType" SG_ 1691 FMCU_DiagReqData39 1;
BA_ "GenSigSendType" SG_ 1691 FMCU_DiagReqData40 1;
BA_ "GenSigSendType" SG_ 1691 FMCU_DiagReqData41 1;
BA_ "GenSigSendType" SG_ 1691 FMCU_DiagReqData42 1;
BA_ "GenSigSendType" SG_ 1691 FMCU_DiagReqData43 1;
BA_ "GenSigSendType" SG_ 1691 FMCU_DiagReqData44 1;
BA_ "GenSigSendType" SG_ 1691 FMCU_DiagReqData45 1;
BA_ "GenSigSendType" SG_ 1691 FMCU_DiagReqData46 1;
BA_ "GenSigSendType" SG_ 1691 FMCU_DiagReqData47 1;
BA_ "GenSigSendType" SG_ 1691 FMCU_DiagReqData48 1;
BA_ "GenSigSendType" SG_ 1691 FMCU_DiagReqData49 1;
BA_ "GenSigSendType" SG_ 1691 FMCU_DiagReqData50 1;
BA_ "GenSigSendType" SG_ 1691 FMCU_DiagReqData51 1;
BA_ "GenSigSendType" SG_ 1691 FMCU_DiagReqData52 1;
BA_ "GenSigSendType" SG_ 1691 FMCU_DiagReqData53 1;
BA_ "GenSigSendType" SG_ 1691 FMCU_DiagReqData54 1;
BA_ "GenSigSendType" SG_ 1691 FMCU_DiagReqData55 1;
BA_ "GenSigSendType" SG_ 1691 FMCU_DiagReqData56 1;
BA_ "GenSigSendType" SG_ 1691 FMCU_DiagReqData57 1;
BA_ "GenSigSendType" SG_ 1691 FMCU_DiagReqData58 1;
BA_ "GenSigSendType" SG_ 1691 FMCU_DiagReqData59 1;
BA_ "GenSigSendType" SG_ 1691 FMCU_DiagReqData60 1;
BA_ "GenSigSendType" SG_ 1691 FMCU_DiagReqData61 1;
BA_ "GenSigSendType" SG_ 1691 FMCU_DiagReqData62 1;
BA_ "GenSigSendType" SG_ 1691 FMCU_DiagReqData63 1;
BA_ "GenSigSendType" SG_ 1563 FMCU_DiagRespData0 1;
BA_ "GenSigSendType" SG_ 1563 FMCU_DiagRespData1 1;
BA_ "GenSigSendType" SG_ 1563 FMCU_DiagRespData2 1;
BA_ "GenSigSendType" SG_ 1563 FMCU_DiagRespData3 1;
BA_ "GenSigSendType" SG_ 1563 FMCU_DiagRespData4 1;
BA_ "GenSigSendType" SG_ 1563 FMCU_DiagRespData5 1;
BA_ "GenSigSendType" SG_ 1563 FMCU_DiagRespData6 1;
BA_ "GenSigSendType" SG_ 1563 FMCU_DiagRespData7 1;
BA_ "GenSigSendType" SG_ 1563 FMCU_DiagRespData8 1;
BA_ "GenSigSendType" SG_ 1563 FMCU_DiagRespData9 1;
BA_ "GenSigSendType" SG_ 1563 FMCU_DiagRespData10 1;
BA_ "GenSigSendType" SG_ 1563 FMCU_DiagRespData11 1;
BA_ "GenSigSendType" SG_ 1563 FMCU_DiagRespData12 1;
BA_ "GenSigSendType" SG_ 1563 FMCU_DiagRespData13 1;
BA_ "GenSigSendType" SG_ 1563 FMCU_DiagRespData14 1;
BA_ "GenSigSendType" SG_ 1563 FMCU_DiagRespData15 1;
BA_ "GenSigSendType" SG_ 1563 FMCU_DiagRespData16 1;
BA_ "GenSigSendType" SG_ 1563 FMCU_DiagRespData17 1;
BA_ "GenSigSendType" SG_ 1563 FMCU_DiagRespData18 1;
BA_ "GenSigSendType" SG_ 1563 FMCU_DiagRespData19 1;
BA_ "GenSigSendType" SG_ 1563 FMCU_DiagRespData20 1;
BA_ "GenSigSendType" SG_ 1563 FMCU_DiagRespData21 1;
BA_ "GenSigSendType" SG_ 1563 FMCU_DiagRespData22 1;
BA_ "GenSigSendType" SG_ 1563 FMCU_DiagRespData23 1;
BA_ "GenSigSendType" SG_ 1563 FMCU_DiagRespData24 1;
BA_ "GenSigSendType" SG_ 1563 FMCU_DiagRespData25 1;
BA_ "GenSigSendType" SG_ 1563 FMCU_DiagRespData26 1;
BA_ "GenSigSendType" SG_ 1563 FMCU_DiagRespData27 1;
BA_ "GenSigSendType" SG_ 1563 FMCU_DiagRespData28 1;
BA_ "GenSigSendType" SG_ 1563 FMCU_DiagRespData29 1;
BA_ "GenSigSendType" SG_ 1563 FMCU_DiagRespData30 1;
BA_ "GenSigSendType" SG_ 1563 FMCU_DiagRespData31 1;
BA_ "GenSigSendType" SG_ 1563 FMCU_DiagRespData32 1;
BA_ "GenSigSendType" SG_ 1563 FMCU_DiagRespData33 1;
BA_ "GenSigSendType" SG_ 1563 FMCU_DiagRespData34 1;
BA_ "GenSigSendType" SG_ 1563 FMCU_DiagRespData35 1;
BA_ "GenSigSendType" SG_ 1563 FMCU_DiagRespData36 1;
BA_ "GenSigSendType" SG_ 1563 FMCU_DiagRespData37 1;
BA_ "GenSigSendType" SG_ 1563 FMCU_DiagRespData38 1;
BA_ "GenSigSendType" SG_ 1563 FMCU_DiagRespData39 1;
BA_ "GenSigSendType" SG_ 1563 FMCU_DiagRespData40 1;
BA_ "GenSigSendType" SG_ 1563 FMCU_DiagRespData41 1;
BA_ "GenSigSendType" SG_ 1563 FMCU_DiagRespData42 1;
BA_ "GenSigSendType" SG_ 1563 FMCU_DiagRespData43 1;
BA_ "GenSigSendType" SG_ 1563 FMCU_DiagRespData44 1;
BA_ "GenSigSendType" SG_ 1563 FMCU_DiagRespData45 1;
BA_ "GenSigSendType" SG_ 1563 FMCU_DiagRespData46 1;
BA_ "GenSigSendType" SG_ 1563 FMCU_DiagRespData47 1;
BA_ "GenSigSendType" SG_ 1563 FMCU_DiagRespData48 1;
BA_ "GenSigSendType" SG_ 1563 FMCU_DiagRespData49 1;
BA_ "GenSigSendType" SG_ 1563 FMCU_DiagRespData50 1;
BA_ "GenSigSendType" SG_ 1563 FMCU_DiagRespData51 1;
BA_ "GenSigSendType" SG_ 1563 FMCU_DiagRespData52 1;
BA_ "GenSigSendType" SG_ 1563 FMCU_DiagRespData53 1;
BA_ "GenSigSendType" SG_ 1563 FMCU_DiagRespData54 1;
BA_ "GenSigSendType" SG_ 1563 FMCU_DiagRespData55 1;
BA_ "GenSigSendType" SG_ 1563 FMCU_DiagRespData56 1;
BA_ "GenSigSendType" SG_ 1563 FMCU_DiagRespData57 1;
BA_ "GenSigSendType" SG_ 1563 FMCU_DiagRespData58 1;
BA_ "GenSigSendType" SG_ 1563 FMCU_DiagRespData59 1;
BA_ "GenSigSendType" SG_ 1563 FMCU_DiagRespData60 1;
BA_ "GenSigSendType" SG_ 1563 FMCU_DiagRespData61 1;
BA_ "GenSigSendType" SG_ 1563 FMCU_DiagRespData62 1;
BA_ "GenSigSendType" SG_ 1563 FMCU_DiagRespData63 1;
BA_ "GenSigSendType" SG_ 1695 EVCC_DiagReqData0 1;
BA_ "GenSigSendType" SG_ 1695 EVCC_DiagReqData1 1;
BA_ "GenSigSendType" SG_ 1695 EVCC_DiagReqData2 1;
BA_ "GenSigSendType" SG_ 1695 EVCC_DiagReqData3 1;
BA_ "GenSigSendType" SG_ 1695 EVCC_DiagReqData4 1;
BA_ "GenSigSendType" SG_ 1695 EVCC_DiagReqData5 1;
BA_ "GenSigSendType" SG_ 1695 EVCC_DiagReqData6 1;
BA_ "GenSigSendType" SG_ 1695 EVCC_DiagReqData7 1;
BA_ "GenSigSendType" SG_ 1695 EVCC_DiagReqData8 1;
BA_ "GenSigSendType" SG_ 1695 EVCC_DiagReqData9 1;
BA_ "GenSigSendType" SG_ 1695 EVCC_DiagReqData10 1;
BA_ "GenSigSendType" SG_ 1695 EVCC_DiagReqData11 1;
BA_ "GenSigSendType" SG_ 1695 EVCC_DiagReqData12 1;
BA_ "GenSigSendType" SG_ 1695 EVCC_DiagReqData13 1;
BA_ "GenSigSendType" SG_ 1695 EVCC_DiagReqData14 1;
BA_ "GenSigSendType" SG_ 1695 EVCC_DiagReqData15 1;
BA_ "GenSigSendType" SG_ 1695 EVCC_DiagReqData16 1;
BA_ "GenSigSendType" SG_ 1695 EVCC_DiagReqData17 1;
BA_ "GenSigSendType" SG_ 1695 EVCC_DiagReqData18 1;
BA_ "GenSigSendType" SG_ 1695 EVCC_DiagReqData19 1;
BA_ "GenSigSendType" SG_ 1695 EVCC_DiagReqData20 1;
BA_ "GenSigSendType" SG_ 1695 EVCC_DiagReqData21 1;
BA_ "GenSigSendType" SG_ 1695 EVCC_DiagReqData22 1;
BA_ "GenSigSendType" SG_ 1695 EVCC_DiagReqData23 1;
BA_ "GenSigSendType" SG_ 1695 EVCC_DiagReqData24 1;
BA_ "GenSigSendType" SG_ 1695 EVCC_DiagReqData25 1;
BA_ "GenSigSendType" SG_ 1695 EVCC_DiagReqData26 1;
BA_ "GenSigSendType" SG_ 1695 EVCC_DiagReqData27 1;
BA_ "GenSigSendType" SG_ 1695 EVCC_DiagReqData28 1;
BA_ "GenSigSendType" SG_ 1695 EVCC_DiagReqData29 1;
BA_ "GenSigSendType" SG_ 1695 EVCC_DiagReqData30 1;
BA_ "GenSigSendType" SG_ 1695 EVCC_DiagReqData31 1;
BA_ "GenSigSendType" SG_ 1695 EVCC_DiagReqData32 1;
BA_ "GenSigSendType" SG_ 1695 EVCC_DiagReqData33 1;
BA_ "GenSigSendType" SG_ 1695 EVCC_DiagReqData34 1;
BA_ "GenSigSendType" SG_ 1695 EVCC_DiagReqData35 1;
BA_ "GenSigSendType" SG_ 1695 EVCC_DiagReqData36 1;
BA_ "GenSigSendType" SG_ 1695 EVCC_DiagReqData37 1;
BA_ "GenSigSendType" SG_ 1695 EVCC_DiagReqData38 1;
BA_ "GenSigSendType" SG_ 1695 EVCC_DiagReqData39 1;
BA_ "GenSigSendType" SG_ 1695 EVCC_DiagReqData40 1;
BA_ "GenSigSendType" SG_ 1695 EVCC_DiagReqData41 1;
BA_ "GenSigSendType" SG_ 1695 EVCC_DiagReqData42 1;
BA_ "GenSigSendType" SG_ 1695 EVCC_DiagReqData43 1;
BA_ "GenSigSendType" SG_ 1695 EVCC_DiagReqData44 1;
BA_ "GenSigSendType" SG_ 1695 EVCC_DiagReqData45 1;
BA_ "GenSigSendType" SG_ 1695 EVCC_DiagReqData46 1;
BA_ "GenSigSendType" SG_ 1695 EVCC_DiagReqData47 1;
BA_ "GenSigSendType" SG_ 1695 EVCC_DiagReqData48 1;
BA_ "GenSigSendType" SG_ 1695 EVCC_DiagReqData49 1;
BA_ "GenSigSendType" SG_ 1695 EVCC_DiagReqData50 1;
BA_ "GenSigSendType" SG_ 1695 EVCC_DiagReqData51 1;
BA_ "GenSigSendType" SG_ 1695 EVCC_DiagReqData52 1;
BA_ "GenSigSendType" SG_ 1695 EVCC_DiagReqData53 1;
BA_ "GenSigSendType" SG_ 1695 EVCC_DiagReqData54 1;
BA_ "GenSigSendType" SG_ 1695 EVCC_DiagReqData55 1;
BA_ "GenSigSendType" SG_ 1695 EVCC_DiagReqData56 1;
BA_ "GenSigSendType" SG_ 1695 EVCC_DiagReqData57 1;
BA_ "GenSigSendType" SG_ 1695 EVCC_DiagReqData58 1;
BA_ "GenSigSendType" SG_ 1695 EVCC_DiagReqData59 1;
BA_ "GenSigSendType" SG_ 1695 EVCC_DiagReqData60 1;
BA_ "GenSigSendType" SG_ 1695 EVCC_DiagReqData61 1;
BA_ "GenSigSendType" SG_ 1695 EVCC_DiagReqData62 1;
BA_ "GenSigSendType" SG_ 1695 EVCC_DiagReqData63 1;
BA_ "GenSigSendType" SG_ 1567 EVCC_DiagRespData0 1;
BA_ "GenSigSendType" SG_ 1567 EVCC_DiagRespData1 1;
BA_ "GenSigSendType" SG_ 1567 EVCC_DiagRespData2 1;
BA_ "GenSigSendType" SG_ 1567 EVCC_DiagRespData3 1;
BA_ "GenSigSendType" SG_ 1567 EVCC_DiagRespData4 1;
BA_ "GenSigSendType" SG_ 1567 EVCC_DiagRespData5 1;
BA_ "GenSigSendType" SG_ 1567 EVCC_DiagRespData6 1;
BA_ "GenSigSendType" SG_ 1567 EVCC_DiagRespData7 1;
BA_ "GenSigSendType" SG_ 1567 EVCC_DiagRespData8 1;
BA_ "GenSigSendType" SG_ 1567 EVCC_DiagRespData9 1;
BA_ "GenSigSendType" SG_ 1567 EVCC_DiagRespData10 1;
BA_ "GenSigSendType" SG_ 1567 EVCC_DiagRespData11 1;
BA_ "GenSigSendType" SG_ 1567 EVCC_DiagRespData12 1;
BA_ "GenSigSendType" SG_ 1567 EVCC_DiagRespData13 1;
BA_ "GenSigSendType" SG_ 1567 EVCC_DiagRespData14 1;
BA_ "GenSigSendType" SG_ 1567 EVCC_DiagRespData15 1;
BA_ "GenSigSendType" SG_ 1567 EVCC_DiagRespData16 1;
BA_ "GenSigSendType" SG_ 1567 EVCC_DiagRespData17 1;
BA_ "GenSigSendType" SG_ 1567 EVCC_DiagRespData18 1;
BA_ "GenSigSendType" SG_ 1567 EVCC_DiagRespData19 1;
BA_ "GenSigSendType" SG_ 1567 EVCC_DiagRespData20 1;
BA_ "GenSigSendType" SG_ 1567 EVCC_DiagRespData21 1;
BA_ "GenSigSendType" SG_ 1567 EVCC_DiagRespData22 1;
BA_ "GenSigSendType" SG_ 1567 EVCC_DiagRespData23 1;
BA_ "GenSigSendType" SG_ 1567 EVCC_DiagRespData24 1;
BA_ "GenSigSendType" SG_ 1567 EVCC_DiagRespData25 1;
BA_ "GenSigSendType" SG_ 1567 EVCC_DiagRespData26 1;
BA_ "GenSigSendType" SG_ 1567 EVCC_DiagRespData27 1;
BA_ "GenSigSendType" SG_ 1567 EVCC_DiagRespData28 1;
BA_ "GenSigSendType" SG_ 1567 EVCC_DiagRespData29 1;
BA_ "GenSigSendType" SG_ 1567 EVCC_DiagRespData30 1;
BA_ "GenSigSendType" SG_ 1567 EVCC_DiagRespData31 1;
BA_ "GenSigSendType" SG_ 1567 EVCC_DiagRespData32 1;
BA_ "GenSigSendType" SG_ 1567 EVCC_DiagRespData33 1;
BA_ "GenSigSendType" SG_ 1567 EVCC_DiagRespData34 1;
BA_ "GenSigSendType" SG_ 1567 EVCC_DiagRespData35 1;
BA_ "GenSigSendType" SG_ 1567 EVCC_DiagRespData36 1;
BA_ "GenSigSendType" SG_ 1567 EVCC_DiagRespData37 1;
BA_ "GenSigSendType" SG_ 1567 EVCC_DiagRespData38 1;
BA_ "GenSigSendType" SG_ 1567 EVCC_DiagRespData39 1;
BA_ "GenSigSendType" SG_ 1567 EVCC_DiagRespData40 1;
BA_ "GenSigSendType" SG_ 1567 EVCC_DiagRespData41 1;
BA_ "GenSigSendType" SG_ 1567 EVCC_DiagRespData42 1;
BA_ "GenSigSendType" SG_ 1567 EVCC_DiagRespData43 1;
BA_ "GenSigSendType" SG_ 1567 EVCC_DiagRespData44 1;
BA_ "GenSigSendType" SG_ 1567 EVCC_DiagRespData45 1;
BA_ "GenSigSendType" SG_ 1567 EVCC_DiagRespData46 1;
BA_ "GenSigSendType" SG_ 1567 EVCC_DiagRespData47 1;
BA_ "GenSigSendType" SG_ 1567 EVCC_DiagRespData48 1;
BA_ "GenSigSendType" SG_ 1567 EVCC_DiagRespData49 1;
BA_ "GenSigSendType" SG_ 1567 EVCC_DiagRespData50 1;
BA_ "GenSigSendType" SG_ 1567 EVCC_DiagRespData51 1;
BA_ "GenSigSendType" SG_ 1567 EVCC_DiagRespData52 1;
BA_ "GenSigSendType" SG_ 1567 EVCC_DiagRespData53 1;
BA_ "GenSigSendType" SG_ 1567 EVCC_DiagRespData54 1;
BA_ "GenSigSendType" SG_ 1567 EVCC_DiagRespData55 1;
BA_ "GenSigSendType" SG_ 1567 EVCC_DiagRespData56 1;
BA_ "GenSigSendType" SG_ 1567 EVCC_DiagRespData57 1;
BA_ "GenSigSendType" SG_ 1567 EVCC_DiagRespData58 1;
BA_ "GenSigSendType" SG_ 1567 EVCC_DiagRespData59 1;
BA_ "GenSigSendType" SG_ 1567 EVCC_DiagRespData60 1;
BA_ "GenSigSendType" SG_ 1567 EVCC_DiagRespData61 1;
BA_ "GenSigSendType" SG_ 1567 EVCC_DiagRespData62 1;
BA_ "GenSigSendType" SG_ 1567 EVCC_DiagRespData63 1;
BA_ "GenSigSendType" SG_ 1725 POD_DCDC_DiagReqData0 1;
BA_ "GenSigSendType" SG_ 1725 POD_DCDC_DiagReqData1 1;
BA_ "GenSigSendType" SG_ 1725 POD_DCDC_DiagReqData2 1;
BA_ "GenSigSendType" SG_ 1725 POD_DCDC_DiagReqData3 1;
BA_ "GenSigSendType" SG_ 1725 POD_DCDC_DiagReqData4 1;
BA_ "GenSigSendType" SG_ 1725 POD_DCDC_DiagReqData5 1;
BA_ "GenSigSendType" SG_ 1725 POD_DCDC_DiagReqData6 1;
BA_ "GenSigSendType" SG_ 1725 POD_DCDC_DiagReqData7 1;
BA_ "GenSigSendType" SG_ 1725 POD_DCDC_DiagReqData8 1;
BA_ "GenSigSendType" SG_ 1725 POD_DCDC_DiagReqData9 1;
BA_ "GenSigSendType" SG_ 1725 POD_DCDC_DiagReqData10 1;
BA_ "GenSigSendType" SG_ 1725 POD_DCDC_DiagReqData11 1;
BA_ "GenSigSendType" SG_ 1725 POD_DCDC_DiagReqData12 1;
BA_ "GenSigSendType" SG_ 1725 POD_DCDC_DiagReqData13 1;
BA_ "GenSigSendType" SG_ 1725 POD_DCDC_DiagReqData14 1;
BA_ "GenSigSendType" SG_ 1725 POD_DCDC_DiagReqData15 1;
BA_ "GenSigSendType" SG_ 1725 POD_DCDC_DiagReqData16 1;
BA_ "GenSigSendType" SG_ 1725 POD_DCDC_DiagReqData17 1;
BA_ "GenSigSendType" SG_ 1725 POD_DCDC_DiagReqData18 1;
BA_ "GenSigSendType" SG_ 1725 POD_DCDC_DiagReqData19 1;
BA_ "GenSigSendType" SG_ 1725 POD_DCDC_DiagReqData20 1;
BA_ "GenSigSendType" SG_ 1725 POD_DCDC_DiagReqData21 1;
BA_ "GenSigSendType" SG_ 1725 POD_DCDC_DiagReqData22 1;
BA_ "GenSigSendType" SG_ 1725 POD_DCDC_DiagReqData23 1;
BA_ "GenSigSendType" SG_ 1725 POD_DCDC_DiagReqData24 1;
BA_ "GenSigSendType" SG_ 1725 POD_DCDC_DiagReqData25 1;
BA_ "GenSigSendType" SG_ 1725 POD_DCDC_DiagReqData26 1;
BA_ "GenSigSendType" SG_ 1725 POD_DCDC_DiagReqData27 1;
BA_ "GenSigSendType" SG_ 1725 POD_DCDC_DiagReqData28 1;
BA_ "GenSigSendType" SG_ 1725 POD_DCDC_DiagReqData29 1;
BA_ "GenSigSendType" SG_ 1725 POD_DCDC_DiagReqData30 1;
BA_ "GenSigSendType" SG_ 1725 POD_DCDC_DiagReqData31 1;
BA_ "GenSigSendType" SG_ 1725 POD_DCDC_DiagReqData32 1;
BA_ "GenSigSendType" SG_ 1725 POD_DCDC_DiagReqData33 1;
BA_ "GenSigSendType" SG_ 1725 POD_DCDC_DiagReqData34 1;
BA_ "GenSigSendType" SG_ 1725 POD_DCDC_DiagReqData35 1;
BA_ "GenSigSendType" SG_ 1725 POD_DCDC_DiagReqData36 1;
BA_ "GenSigSendType" SG_ 1725 POD_DCDC_DiagReqData37 1;
BA_ "GenSigSendType" SG_ 1725 POD_DCDC_DiagReqData38 1;
BA_ "GenSigSendType" SG_ 1725 POD_DCDC_DiagReqData39 1;
BA_ "GenSigSendType" SG_ 1725 POD_DCDC_DiagReqData40 1;
BA_ "GenSigSendType" SG_ 1725 POD_DCDC_DiagReqData41 1;
BA_ "GenSigSendType" SG_ 1725 POD_DCDC_DiagReqData42 1;
BA_ "GenSigSendType" SG_ 1725 POD_DCDC_DiagReqData43 1;
BA_ "GenSigSendType" SG_ 1725 POD_DCDC_DiagReqData44 1;
BA_ "GenSigSendType" SG_ 1725 POD_DCDC_DiagReqData45 1;
BA_ "GenSigSendType" SG_ 1725 POD_DCDC_DiagReqData46 1;
BA_ "GenSigSendType" SG_ 1725 POD_DCDC_DiagReqData47 1;
BA_ "GenSigSendType" SG_ 1725 POD_DCDC_DiagReqData48 1;
BA_ "GenSigSendType" SG_ 1725 POD_DCDC_DiagReqData49 1;
BA_ "GenSigSendType" SG_ 1725 POD_DCDC_DiagReqData50 1;
BA_ "GenSigSendType" SG_ 1725 POD_DCDC_DiagReqData51 1;
BA_ "GenSigSendType" SG_ 1725 POD_DCDC_DiagReqData52 1;
BA_ "GenSigSendType" SG_ 1725 POD_DCDC_DiagReqData53 1;
BA_ "GenSigSendType" SG_ 1725 POD_DCDC_DiagReqData54 1;
BA_ "GenSigSendType" SG_ 1725 POD_DCDC_DiagReqData55 1;
BA_ "GenSigSendType" SG_ 1725 POD_DCDC_DiagReqData56 1;
BA_ "GenSigSendType" SG_ 1725 POD_DCDC_DiagReqData57 1;
BA_ "GenSigSendType" SG_ 1725 POD_DCDC_DiagReqData58 1;
BA_ "GenSigSendType" SG_ 1725 POD_DCDC_DiagReqData59 1;
BA_ "GenSigSendType" SG_ 1725 POD_DCDC_DiagReqData60 1;
BA_ "GenSigSendType" SG_ 1725 POD_DCDC_DiagReqData61 1;
BA_ "GenSigSendType" SG_ 1725 POD_DCDC_DiagReqData62 1;
BA_ "GenSigSendType" SG_ 1725 POD_DCDC_DiagReqData63 1;
BA_ "GenSigSendType" SG_ 1597 POD_DCDC_DiagRespData0 1;
BA_ "GenSigSendType" SG_ 1597 POD_DCDC_DiagRespData1 1;
BA_ "GenSigSendType" SG_ 1597 POD_DCDC_DiagRespData2 1;
BA_ "GenSigSendType" SG_ 1597 POD_DCDC_DiagRespData3 1;
BA_ "GenSigSendType" SG_ 1597 POD_DCDC_DiagRespData4 1;
BA_ "GenSigSendType" SG_ 1597 POD_DCDC_DiagRespData5 1;
BA_ "GenSigSendType" SG_ 1597 POD_DCDC_DiagRespData6 1;
BA_ "GenSigSendType" SG_ 1597 POD_DCDC_DiagRespData7 1;
BA_ "GenSigSendType" SG_ 1597 POD_DCDC_DiagRespData8 1;
BA_ "GenSigSendType" SG_ 1597 POD_DCDC_DiagRespData9 1;
BA_ "GenSigSendType" SG_ 1597 POD_DCDC_DiagRespData10 1;
BA_ "GenSigSendType" SG_ 1597 POD_DCDC_DiagRespData11 1;
BA_ "GenSigSendType" SG_ 1597 POD_DCDC_DiagRespData12 1;
BA_ "GenSigSendType" SG_ 1597 POD_DCDC_DiagRespData13 1;
BA_ "GenSigSendType" SG_ 1597 POD_DCDC_DiagRespData14 1;
BA_ "GenSigSendType" SG_ 1597 POD_DCDC_DiagRespData15 1;
BA_ "GenSigSendType" SG_ 1597 POD_DCDC_DiagRespData16 1;
BA_ "GenSigSendType" SG_ 1597 POD_DCDC_DiagRespData17 1;
BA_ "GenSigSendType" SG_ 1597 POD_DCDC_DiagRespData18 1;
BA_ "GenSigSendType" SG_ 1597 POD_DCDC_DiagRespData19 1;
BA_ "GenSigSendType" SG_ 1597 POD_DCDC_DiagRespData20 1;
BA_ "GenSigSendType" SG_ 1597 POD_DCDC_DiagRespData21 1;
BA_ "GenSigSendType" SG_ 1597 POD_DCDC_DiagRespData22 1;
BA_ "GenSigSendType" SG_ 1597 POD_DCDC_DiagRespData23 1;
BA_ "GenSigSendType" SG_ 1597 POD_DCDC_DiagRespData24 1;
BA_ "GenSigSendType" SG_ 1597 POD_DCDC_DiagRespData25 1;
BA_ "GenSigSendType" SG_ 1597 POD_DCDC_DiagRespData26 1;
BA_ "GenSigSendType" SG_ 1597 POD_DCDC_DiagRespData27 1;
BA_ "GenSigSendType" SG_ 1597 POD_DCDC_DiagRespData28 1;
BA_ "GenSigSendType" SG_ 1597 POD_DCDC_DiagRespData29 1;
BA_ "GenSigSendType" SG_ 1597 POD_DCDC_DiagRespData30 1;
BA_ "GenSigSendType" SG_ 1597 POD_DCDC_DiagRespData31 1;
BA_ "GenSigSendType" SG_ 1597 POD_DCDC_DiagRespData32 1;
BA_ "GenSigSendType" SG_ 1597 POD_DCDC_DiagRespData33 1;
BA_ "GenSigSendType" SG_ 1597 POD_DCDC_DiagRespData34 1;
BA_ "GenSigSendType" SG_ 1597 POD_DCDC_DiagRespData35 1;
BA_ "GenSigSendType" SG_ 1597 POD_DCDC_DiagRespData36 1;
BA_ "GenSigSendType" SG_ 1597 POD_DCDC_DiagRespData37 1;
BA_ "GenSigSendType" SG_ 1597 POD_DCDC_DiagRespData38 1;
BA_ "GenSigSendType" SG_ 1597 POD_DCDC_DiagRespData39 1;
BA_ "GenSigSendType" SG_ 1597 POD_DCDC_DiagRespData40 1;
BA_ "GenSigSendType" SG_ 1597 POD_DCDC_DiagRespData41 1;
BA_ "GenSigSendType" SG_ 1597 POD_DCDC_DiagRespData42 1;
BA_ "GenSigSendType" SG_ 1597 POD_DCDC_DiagRespData43 1;
BA_ "GenSigSendType" SG_ 1597 POD_DCDC_DiagRespData44 1;
BA_ "GenSigSendType" SG_ 1597 POD_DCDC_DiagRespData45 1;
BA_ "GenSigSendType" SG_ 1597 POD_DCDC_DiagRespData46 1;
BA_ "GenSigSendType" SG_ 1597 POD_DCDC_DiagRespData47 1;
BA_ "GenSigSendType" SG_ 1597 POD_DCDC_DiagRespData48 1;
BA_ "GenSigSendType" SG_ 1597 POD_DCDC_DiagRespData49 1;
BA_ "GenSigSendType" SG_ 1597 POD_DCDC_DiagRespData50 1;
BA_ "GenSigSendType" SG_ 1597 POD_DCDC_DiagRespData51 1;
BA_ "GenSigSendType" SG_ 1597 POD_DCDC_DiagRespData52 1;
BA_ "GenSigSendType" SG_ 1597 POD_DCDC_DiagRespData53 1;
BA_ "GenSigSendType" SG_ 1597 POD_DCDC_DiagRespData54 1;
BA_ "GenSigSendType" SG_ 1597 POD_DCDC_DiagRespData55 1;
BA_ "GenSigSendType" SG_ 1597 POD_DCDC_DiagRespData56 1;
BA_ "GenSigSendType" SG_ 1597 POD_DCDC_DiagRespData57 1;
BA_ "GenSigSendType" SG_ 1597 POD_DCDC_DiagRespData58 1;
BA_ "GenSigSendType" SG_ 1597 POD_DCDC_DiagRespData59 1;
BA_ "GenSigSendType" SG_ 1597 POD_DCDC_DiagRespData60 1;
BA_ "GenSigSendType" SG_ 1597 POD_DCDC_DiagRespData61 1;
BA_ "GenSigSendType" SG_ 1597 POD_DCDC_DiagRespData62 1;
BA_ "GenSigSendType" SG_ 1597 POD_DCDC_DiagRespData63 1;
BA_ "GenSigSendType" SG_ 1726 POD_OBC_DiagReqData0 1;
BA_ "GenSigSendType" SG_ 1726 POD_OBC_DiagReqData1 1;
BA_ "GenSigSendType" SG_ 1726 POD_OBC_DiagReqData2 1;
BA_ "GenSigSendType" SG_ 1726 POD_OBC_DiagReqData3 1;
BA_ "GenSigSendType" SG_ 1726 POD_OBC_DiagReqData4 1;
BA_ "GenSigSendType" SG_ 1726 POD_OBC_DiagReqData5 1;
BA_ "GenSigSendType" SG_ 1726 POD_OBC_DiagReqData6 1;
BA_ "GenSigSendType" SG_ 1726 POD_OBC_DiagReqData7 1;
BA_ "GenSigSendType" SG_ 1726 POD_OBC_DiagReqData8 1;
BA_ "GenSigSendType" SG_ 1726 POD_OBC_DiagReqData9 1;
BA_ "GenSigSendType" SG_ 1726 POD_OBC_DiagReqData10 1;
BA_ "GenSigSendType" SG_ 1726 POD_OBC_DiagReqData11 1;
BA_ "GenSigSendType" SG_ 1726 POD_OBC_DiagReqData12 1;
BA_ "GenSigSendType" SG_ 1726 POD_OBC_DiagReqData13 1;
BA_ "GenSigSendType" SG_ 1726 POD_OBC_DiagReqData14 1;
BA_ "GenSigSendType" SG_ 1726 POD_OBC_DiagReqData15 1;
BA_ "GenSigSendType" SG_ 1726 POD_OBC_DiagReqData16 1;
BA_ "GenSigSendType" SG_ 1726 POD_OBC_DiagReqData17 1;
BA_ "GenSigSendType" SG_ 1726 POD_OBC_DiagReqData18 1;
BA_ "GenSigSendType" SG_ 1726 POD_OBC_DiagReqData19 1;
BA_ "GenSigSendType" SG_ 1726 POD_OBC_DiagReqData20 1;
BA_ "GenSigSendType" SG_ 1726 POD_OBC_DiagReqData21 1;
BA_ "GenSigSendType" SG_ 1726 POD_OBC_DiagReqData22 1;
BA_ "GenSigSendType" SG_ 1726 POD_OBC_DiagReqData23 1;
BA_ "GenSigSendType" SG_ 1726 POD_OBC_DiagReqData24 1;
BA_ "GenSigSendType" SG_ 1726 POD_OBC_DiagReqData25 1;
BA_ "GenSigSendType" SG_ 1726 POD_OBC_DiagReqData26 1;
BA_ "GenSigSendType" SG_ 1726 POD_OBC_DiagReqData27 1;
BA_ "GenSigSendType" SG_ 1726 POD_OBC_DiagReqData28 1;
BA_ "GenSigSendType" SG_ 1726 POD_OBC_DiagReqData29 1;
BA_ "GenSigSendType" SG_ 1726 POD_OBC_DiagReqData30 1;
BA_ "GenSigSendType" SG_ 1726 POD_OBC_DiagReqData31 1;
BA_ "GenSigSendType" SG_ 1726 POD_OBC_DiagReqData32 1;
BA_ "GenSigSendType" SG_ 1726 POD_OBC_DiagReqData33 1;
BA_ "GenSigSendType" SG_ 1726 POD_OBC_DiagReqData34 1;
BA_ "GenSigSendType" SG_ 1726 POD_OBC_DiagReqData35 1;
BA_ "GenSigSendType" SG_ 1726 POD_OBC_DiagReqData36 1;
BA_ "GenSigSendType" SG_ 1726 POD_OBC_DiagReqData37 1;
BA_ "GenSigSendType" SG_ 1726 POD_OBC_DiagReqData38 1;
BA_ "GenSigSendType" SG_ 1726 POD_OBC_DiagReqData39 1;
BA_ "GenSigSendType" SG_ 1726 POD_OBC_DiagReqData40 1;
BA_ "GenSigSendType" SG_ 1726 POD_OBC_DiagReqData41 1;
BA_ "GenSigSendType" SG_ 1726 POD_OBC_DiagReqData42 1;
BA_ "GenSigSendType" SG_ 1726 POD_OBC_DiagReqData43 1;
BA_ "GenSigSendType" SG_ 1726 POD_OBC_DiagReqData44 1;
BA_ "GenSigSendType" SG_ 1726 POD_OBC_DiagReqData45 1;
BA_ "GenSigSendType" SG_ 1726 POD_OBC_DiagReqData46 1;
BA_ "GenSigSendType" SG_ 1726 POD_OBC_DiagReqData47 1;
BA_ "GenSigSendType" SG_ 1726 POD_OBC_DiagReqData48 1;
BA_ "GenSigSendType" SG_ 1726 POD_OBC_DiagReqData49 1;
BA_ "GenSigSendType" SG_ 1726 POD_OBC_DiagReqData50 1;
BA_ "GenSigSendType" SG_ 1726 POD_OBC_DiagReqData51 1;
BA_ "GenSigSendType" SG_ 1726 POD_OBC_DiagReqData52 1;
BA_ "GenSigSendType" SG_ 1726 POD_OBC_DiagReqData53 1;
BA_ "GenSigSendType" SG_ 1726 POD_OBC_DiagReqData54 1;
BA_ "GenSigSendType" SG_ 1726 POD_OBC_DiagReqData55 1;
BA_ "GenSigSendType" SG_ 1726 POD_OBC_DiagReqData56 1;
BA_ "GenSigSendType" SG_ 1726 POD_OBC_DiagReqData57 1;
BA_ "GenSigSendType" SG_ 1726 POD_OBC_DiagReqData58 1;
BA_ "GenSigSendType" SG_ 1726 POD_OBC_DiagReqData59 1;
BA_ "GenSigSendType" SG_ 1726 POD_OBC_DiagReqData60 1;
BA_ "GenSigSendType" SG_ 1726 POD_OBC_DiagReqData61 1;
BA_ "GenSigSendType" SG_ 1726 POD_OBC_DiagReqData62 1;
BA_ "GenSigSendType" SG_ 1726 POD_OBC_DiagReqData63 1;
BA_ "GenSigSendType" SG_ 1598 POD_OBC_DiagRespData0 1;
BA_ "GenSigSendType" SG_ 1598 POD_OBC_DiagRespData1 1;
BA_ "GenSigSendType" SG_ 1598 POD_OBC_DiagRespData2 1;
BA_ "GenSigSendType" SG_ 1598 POD_OBC_DiagRespData3 1;
BA_ "GenSigSendType" SG_ 1598 POD_OBC_DiagRespData4 1;
BA_ "GenSigSendType" SG_ 1598 POD_OBC_DiagRespData5 1;
BA_ "GenSigSendType" SG_ 1598 POD_OBC_DiagRespData6 1;
BA_ "GenSigSendType" SG_ 1598 POD_OBC_DiagRespData7 1;
BA_ "GenSigSendType" SG_ 1598 POD_OBC_DiagRespData8 1;
BA_ "GenSigSendType" SG_ 1598 POD_OBC_DiagRespData9 1;
BA_ "GenSigSendType" SG_ 1598 POD_OBC_DiagRespData10 1;
BA_ "GenSigSendType" SG_ 1598 POD_OBC_DiagRespData11 1;
BA_ "GenSigSendType" SG_ 1598 POD_OBC_DiagRespData12 1;
BA_ "GenSigSendType" SG_ 1598 POD_OBC_DiagRespData13 1;
BA_ "GenSigSendType" SG_ 1598 POD_OBC_DiagRespData14 1;
BA_ "GenSigSendType" SG_ 1598 POD_OBC_DiagRespData15 1;
BA_ "GenSigSendType" SG_ 1598 POD_OBC_DiagRespData16 1;
BA_ "GenSigSendType" SG_ 1598 POD_OBC_DiagRespData17 1;
BA_ "GenSigSendType" SG_ 1598 POD_OBC_DiagRespData18 1;
BA_ "GenSigSendType" SG_ 1598 POD_OBC_DiagRespData19 1;
BA_ "GenSigSendType" SG_ 1598 POD_OBC_DiagRespData20 1;
BA_ "GenSigSendType" SG_ 1598 POD_OBC_DiagRespData21 1;
BA_ "GenSigSendType" SG_ 1598 POD_OBC_DiagRespData22 1;
BA_ "GenSigSendType" SG_ 1598 POD_OBC_DiagRespData23 1;
BA_ "GenSigSendType" SG_ 1598 POD_OBC_DiagRespData24 1;
BA_ "GenSigSendType" SG_ 1598 POD_OBC_DiagRespData25 1;
BA_ "GenSigSendType" SG_ 1598 POD_OBC_DiagRespData26 1;
BA_ "GenSigSendType" SG_ 1598 POD_OBC_DiagRespData27 1;
BA_ "GenSigSendType" SG_ 1598 POD_OBC_DiagRespData28 1;
BA_ "GenSigSendType" SG_ 1598 POD_OBC_DiagRespData29 1;
BA_ "GenSigSendType" SG_ 1598 POD_OBC_DiagRespData30 1;
BA_ "GenSigSendType" SG_ 1598 POD_OBC_DiagRespData31 1;
BA_ "GenSigSendType" SG_ 1598 POD_OBC_DiagRespData32 1;
BA_ "GenSigSendType" SG_ 1598 POD_OBC_DiagRespData33 1;
BA_ "GenSigSendType" SG_ 1598 POD_OBC_DiagRespData34 1;
BA_ "GenSigSendType" SG_ 1598 POD_OBC_DiagRespData35 1;
BA_ "GenSigSendType" SG_ 1598 POD_OBC_DiagRespData36 1;
BA_ "GenSigSendType" SG_ 1598 POD_OBC_DiagRespData37 1;
BA_ "GenSigSendType" SG_ 1598 POD_OBC_DiagRespData38 1;
BA_ "GenSigSendType" SG_ 1598 POD_OBC_DiagRespData39 1;
BA_ "GenSigSendType" SG_ 1598 POD_OBC_DiagRespData40 1;
BA_ "GenSigSendType" SG_ 1598 POD_OBC_DiagRespData41 1;
BA_ "GenSigSendType" SG_ 1598 POD_OBC_DiagRespData42 1;
BA_ "GenSigSendType" SG_ 1598 POD_OBC_DiagRespData43 1;
BA_ "GenSigSendType" SG_ 1598 POD_OBC_DiagRespData44 1;
BA_ "GenSigSendType" SG_ 1598 POD_OBC_DiagRespData45 1;
BA_ "GenSigSendType" SG_ 1598 POD_OBC_DiagRespData46 1;
BA_ "GenSigSendType" SG_ 1598 POD_OBC_DiagRespData47 1;
BA_ "GenSigSendType" SG_ 1598 POD_OBC_DiagRespData48 1;
BA_ "GenSigSendType" SG_ 1598 POD_OBC_DiagRespData49 1;
BA_ "GenSigSendType" SG_ 1598 POD_OBC_DiagRespData50 1;
BA_ "GenSigSendType" SG_ 1598 POD_OBC_DiagRespData51 1;
BA_ "GenSigSendType" SG_ 1598 POD_OBC_DiagRespData52 1;
BA_ "GenSigSendType" SG_ 1598 POD_OBC_DiagRespData53 1;
BA_ "GenSigSendType" SG_ 1598 POD_OBC_DiagRespData54 1;
BA_ "GenSigSendType" SG_ 1598 POD_OBC_DiagRespData55 1;
BA_ "GenSigSendType" SG_ 1598 POD_OBC_DiagRespData56 1;
BA_ "GenSigSendType" SG_ 1598 POD_OBC_DiagRespData57 1;
BA_ "GenSigSendType" SG_ 1598 POD_OBC_DiagRespData58 1;
BA_ "GenSigSendType" SG_ 1598 POD_OBC_DiagRespData59 1;
BA_ "GenSigSendType" SG_ 1598 POD_OBC_DiagRespData60 1;
BA_ "GenSigSendType" SG_ 1598 POD_OBC_DiagRespData61 1;
BA_ "GenSigSendType" SG_ 1598 POD_OBC_DiagRespData62 1;
BA_ "GenSigSendType" SG_ 1598 POD_OBC_DiagRespData63 1;
BA_ "GenSigSendType" SG_ 1720 PCU_DiagReqData0 1;
BA_ "GenSigSendType" SG_ 1720 PCU_DiagReqData1 1;
BA_ "GenSigSendType" SG_ 1720 PCU_DiagReqData2 1;
BA_ "GenSigSendType" SG_ 1720 PCU_DiagReqData3 1;
BA_ "GenSigSendType" SG_ 1720 PCU_DiagReqData4 1;
BA_ "GenSigSendType" SG_ 1720 PCU_DiagReqData5 1;
BA_ "GenSigSendType" SG_ 1720 PCU_DiagReqData6 1;
BA_ "GenSigSendType" SG_ 1720 PCU_DiagReqData7 1;
BA_ "GenSigSendType" SG_ 1720 PCU_DiagReqData8 1;
BA_ "GenSigSendType" SG_ 1720 PCU_DiagReqData9 1;
BA_ "GenSigSendType" SG_ 1720 PCU_DiagReqData10 1;
BA_ "GenSigSendType" SG_ 1720 PCU_DiagReqData11 1;
BA_ "GenSigSendType" SG_ 1720 PCU_DiagReqData12 1;
BA_ "GenSigSendType" SG_ 1720 PCU_DiagReqData13 1;
BA_ "GenSigSendType" SG_ 1720 PCU_DiagReqData14 1;
BA_ "GenSigSendType" SG_ 1720 PCU_DiagReqData15 1;
BA_ "GenSigSendType" SG_ 1720 PCU_DiagReqData16 1;
BA_ "GenSigSendType" SG_ 1720 PCU_DiagReqData17 1;
BA_ "GenSigSendType" SG_ 1720 PCU_DiagReqData18 1;
BA_ "GenSigSendType" SG_ 1720 PCU_DiagReqData19 1;
BA_ "GenSigSendType" SG_ 1720 PCU_DiagReqData20 1;
BA_ "GenSigSendType" SG_ 1720 PCU_DiagReqData21 1;
BA_ "GenSigSendType" SG_ 1720 PCU_DiagReqData22 1;
BA_ "GenSigSendType" SG_ 1720 PCU_DiagReqData23 1;
BA_ "GenSigSendType" SG_ 1720 PCU_DiagReqData24 1;
BA_ "GenSigSendType" SG_ 1720 PCU_DiagReqData25 1;
BA_ "GenSigSendType" SG_ 1720 PCU_DiagReqData26 1;
BA_ "GenSigSendType" SG_ 1720 PCU_DiagReqData27 1;
BA_ "GenSigSendType" SG_ 1720 PCU_DiagReqData28 1;
BA_ "GenSigSendType" SG_ 1720 PCU_DiagReqData29 1;
BA_ "GenSigSendType" SG_ 1720 PCU_DiagReqData30 1;
BA_ "GenSigSendType" SG_ 1720 PCU_DiagReqData31 1;
BA_ "GenSigSendType" SG_ 1720 PCU_DiagReqData32 1;
BA_ "GenSigSendType" SG_ 1720 PCU_DiagReqData33 1;
BA_ "GenSigSendType" SG_ 1720 PCU_DiagReqData34 1;
BA_ "GenSigSendType" SG_ 1720 PCU_DiagReqData35 1;
BA_ "GenSigSendType" SG_ 1720 PCU_DiagReqData36 1;
BA_ "GenSigSendType" SG_ 1720 PCU_DiagReqData37 1;
BA_ "GenSigSendType" SG_ 1720 PCU_DiagReqData38 1;
BA_ "GenSigSendType" SG_ 1720 PCU_DiagReqData39 1;
BA_ "GenSigSendType" SG_ 1720 PCU_DiagReqData40 1;
BA_ "GenSigSendType" SG_ 1720 PCU_DiagReqData41 1;
BA_ "GenSigSendType" SG_ 1720 PCU_DiagReqData42 1;
BA_ "GenSigSendType" SG_ 1720 PCU_DiagReqData43 1;
BA_ "GenSigSendType" SG_ 1720 PCU_DiagReqData44 1;
BA_ "GenSigSendType" SG_ 1720 PCU_DiagReqData45 1;
BA_ "GenSigSendType" SG_ 1720 PCU_DiagReqData46 1;
BA_ "GenSigSendType" SG_ 1720 PCU_DiagReqData47 1;
BA_ "GenSigSendType" SG_ 1720 PCU_DiagReqData48 1;
BA_ "GenSigSendType" SG_ 1720 PCU_DiagReqData49 1;
BA_ "GenSigSendType" SG_ 1720 PCU_DiagReqData50 1;
BA_ "GenSigSendType" SG_ 1720 PCU_DiagReqData51 1;
BA_ "GenSigSendType" SG_ 1720 PCU_DiagReqData52 1;
BA_ "GenSigSendType" SG_ 1720 PCU_DiagReqData53 1;
BA_ "GenSigSendType" SG_ 1720 PCU_DiagReqData54 1;
BA_ "GenSigSendType" SG_ 1720 PCU_DiagReqData55 1;
BA_ "GenSigSendType" SG_ 1720 PCU_DiagReqData56 1;
BA_ "GenSigSendType" SG_ 1720 PCU_DiagReqData57 1;
BA_ "GenSigSendType" SG_ 1720 PCU_DiagReqData58 1;
BA_ "GenSigSendType" SG_ 1720 PCU_DiagReqData59 1;
BA_ "GenSigSendType" SG_ 1720 PCU_DiagReqData60 1;
BA_ "GenSigSendType" SG_ 1720 PCU_DiagReqData61 1;
BA_ "GenSigSendType" SG_ 1720 PCU_DiagReqData62 1;
BA_ "GenSigSendType" SG_ 1720 PCU_DiagReqData63 1;
BA_ "GenSigSendType" SG_ 1592 PCU_DiagRespData0 1;
BA_ "GenSigSendType" SG_ 1592 PCU_DiagRespData1 1;
BA_ "GenSigSendType" SG_ 1592 PCU_DiagRespData2 1;
BA_ "GenSigSendType" SG_ 1592 PCU_DiagRespData3 1;
BA_ "GenSigSendType" SG_ 1592 PCU_DiagRespData4 1;
BA_ "GenSigSendType" SG_ 1592 PCU_DiagRespData5 1;
BA_ "GenSigSendType" SG_ 1592 PCU_DiagRespData6 1;
BA_ "GenSigSendType" SG_ 1592 PCU_DiagRespData7 1;
BA_ "GenSigSendType" SG_ 1592 PCU_DiagRespData8 1;
BA_ "GenSigSendType" SG_ 1592 PCU_DiagRespData9 1;
BA_ "GenSigSendType" SG_ 1592 PCU_DiagRespData10 1;
BA_ "GenSigSendType" SG_ 1592 PCU_DiagRespData11 1;
BA_ "GenSigSendType" SG_ 1592 PCU_DiagRespData12 1;
BA_ "GenSigSendType" SG_ 1592 PCU_DiagRespData13 1;
BA_ "GenSigSendType" SG_ 1592 PCU_DiagRespData14 1;
BA_ "GenSigSendType" SG_ 1592 PCU_DiagRespData15 1;
BA_ "GenSigSendType" SG_ 1592 PCU_DiagRespData16 1;
BA_ "GenSigSendType" SG_ 1592 PCU_DiagRespData17 1;
BA_ "GenSigSendType" SG_ 1592 PCU_DiagRespData18 1;
BA_ "GenSigSendType" SG_ 1592 PCU_DiagRespData19 1;
BA_ "GenSigSendType" SG_ 1592 PCU_DiagRespData20 1;
BA_ "GenSigSendType" SG_ 1592 PCU_DiagRespData21 1;
BA_ "GenSigSendType" SG_ 1592 PCU_DiagRespData22 1;
BA_ "GenSigSendType" SG_ 1592 PCU_DiagRespData23 1;
BA_ "GenSigSendType" SG_ 1592 PCU_DiagRespData24 1;
BA_ "GenSigSendType" SG_ 1592 PCU_DiagRespData25 1;
BA_ "GenSigSendType" SG_ 1592 PCU_DiagRespData26 1;
BA_ "GenSigSendType" SG_ 1592 PCU_DiagRespData27 1;
BA_ "GenSigSendType" SG_ 1592 PCU_DiagRespData28 1;
BA_ "GenSigSendType" SG_ 1592 PCU_DiagRespData29 1;
BA_ "GenSigSendType" SG_ 1592 PCU_DiagRespData30 1;
BA_ "GenSigSendType" SG_ 1592 PCU_DiagRespData31 1;
BA_ "GenSigSendType" SG_ 1592 PCU_DiagRespData32 1;
BA_ "GenSigSendType" SG_ 1592 PCU_DiagRespData33 1;
BA_ "GenSigSendType" SG_ 1592 PCU_DiagRespData34 1;
BA_ "GenSigSendType" SG_ 1592 PCU_DiagRespData35 1;
BA_ "GenSigSendType" SG_ 1592 PCU_DiagRespData36 1;
BA_ "GenSigSendType" SG_ 1592 PCU_DiagRespData37 1;
BA_ "GenSigSendType" SG_ 1592 PCU_DiagRespData38 1;
BA_ "GenSigSendType" SG_ 1592 PCU_DiagRespData39 1;
BA_ "GenSigSendType" SG_ 1592 PCU_DiagRespData40 1;
BA_ "GenSigSendType" SG_ 1592 PCU_DiagRespData41 1;
BA_ "GenSigSendType" SG_ 1592 PCU_DiagRespData42 1;
BA_ "GenSigSendType" SG_ 1592 PCU_DiagRespData43 1;
BA_ "GenSigSendType" SG_ 1592 PCU_DiagRespData44 1;
BA_ "GenSigSendType" SG_ 1592 PCU_DiagRespData45 1;
BA_ "GenSigSendType" SG_ 1592 PCU_DiagRespData46 1;
BA_ "GenSigSendType" SG_ 1592 PCU_DiagRespData47 1;
BA_ "GenSigSendType" SG_ 1592 PCU_DiagRespData48 1;
BA_ "GenSigSendType" SG_ 1592 PCU_DiagRespData49 1;
BA_ "GenSigSendType" SG_ 1592 PCU_DiagRespData50 1;
BA_ "GenSigSendType" SG_ 1592 PCU_DiagRespData51 1;
BA_ "GenSigSendType" SG_ 1592 PCU_DiagRespData52 1;
BA_ "GenSigSendType" SG_ 1592 PCU_DiagRespData53 1;
BA_ "GenSigSendType" SG_ 1592 PCU_DiagRespData54 1;
BA_ "GenSigSendType" SG_ 1592 PCU_DiagRespData55 1;
BA_ "GenSigSendType" SG_ 1592 PCU_DiagRespData56 1;
BA_ "GenSigSendType" SG_ 1592 PCU_DiagRespData57 1;
BA_ "GenSigSendType" SG_ 1592 PCU_DiagRespData58 1;
BA_ "GenSigSendType" SG_ 1592 PCU_DiagRespData59 1;
BA_ "GenSigSendType" SG_ 1592 PCU_DiagRespData60 1;
BA_ "GenSigSendType" SG_ 1592 PCU_DiagRespData61 1;
BA_ "GenSigSendType" SG_ 1592 PCU_DiagRespData62 1;
BA_ "GenSigSendType" SG_ 1592 PCU_DiagRespData63 1;
BA_ "GenSigSendType" SG_ 1791 OBD_Func_DiagReqData0 1;
BA_ "GenSigSendType" SG_ 1791 OBD_Func_DiagReqData1 1;
BA_ "GenSigSendType" SG_ 1791 OBD_Func_DiagReqData2 1;
BA_ "GenSigSendType" SG_ 1791 OBD_Func_DiagReqData3 1;
BA_ "GenSigSendType" SG_ 1791 OBD_Func_DiagReqData4 1;
BA_ "GenSigSendType" SG_ 1791 OBD_Func_DiagReqData5 1;
BA_ "GenSigSendType" SG_ 1791 OBD_Func_DiagReqData6 1;
BA_ "GenSigSendType" SG_ 1791 OBD_Func_DiagReqData7 1;
